VERSION ""

NS_ :

BS_:

BU_: Vector__XXX

BO_ 2432499198 EEC9: 8 Vector__XXX
SG_ EngExhstGasRecirc2ValvePos : 0|16@1+ (0.0025,0) [0|160.6375] "%" Vector__XXX
SG_ EngExhstGasRecirc2Valve2Pos : 16|16@1+ (0.0025,0) [0|160.6375] "%" Vector__XXX
SG_ CommandedEngineFuelRailPressure : 32|16@1+ (0.00390625,0) [0|250.996] "MPa" Vector__XXX
SG_ CmdedEngFuelInjectionCtrlPress : 48|16@1+ (0.00390625,0) [0|250.996] "MPa" Vector__XXX

BO_ 2633826046 EEC10: 8 Vector__XXX
SG_ EngExhstGasRecirc2CoolIntkTemp : 0|16@1+ (0.03125,-273) [-273|1734.96875] "deg C" Vector__XXX
SG_ EngExhstGsRecirc2ClIntkGsAbsPrs : 16|16@1+ (0.5,0) [0|32127.5] "kPa" Vector__XXX
SG_ EngExhstGasRecirculation2CoolEff : 32|8@1+ (0.4,0) [0|100] "%" Vector__XXX
SG_ EngExhstGasRecirc2ClBypssActrPos : 40|8@1+ (0.4,0) [0|100] "%" Vector__XXX
SG_ EngExhstGsRecirc2CoolIntkPress : 48|16@1+ (5,0) [0|321275] "kPa" Vector__XXX

BO_ 2566717438 ET5: 8 Vector__XXX
SG_ EngExhstGasRecirc2Temperature : 0|16@1+ (0.03125,-273) [-273|1734.96875] "deg C" Vector__XXX
SG_ EngExhstGasRecirc2MixerIntkTemp : 16|16@1+ (0.03125,-273) [-273|1734.96875] "deg C" Vector__XXX

BO_ 2499608830 EFL_P10: 8 Vector__XXX
SG_ EngExhstGasRecirc2DiffPress : 0|16@1+ (0.0078125,-250) [-250|251.99] "kPa" Vector__XXX
SG_ EngExhstGasRecirc2IntkPress : 16|8@1+ (2,0) [0|500] "kPa" Vector__XXX
SG_ EngExhstGasRecirc2OtltAbsPress : 24|16@1+ (0.1,0) [0|6425.5] "kPa" Vector__XXX
SG_ EngExhstGasRecirc2IntkAbsPress : 40|16@1+ (0.1,0) [0|6425.5] "kPa" Vector__XXX
SG_ EngineCoolantPressure2 : 56|8@1+ (2,0) [0|500] "kPa" Vector__XXX

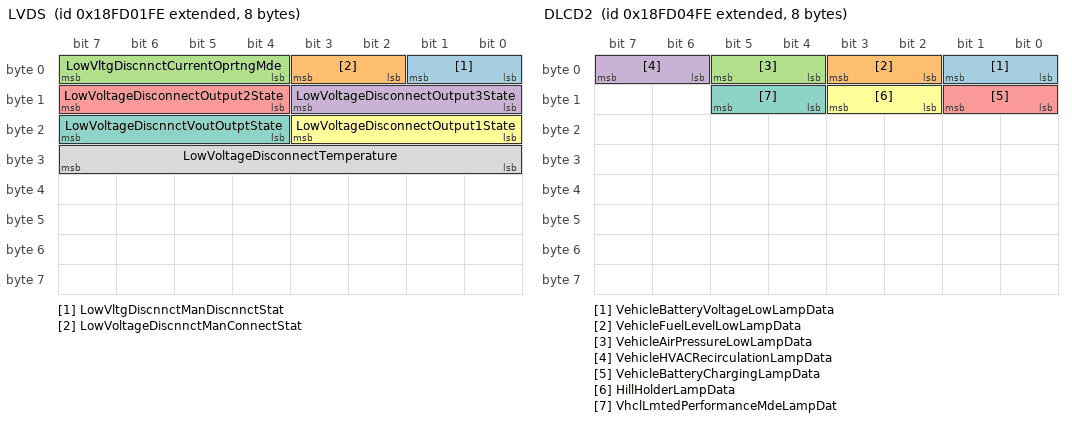
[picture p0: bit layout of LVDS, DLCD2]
BO_ 2566717950 LVDS: 8 Vector__XXX
SG_ LowVltgDiscnnctManDiscnnctStat : 0|2@1+ (1,0) [0|3] "" Vector__XXX
SG_ LowVoltageDiscnnctManConnectStat : 2|2@1+ (1,0) [0|3] "" Vector__XXX
SG_ LowVltgDiscnnctCurrentOprtngMde : 4|4@1+ (1,0) [0|15] "" Vector__XXX
SG_ LowVoltageDisconnectOutput3State : 8|4@1+ (1,0) [0|15] "" Vector__XXX
SG_ LowVoltageDisconnectOutput2State : 12|4@1+ (1,0) [0|15] "" Vector__XXX
SG_ LowVoltageDisconnectOutput1State : 16|4@1+ (1,0) [0|15] "" Vector__XXX
SG_ LowVoltageDiscnnctVoutOutptState : 20|4@1+ (1,0) [0|15] "" Vector__XXX
SG_ LowVoltageDisconnectTemperature : 24|8@1+ (1,-40) [-40|210] "deg C" Vector__XXX

BO_ 2566718206 AISO: 8 Vector__XXX
SG_ AllImplementStopOprtngOpsSwStat : 56|2@1+ (1,0) [0|3] "" Vector__XXX

BO_ 2566718462 IOS: 8 Vector__XXX
SG_ ImplementOperatingStateCommand : 56|2@1+ (1,0) [0|3] "" Vector__XXX

BO_ 2566718718 DLCD2: 8 Vector__XXX
SG_ VehicleBatteryVoltageLowLampData : 0|2@1+ (1,0) [0|3] "" Vector__XXX
SG_ VehicleFuelLevelLowLampData : 2|2@1+ (1,0) [0|3] "" Vector__XXX
SG_ VehicleAirPressureLowLampData : 4|2@1+ (1,0) [0|3] "" Vector__XXX
SG_ VehicleHVACRecirculationLampData : 6|2@1+ (1,0) [0|3] "" Vector__XXX
SG_ VehicleBatteryChargingLampData : 8|2@1+ (1,0) [0|3] "" Vector__XXX
SG_ HillHolderLampData : 10|2@1+ (1,0) [0|3] "" Vector__XXX
SG_ VhclLmtedPerformanceMdeLampDat : 12|2@1+ (1,0) [0|3] "" Vector__XXX

BO_ 2566718974 DLCD1: 8 Vector__XXX
SG_ EngineProtectLampData : 0|2@1+ (1,0) [0|3] "" Vector__XXX
SG_ EngineAmberWarningLampData : 2|2@1+ (1,0) [0|3] "" Vector__XXX
SG_ EngineRedStopLampData : 4|2@1+ (1,0) [0|3] "" Vector__XXX
SG_ OBDMalfunctionIndicatorLampData : 6|2@1+ (1,0) [0|3] "" Vector__XXX
SG_ EngineBrakeActiveLampData : 8|2@1+ (1,0) [0|3] "" Vector__XXX
SG_ ComPrsionBrkEnblSwIndictrLampDat : 10|2@1+ (1,0) [0|3] "" Vector__XXX
SG_ EngineOilPressureLowLampData : 12|2@1+ (1,0) [0|3] "" Vector__XXX
SG_ EngCoolntTemperatureHighLampDat : 14|2@1+ (1,0) [0|3] "" Vector__XXX
SG_ EngineCoolantLevelLowLampData : 16|2@1+ (1,0) [0|3] "" Vector__XXX
SG_ EngineIdleManagementActvLampData : 18|2@1+ (1,0) [0|3] "" Vector__XXX
SG_ EngAirFilterRestrictionLampDat : 20|2@1+ (1,0) [0|3] "" Vector__XXX
SG_ EngFuelFilterRestrictedLampDat : 22|2@1+ (1,0) [0|3] "" Vector__XXX
SG_ EngCtrlModule1ReadyForUseLampDat : 24|2@1+ (1,0) [0|3] "" Vector__XXX
SG_ EngCtrlModule2ReadyForUseLampDat : 26|2@1+ (1,0) [0|3] "" Vector__XXX
SG_ EngCtrlModule3ReadyForUseLampDat : 28|2@1+ (1,0) [0|3] "" Vector__XXX
SG_ EngineSpeedHighLampData : 30|2@1+ (1,0) [0|3] "" Vector__XXX
SG_ EngineSpeedVeryHighLampData : 32|2@1+ (1,0) [0|3] "" Vector__XXX
SG_ VehicleAccltnRateLimitLampData : 34|2@1+ (1,0) [0|3] "" Vector__XXX
SG_ EngStopStartAutoStopActvLampDat : 38|2@1+ (1,0) [0|3] "" Vector__XXX
SG_ EngStopStrtAutoStrtFailedLampDat : 40|2@1+ (1,0) [0|3] "" Vector__XXX
SG_ EngineStopStartEnabledLampData : 42|2@1+ (1,0) [0|3] "" Vector__XXX
SG_ EngineWaitToStartLampData : 62|2@1+ (1,0) [0|3] "" Vector__XXX

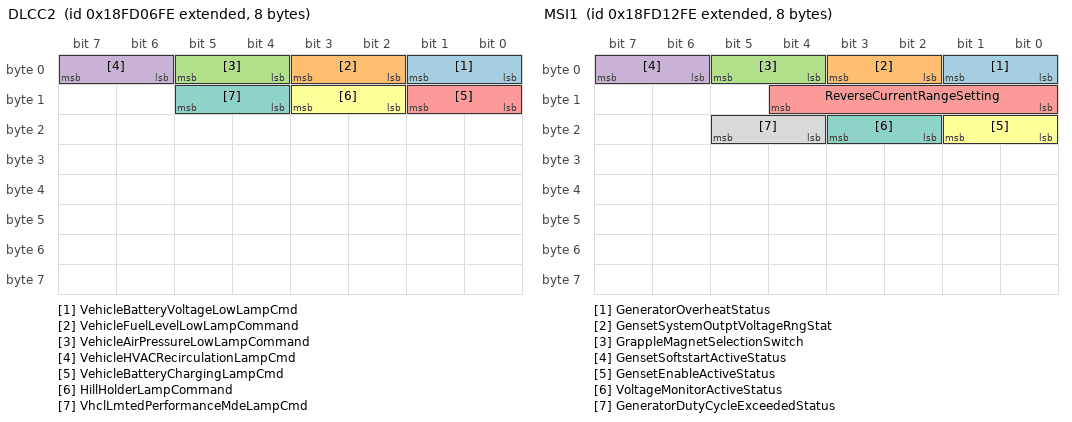
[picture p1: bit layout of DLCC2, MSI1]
BO_ 2566719230 DLCC2: 8 Vector__XXX
SG_ VehicleBatteryVoltageLowLampCmd : 0|2@1+ (1,0) [0|3] "" Vector__XXX
SG_ VehicleFuelLevelLowLampCommand : 2|2@1+ (1,0) [0|3] "" Vector__XXX
SG_ VehicleAirPressureLowLampCommand : 4|2@1+ (1,0) [0|3] "" Vector__XXX
SG_ VehicleHVACRecirculationLampCmd : 6|2@1+ (1,0) [0|3] "" Vector__XXX
SG_ VehicleBatteryChargingLampCmd : 8|2@1+ (1,0) [0|3] "" Vector__XXX
SG_ HillHolderLampCommand : 10|2@1+ (1,0) [0|3] "" Vector__XXX
SG_ VhclLmtedPerformanceMdeLampCmd : 12|2@1+ (1,0) [0|3] "" Vector__XXX

BO_ 2566719486 DLCC1: 8 Vector__XXX
SG_ EngineProtectLampCommand : 0|2@1+ (1,0) [0|3] "" Vector__XXX
SG_ EngineAmberWarningLampCommand : 2|2@1+ (1,0) [0|3] "" Vector__XXX
SG_ EngineRedStopLampCommand : 4|2@1+ (1,0) [0|3] "" Vector__XXX
SG_ OBDMalfunctionIndicatorLampCmd : 6|2@1+ (1,0) [0|3] "" Vector__XXX
SG_ EngineBrakeActiveLampCommand : 8|2@1+ (1,0) [0|3] "" Vector__XXX
SG_ ComPrsionBrkEnblSwIndictrLampCmd : 10|2@1+ (1,0) [0|3] "" Vector__XXX
SG_ EngineOilPressureLowLampCommand : 12|2@1+ (1,0) [0|3] "" Vector__XXX
SG_ EngCoolntTemperatureHighLampCmd : 14|2@1+ (1,0) [0|3] "" Vector__XXX
SG_ EngineCoolantLevelLowLampCommand : 16|2@1+ (1,0) [0|3] "" Vector__XXX
SG_ EngineIdleManagementActvLampCmd : 18|2@1+ (1,0) [0|3] "" Vector__XXX
SG_ EngAirFilterRestrictionLampCmd : 20|2@1+ (1,0) [0|3] "" Vector__XXX
SG_ EngFuelFilterRestrictedLampCmd : 22|2@1+ (1,0) [0|3] "" Vector__XXX
SG_ EngCtrlModule1ReadyForUseLampCmd : 24|2@1+ (1,0) [0|3] "" Vector__XXX
SG_ EngCtrlModule2ReadyForUseLampCmd : 26|2@1+ (1,0) [0|3] "" Vector__XXX
SG_ EngCtrlModule3ReadyForUseLampCmd : 28|2@1+ (1,0) [0|3] "" Vector__XXX
SG_ EngineSpeedHighLampCommand : 30|2@1+ (1,0) [0|3] "" Vector__XXX
SG_ EngineSpeedVeryHighLampCommand : 32|2@1+ (1,0) [0|3] "" Vector__XXX
SG_ VehicleAccltnRateLimitLampCmd : 34|2@1+ (1,0) [0|3] "" Vector__XXX
SG_ EngIdlMangmntPendingEvntLampCmd : 36|2@1+ (1,0) [0|3] "" Vector__XXX
SG_ EngStopStartAutoStopActvLampCmd : 38|2@1+ (1,0) [0|3] "" Vector__XXX
SG_ EngStopStrtAutoStrtFailedLampCmd : 40|2@1+ (1,0) [0|3] "" Vector__XXX
SG_ EngineStopStartEnabledLampCmd : 42|2@1+ (1,0) [0|3] "" Vector__XXX

BO_ 2633828606 EOM: 8 Vector__XXX
SG_ EngineOilViscosity : 0|16@1+ (0.015625,0) [0|1003.984375] "Cp" Vector__XXX
SG_ EngineOilDensity : 16|16@1+ (3.052E-005,0) [0|1.961] "g/cc" Vector__XXX
SG_ EngineOilRelativeDielectricity : 32|16@1+ (0.0001220703125,0) [0|7.844] "" Vector__XXX
SG_ EngineOilTemperature3 : 48|16@1+ (0.03125,-273) [-273|1734.96875] "deg C" Vector__XXX

BO_ 2566719998 HRLFC: 8 Vector__XXX
SG_ EngineTripFuel : 0|32@1+ (0.001,0) [0|4211081.215] "l" Vector__XXX
SG_ EngineTotalFuelUsed : 32|32@1+ (0.001,0) [0|4211081.215] "l" Vector__XXX

BO_ 2365393662 AT2OGC2: 8 Vector__XXX
SG_ Aft2OtltNOxSnsrO2PressCorrctn : 0|8@1+ (0.5,0) [0|125] "%/bar" Vector__XXX
SG_ Aft2OtltNOxSnsrNOxPressCorrctn : 8|8@1+ (0.5,0) [0|125] "%/bar" Vector__XXX
SG_ Aftrtrtmnt2OtltNOxSnsrNO2Corrctn : 16|8@1+ (0.5,0) [0|125] "%" Vector__XXX
SG_ Aftrtrtmnt2OtltNOxSnsrNH3Corrctn : 24|8@1+ (0.5,0) [0|125] "%" Vector__XXX
SG_ Aft2OtltNOxSnsrSelfDiagssFinalRs : 32|8@1+ (1,0) [0|250] "" Vector__XXX
SG_ Aftrtrtmnt2OutletCorrectedNOx : 40|16@1+ (0.05,-200) [-200|3012.75] "ppm" Vector__XXX

BO_ 2365393918 AT2OGC1: 8 Vector__XXX
SG_ Aftrtrtmnt2OtltNOxSensorHtrRatio : 0|16@1+ (0.001,0) [0|64.255] "" Vector__XXX
SG_ Aft2OtltNOxSnsrNwPrtDviatNOxGain : 16|16@1+ (0.1,-100) [-100|6325.5] "%" Vector__XXX
SG_ Aft2OtltNOxSnsrNPDviatNOxOffst : 32|8@1+ (1,-125) [-125|125] "ppm" Vector__XXX
SG_ Aftrtrtmnt2OtltNOxSensorOpHours : 40|16@1+ (1,0) [0|64255] "h" Vector__XXX

BO_ 2365394174 AT2IGC2: 8 Vector__XXX
SG_ EngExhst2IntkNOxSnsrO2PrsCorrctn : 0|8@1+ (0.5,0) [0|125] "%/bar" Vector__XXX
SG_ EngExhst2IntkNOxSnsrNOxPrsCorrcn : 8|8@1+ (0.5,0) [0|125] "%/bar" Vector__XXX
SG_ EngExhst2IntkNOxSensorNO2Corrctn : 16|8@1+ (0.5,0) [0|125] "%" Vector__XXX
SG_ EngExhst2IntkNOxSensorNH3Corrctn : 24|8@1+ (0.5,0) [0|125] "%" Vector__XXX
SG_ EngExhst2IntkNOxSnsrSelfDgFiRes : 32|8@1+ (1,0) [0|250] "" Vector__XXX
SG_ EngineExhaust2CorrectedNox : 40|16@1+ (0.05,-200) [-200|3012.75] "ppm" Vector__XXX

BO_ 2365394430 AT2IGC1: 8 Vector__XXX
SG_ EngExhst2IntakeNOxSensorHtrRatio : 0|16@1+ (0.001,0) [0|64.255] "" Vector__XXX
SG_ EngExhst2IntkNOxSnsrNPDvNOxGain : 16|16@1+ (0.1,-100) [-100|6325.5] "%" Vector__XXX
SG_ EngExhst2IntkNOxSnsrNPDvNOxOffst : 32|8@1+ (1,-125) [-125|125] "ppm" Vector__XXX
SG_ EngExhst2IntkNOxSensorOpHrs : 40|16@1+ (1,0) [0|64255] "h" Vector__XXX

BO_ 2365394686 AT1OGC2: 8 Vector__XXX
SG_ Aft1OtltNOxSnsrO2PressCorrctn : 0|8@1+ (0.5,0) [0|125] "%/bar" Vector__XXX
SG_ Aft1OtltNOxSnsrNOxPressCorrctn : 8|8@1+ (0.5,0) [0|125] "%/bar" Vector__XXX
SG_ Aftrtrtmnt1OtltNOxSnsrNO2Corrctn : 16|8@1+ (0.5,0) [0|125] "%" Vector__XXX
SG_ Aftrtrtmnt1OtltNOxSnsrNH3Corrctn : 24|8@1+ (0.5,0) [0|125] "%" Vector__XXX
SG_ Aft1OtltNOxSnsrSelfDiagssFinalRs : 32|8@1+ (1,0) [0|250] "" Vector__XXX
SG_ Aftrtrtmnt1OutletCorrectedNOx : 40|16@1+ (0.05,-200) [-200|3012.75] "ppm" Vector__XXX

BO_ 2365394942 AT1OGC1: 8 Vector__XXX
SG_ Aftrtrtmnt1OtltNOxSensorHtrRatio : 0|16@1+ (0.001,0) [0|64.255] "" Vector__XXX
SG_ Aft1OtltNOxSnsrNwPrtDviatNOxGain : 16|16@1+ (0.1,-100) [-100|6325.5] "%" Vector__XXX
SG_ Aft1OtltNOxSnsrNPDviatNOxOffst : 32|8@1+ (1,-125) [-125|125] "ppm" Vector__XXX
SG_ Aftrtrtmnt1OtltNOxSensorOpHours : 40|16@1+ (1,0) [0|64255] "h" Vector__XXX

BO_ 2365395198 AT1IGC2: 8 Vector__XXX
SG_ EngExhst1NOxSensorO2PressCorrctn : 0|8@1+ (0.5,0) [0|125] "%/bar" Vector__XXX
SG_ EngExhst1NOxSnsrNOxPressCorrctn : 8|8@1+ (0.5,0) [0|125] "%/bar" Vector__XXX
SG_ EngExhaust1NOxSensorNO2Corrctn : 16|8@1+ (0.5,0) [0|125] "%" Vector__XXX
SG_ EngExhaust1NOxSensorNH3Corrctn : 24|8@1+ (0.5,0) [0|125] "%" Vector__XXX
SG_ EngExhst1NOxSnsrSelfDiagFinlRes : 32|8@1+ (1,0) [0|250] "" Vector__XXX
SG_ EngineExhaust1CorrectedNox : 40|16@1+ (0.05,-200) [-200|3012.75] "ppm" Vector__XXX

BO_ 2365395454 AT1IGC1: 8 Vector__XXX
SG_ EngExhaust1NOxSensorHeaterRatio : 0|16@1+ (0.001,0) [0|64.255] "" Vector__XXX
SG_ EngExhst1NOxSnsrNwPrtDvNOxGain : 16|16@1+ (0.1,-100) [-100|6325.5] "%" Vector__XXX
SG_ EngExhst1NOxSnsrNwPrtDvNOxOffst : 32|8@1+ (1,-125) [-125|125] "ppm" Vector__XXX
SG_ EngExhst1NOxSensorOperationHours : 40|16@1+ (1,0) [0|64255] "h" Vector__XXX

BO_ 2566722302 MSI1: 8 Vector__XXX
SG_ GeneratorOverheatStatus : 0|2@1+ (1,0) [0|3] "" Vector__XXX
SG_ GensetSystemOutptVoltageRngStat : 2|2@1+ (1,0) [0|3] "" Vector__XXX
SG_ GrappleMagnetSelectionSwitch : 4|2@1+ (1,0) [0|3] "" Vector__XXX
SG_ GensetSoftstartActiveStatus : 6|2@1+ (1,0) [0|3] "" Vector__XXX
SG_ ReverseCurrentRangeSetting : 8|5@1+ (1,0) [0|31] "" Vector__XXX
SG_ GensetEnableActiveStatus : 16|2@1+ (1,0) [0|3] "" Vector__XXX
SG_ VoltageMonitorActiveStatus : 18|2@1+ (1,0) [0|3] "" Vector__XXX
SG_ GeneratorDutyCycleExceededStatus : 20|2@1+ (1,0) [0|3] "" Vector__XXX

BO_ 2566722558 MSCI: 8 Vector__XXX
SG_ MagnetBoostTime : 0|8@1+ (0.25,0) [0|62.5] "s" Vector__XXX
SG_ MagnetRatedPower : 8|16@1+ (0.5,0) [0|32127.5] "kW" Vector__XXX

BO_ 2566722814 BCH2: 8 Vector__XXX
SG_ BatteryCharger2State : 0|4@1+ (1,0) [0|15] "" Vector__XXX
SG_ BatteryCharger2PowerLineState : 4|2@1+ (1,0) [0|3] "" Vector__XXX
SG_ BatteryCharger2OutputVoltage : 8|16@1+ (0.05,0) [0|3212.75] "V" Vector__XXX
SG_ BatteryCharger2OutputCurrent : 24|16@1+ (0.05,-1600) [-1600|1612.75] "A" Vector__XXX

BO_ 2566723070 BCH1: 8 Vector__XXX
SG_ BatteryCharger1State : 0|4@1+ (1,0) [0|15] "" Vector__XXX
SG_ BatteryCharger1PowerLineState : 4|2@1+ (1,0) [0|3] "" Vector__XXX
SG_ BatteryCharger1OutputVoltage : 8|16@1+ (0.05,0) [0|3212.75] "V" Vector__XXX
SG_ BatteryCharger1OutputCurrent : 24|16@1+ (0.05,-1600) [-1600|1612.75] "A" Vector__XXX

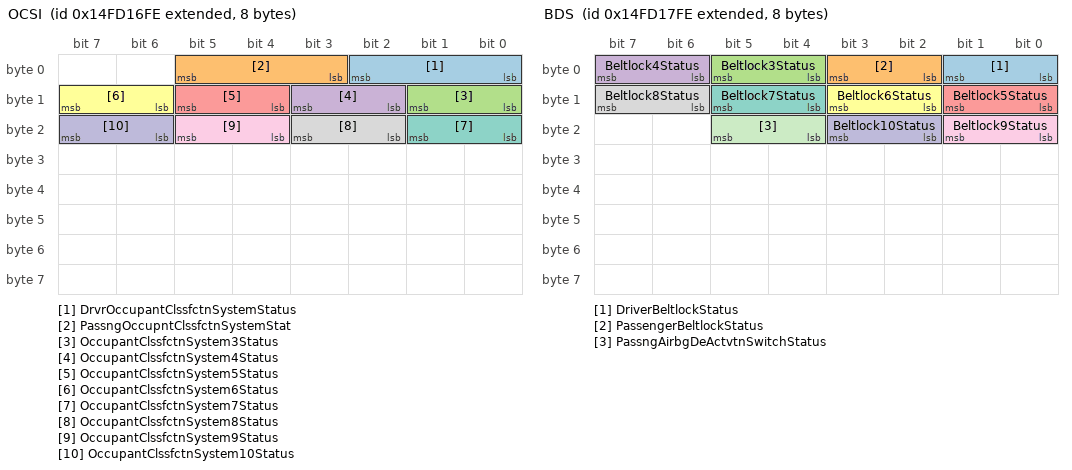
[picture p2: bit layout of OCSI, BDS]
BO_ 2499614462 OCSI: 8 Vector__XXX
SG_ DrvrOccupantClssfctnSystemStatus : 0|3@1+ (1,0) [0|7] "" Vector__XXX
SG_ PassngOccupntClssfctnSystemStat : 3|3@1+ (1,0) [0|7] "" Vector__XXX
SG_ OccupantClssfctnSystem3Status : 8|2@1+ (1,0) [0|3] "" Vector__XXX
SG_ OccupantClssfctnSystem4Status : 10|2@1+ (1,0) [0|3] "" Vector__XXX
SG_ OccupantClssfctnSystem5Status : 12|2@1+ (1,0) [0|3] "" Vector__XXX
SG_ OccupantClssfctnSystem6Status : 14|2@1+ (1,0) [0|3] "" Vector__XXX
SG_ OccupantClssfctnSystem7Status : 16|2@1+ (1,0) [0|3] "" Vector__XXX
SG_ OccupantClssfctnSystem8Status : 18|2@1+ (1,0) [0|3] "" Vector__XXX
SG_ OccupantClssfctnSystem9Status : 20|2@1+ (1,0) [0|3] "" Vector__XXX
SG_ OccupantClssfctnSystem10Status : 22|2@1+ (1,0) [0|3] "" Vector__XXX

BO_ 2499614718 BDS: 8 Vector__XXX
SG_ DriverBeltlockStatus : 0|2@1+ (1,0) [0|3] "" Vector__XXX
SG_ PassengerBeltlockStatus : 2|2@1+ (1,0) [0|3] "" Vector__XXX
SG_ Beltlock3Status : 4|2@1+ (1,0) [0|3] "" Vector__XXX
SG_ Beltlock4Status : 6|2@1+ (1,0) [0|3] "" Vector__XXX
SG_ Beltlock5Status : 8|2@1+ (1,0) [0|3] "" Vector__XXX
SG_ Beltlock6Status : 10|2@1+ (1,0) [0|3] "" Vector__XXX
SG_ Beltlock7Status : 12|2@1+ (1,0) [0|3] "" Vector__XXX
SG_ Beltlock8Status : 14|2@1+ (1,0) [0|3] "" Vector__XXX
SG_ Beltlock9Status : 16|2@1+ (1,0) [0|3] "" Vector__XXX
SG_ Beltlock10Status : 18|2@1+ (1,0) [0|3] "" Vector__XXX
SG_ PassngAirbgDeActvtnSwitchStatus : 20|2@1+ (1,0) [0|3] "" Vector__XXX

BO_ 2633832702 CSI: 9 Vector__XXX
SG_ FrontalCollisionSensor1Type : 0|4@1+ (1,0) [0|15] "" Vector__XXX
SG_ FrontalCollisionSensor2Type : 4|4@1+ (1,0) [0|15] "" Vector__XXX
SG_ FrontalCollisionSensor3Type : 8|4@1+ (1,0) [0|15] "" Vector__XXX
SG_ FrontalCollisionSensor4Type : 12|4@1+ (1,0) [0|15] "" Vector__XXX
SG_ SideCollisionSensorFrontLeftType : 16|4@1+ (1,0) [0|15] "" Vector__XXX
SG_ SideCollsnSensorMidFrontLeftType : 20|4@1+ (1,0) [0|15] "" Vector__XXX
SG_ SideCollsnSensorMidRearLeftType : 24|4@1+ (1,0) [0|15] "" Vector__XXX
SG_ SideCollisionSensorRearLeftType : 28|4@1+ (1,0) [0|15] "" Vector__XXX
SG_ SideCollsnSensorFrontRightType : 32|4@1+ (1,0) [0|15] "" Vector__XXX
SG_ SideCollsnSensorMidFrntRightType : 36|4@1+ (1,0) [0|15] "" Vector__XXX
SG_ SideCollsnSensorMidRearRightType : 40|4@1+ (1,0) [0|15] "" Vector__XXX
SG_ SideCollisionSensorRearRightType : 44|4@1+ (1,0) [0|15] "" Vector__XXX
SG_ RearCollisionSensor1Type : 48|4@1+ (1,0) [0|15] "" Vector__XXX
SG_ RearCollisionSensor2Type : 52|4@1+ (1,0) [0|15] "" Vector__XXX
SG_ RearCollisionSensor3Type : 56|4@1+ (1,0) [0|15] "" Vector__XXX
SG_ RearCollisionSensor4Type : 60|4@1+ (1,0) [0|15] "" Vector__XXX
SG_ RolloverSensorType : 64|4@1+ (1,0) [0|15] "" Vector__XXX

BO_ 2633832958 ILI: 200 Vector__XXX
SG_ DrvrAirbgIgntrLp1stStageResist : 0|16@1+ (0.1,0) [0|6425.5] "ohm" Vector__XXX
SG_ PassngAirbgIgntrLp1stStageResist : 16|16@1+ (0.1,0) [0|6425.5] "ohm" Vector__XXX
SG_ DrvrAirbgIgntrLp2ndStageResist : 32|16@1+ (0.1,0) [0|6425.5] "ohm" Vector__XXX
SG_ PassngAirbgIgntrLp2ndStageResist : 48|16@1+ (0.1,0) [0|6425.5] "ohm" Vector__XXX
SG_ DrvrBeltTensionerIgntrLpResist : 64|16@1+ (0.1,0) [0|6425.5] "ohm" Vector__XXX
SG_ PassngBeltTensionerIgntrLpResist : 80|16@1+ (0.1,0) [0|6425.5] "ohm" Vector__XXX
SG_ SideBagIgntrLoop1LeftResistance : 96|16@1+ (0.1,0) [0|6425.5] "ohm" Vector__XXX
SG_ SideBagIgntrLoop2LeftResistance : 112|16@1+ (0.1,0) [0|6425.5] "ohm" Vector__XXX
SG_ SideBagIgntrLoop1RightResistance : 128|16@1+ (0.1,0) [0|6425.5] "ohm" Vector__XXX
SG_ SideBagIgntrLoop2RightResistance : 144|16@1+ (0.1,0) [0|6425.5] "ohm" Vector__XXX
SG_ SpecialIgnitorLoop1Resistance : 160|16@1+ (0.1,0) [0|6425.5] "ohm" Vector__XXX
SG_ SpecialIgnitorLoop2Resistance : 176|16@1+ (0.1,0) [0|6425.5] "ohm" Vector__XXX
SG_ SpecialIgnitorLoop3Resistance : 192|16@1+ (0.1,0) [0|6425.5] "ohm" Vector__XXX
SG_ SpecialIgnitorLoop4Resistance : 208|16@1+ (0.1,0) [0|6425.5] "ohm" Vector__XXX
SG_ SpecialIgnitorLoop5Resistance : 224|16@1+ (0.1,0) [0|6425.5] "ohm" Vector__XXX
SG_ SpecialIgnitorLoop6Resistance : 240|16@1+ (0.1,0) [0|6425.5] "ohm" Vector__XXX
SG_ SpecialIgnitorLoop7Resistance : 256|16@1+ (0.1,0) [0|6425.5] "ohm" Vector__XXX
SG_ SpecialIgnitorLoop8Resistance : 272|16@1+ (0.1,0) [0|6425.5] "ohm" Vector__XXX
SG_ SpecialIgnitorLoop9Resistance : 288|16@1+ (0.1,0) [0|6425.5] "ohm" Vector__XXX
SG_ SpecialIgnitorLoop10Resistance : 304|16@1+ (0.1,0) [0|6425.5] "ohm" Vector__XXX
SG_ SpecialIgnitorLoop11Resistance : 320|16@1+ (0.1,0) [0|6425.5] "ohm" Vector__XXX
SG_ SpecialIgnitorLoop12Resistance : 336|16@1+ (0.1,0) [0|6425.5] "ohm" Vector__XXX
SG_ SpecialIgnitorLoop13Resistance : 352|16@1+ (0.1,0) [0|6425.5] "ohm" Vector__XXX
SG_ SpecialIgnitorLoop14Resistance : 368|16@1+ (0.1,0) [0|6425.5] "ohm" Vector__XXX
SG_ SpecialIgnitorLoop15Resistance : 384|16@1+ (0.1,0) [0|6425.5] "ohm" Vector__XXX
SG_ SpecialIgnitorLoop16Resistance : 400|16@1+ (0.1,0) [0|6425.5] "ohm" Vector__XXX
SG_ SpecialIgnitorLoop17Resistance : 416|16@1+ (0.1,0) [0|6425.5] "ohm" Vector__XXX
SG_ SpecialIgnitorLoop18Resistance : 432|16@1+ (0.1,0) [0|6425.5] "ohm" Vector__XXX
SG_ SpecialIgnitorLoop19Resistance : 448|16@1+ (0.1,0) [0|6425.5] "ohm" Vector__XXX
SG_ SpecialIgnitorLoop20Resistance : 464|16@1+ (0.1,0) [0|6425.5] "ohm" Vector__XXX
SG_ SpecialIgnitorLoop21Resistance : 480|16@1+ (0.1,0) [0|6425.5] "ohm" Vector__XXX
SG_ SpecialIgnitorLoop22Resistance : 496|16@1+ (0.1,0) [0|6425.5] "ohm" Vector__XXX
SG_ SpecialIgnitorLoop23Resistance : 512|16@1+ (0.1,0) [0|6425.5] "ohm" Vector__XXX
SG_ SpecialIgnitorLoop24Resistance : 528|16@1+ (0.1,0) [0|6425.5] "ohm" Vector__XXX
SG_ SpecialIgnitorLoop25Resistance : 544|16@1+ (0.1,0) [0|6425.5] "ohm" Vector__XXX
SG_ SpecialIgnitorLoop26Resistance : 560|16@1+ (0.1,0) [0|6425.5] "ohm" Vector__XXX
SG_ SpecialIgnitorLoop27Resistance : 576|16@1+ (0.1,0) [0|6425.5] "ohm" Vector__XXX
SG_ SpecialIgnitorLoop28Resistance : 592|16@1+ (0.1,0) [0|6425.5] "ohm" Vector__XXX
SG_ SpecialIgnitorLoop29Resistance : 608|16@1+ (0.1,0) [0|6425.5] "ohm" Vector__XXX
SG_ SpecialIgnitorLoop30Resistance : 624|16@1+ (0.1,0) [0|6425.5] "ohm" Vector__XXX
SG_ SpecialIgnitorLoop31Resistance : 640|16@1+ (0.1,0) [0|6425.5] "ohm" Vector__XXX
SG_ SpecialIgnitorLoop32Resistance : 656|16@1+ (0.1,0) [0|6425.5] "ohm" Vector__XXX
SG_ SpecialIgnitorLoop33Resistance : 672|16@1+ (0.1,0) [0|6425.5] "ohm" Vector__XXX
SG_ SpecialIgnitorLoop34Resistance : 688|16@1+ (0.1,0) [0|6425.5] "ohm" Vector__XXX
SG_ SpecialIgnitorLoop35Resistance : 704|16@1+ (0.1,0) [0|6425.5] "ohm" Vector__XXX
SG_ SpecialIgnitorLoop36Resistance : 720|16@1+ (0.1,0) [0|6425.5] "ohm" Vector__XXX
SG_ SpecialIgnitorLoop37Resistance : 736|16@1+ (0.1,0) [0|6425.5] "ohm" Vector__XXX
SG_ SpecialIgnitorLoop38Resistance : 752|16@1+ (0.1,0) [0|6425.5] "ohm" Vector__XXX
SG_ SpecialIgnitorLoop39Resistance : 768|16@1+ (0.1,0) [0|6425.5] "ohm" Vector__XXX
SG_ SpecialIgnitorLoop40Resistance : 784|16@1+ (0.1,0) [0|6425.5] "ohm" Vector__XXX
SG_ SpecialIgnitorLoop41Resistance : 800|16@1+ (0.1,0) [0|6425.5] "ohm" Vector__XXX
SG_ SpecialIgnitorLoop42Resistance : 816|16@1+ (0.1,0) [0|6425.5] "ohm" Vector__XXX
SG_ SpecialIgnitorLoop43Resistance : 832|16@1+ (0.1,0) [0|6425.5] "ohm" Vector__XXX
SG_ SpecialIgnitorLoop44Resistance : 848|16@1+ (0.1,0) [0|6425.5] "ohm" Vector__XXX
SG_ SpecialIgnitorLoop45Resistance : 864|16@1+ (0.1,0) [0|6425.5] "ohm" Vector__XXX
SG_ SpecialIgnitorLoop46Resistance : 880|16@1+ (0.1,0) [0|6425.5] "ohm" Vector__XXX
SG_ SpecialIgnitorLoop47Resistance : 896|16@1+ (0.1,0) [0|6425.5] "ohm" Vector__XXX
SG_ SpecialIgnitorLoop48Resistance : 912|16@1+ (0.1,0) [0|6425.5] "ohm" Vector__XXX
SG_ SpecialIgnitorLoop49Resistance : 928|16@1+ (0.1,0) [0|6425.5] "ohm" Vector__XXX
SG_ SpecialIgnitorLoop50Resistance : 944|16@1+ (0.1,0) [0|6425.5] "ohm" Vector__XXX
SG_ SpecialIgnitorLoop51Resistance : 960|16@1+ (0.1,0) [0|6425.5] "ohm" Vector__XXX
SG_ SpecialIgnitorLoop52Resistance : 976|16@1+ (0.1,0) [0|6425.5] "ohm" Vector__XXX
SG_ SpecialIgnitorLoop53Resistance : 992|16@1+ (0.1,0) [0|6425.5] "ohm" Vector__XXX
SG_ SpecialIgnitorLoop54Resistance : 1008|16@1+ (0.1,0) [0|6425.5] "ohm" Vector__XXX
SG_ SpecialIgnitorLoop55Resistance : 1024|16@1+ (0.1,0) [0|6425.5] "ohm" Vector__XXX
SG_ SpecialIgnitorLoop56Resistance : 1040|16@1+ (0.1,0) [0|6425.5] "ohm" Vector__XXX
SG_ SpecialIgnitorLoop57Resistance : 1056|16@1+ (0.1,0) [0|6425.5] "ohm" Vector__XXX
SG_ SpecialIgnitorLoop58Resistance : 1072|16@1+ (0.1,0) [0|6425.5] "ohm" Vector__XXX
SG_ SpecialIgnitorLoop59Resistance : 1088|16@1+ (0.1,0) [0|6425.5] "ohm" Vector__XXX
SG_ SpecialIgnitorLoop60Resistance : 1104|16@1+ (0.1,0) [0|6425.5] "ohm" Vector__XXX
SG_ SpecialIgnitorLoop61Resistance : 1120|16@1+ (0.1,0) [0|6425.5] "ohm" Vector__XXX
SG_ SpecialIgnitorLoop62Resistance : 1136|16@1+ (0.1,0) [0|6425.5] "ohm" Vector__XXX
SG_ SpecialIgnitorLoop63Resistance : 1152|16@1+ (0.1,0) [0|6425.5] "ohm" Vector__XXX
SG_ SpecialIgnitorLoop64Resistance : 1168|16@1+ (0.1,0) [0|6425.5] "ohm" Vector__XXX
SG_ SpecialIgnitorLoop65Resistance : 1184|16@1+ (0.1,0) [0|6425.5] "ohm" Vector__XXX
SG_ SpecialIgnitorLoop66Resistance : 1200|16@1+ (0.1,0) [0|6425.5] "ohm" Vector__XXX
SG_ SpecialIgnitorLoop67Resistance : 1216|16@1+ (0.1,0) [0|6425.5] "ohm" Vector__XXX
SG_ SpecialIgnitorLoop68Resistance : 1232|16@1+ (0.1,0) [0|6425.5] "ohm" Vector__XXX
SG_ SpecialIgnitorLoop69Resistance : 1248|16@1+ (0.1,0) [0|6425.5] "ohm" Vector__XXX
SG_ SpecialIgnitorLoop70Resistance : 1264|16@1+ (0.1,0) [0|6425.5] "ohm" Vector__XXX
SG_ SpecialIgnitorLoop71Resistance : 1280|16@1+ (0.1,0) [0|6425.5] "ohm" Vector__XXX
SG_ SpecialIgnitorLoop72Resistance : 1296|16@1+ (0.1,0) [0|6425.5] "ohm" Vector__XXX
SG_ SpecialIgnitorLoop73Resistance : 1312|16@1+ (0.1,0) [0|6425.5] "ohm" Vector__XXX
SG_ SpecialIgnitorLoop74Resistance : 1328|16@1+ (0.1,0) [0|6425.5] "ohm" Vector__XXX
SG_ SpecialIgnitorLoop75Resistance : 1344|16@1+ (0.1,0) [0|6425.5] "ohm" Vector__XXX
SG_ SpecialIgnitorLoop76Resistance : 1360|16@1+ (0.1,0) [0|6425.5] "ohm" Vector__XXX
SG_ SpecialIgnitorLoop77Resistance : 1376|16@1+ (0.1,0) [0|6425.5] "ohm" Vector__XXX
SG_ SpecialIgnitorLoop78Resistance : 1392|16@1+ (0.1,0) [0|6425.5] "ohm" Vector__XXX
SG_ SpecialIgnitorLoop79Resistance : 1408|16@1+ (0.1,0) [0|6425.5] "ohm" Vector__XXX
SG_ SpecialIgnitorLoop80Resistance : 1424|16@1+ (0.1,0) [0|6425.5] "ohm" Vector__XXX
SG_ SpecialIgnitorLoop81Resistance : 1440|16@1+ (0.1,0) [0|6425.5] "ohm" Vector__XXX
SG_ SpecialIgnitorLoop82Resistance : 1456|16@1+ (0.1,0) [0|6425.5] "ohm" Vector__XXX
SG_ SpecialIgnitorLoop83Resistance : 1472|16@1+ (0.1,0) [0|6425.5] "ohm" Vector__XXX
SG_ SpecialIgnitorLoop84Resistance : 1488|16@1+ (0.1,0) [0|6425.5] "ohm" Vector__XXX
SG_ SpecialIgnitorLoop85Resistance : 1504|16@1+ (0.1,0) [0|6425.5] "ohm" Vector__XXX
SG_ SpecialIgnitorLoop86Resistance : 1520|16@1+ (0.1,0) [0|6425.5] "ohm" Vector__XXX
SG_ SpecialIgnitorLoop87Resistance : 1536|16@1+ (0.1,0) [0|6425.5] "ohm" Vector__XXX
SG_ SpecialIgnitorLoop88Resistance : 1552|16@1+ (0.1,0) [0|6425.5] "ohm" Vector__XXX
SG_ SpecialIgnitorLoop89Resistance : 1568|16@1+ (0.1,0) [0|6425.5] "ohm" Vector__XXX
SG_ SpecialIgnitorLoop90Resistance : 1584|16@1+ (0.1,0) [0|6425.5] "ohm" Vector__XXX

BO_ 2566724350 AT1WUDOC: 8 Vector__XXX
SG_ Aft1WarmUpDslOxidtnCtlystIntkTmp : 0|16@1+ (0.03125,-273) [-273|1734.96875] "deg C" Vector__XXX
SG_ Aft1WarmUpDslOxidtnCtlystOtltTmp : 16|16@1+ (0.03125,-273) [-273|1734.96875] "deg C" Vector__XXX

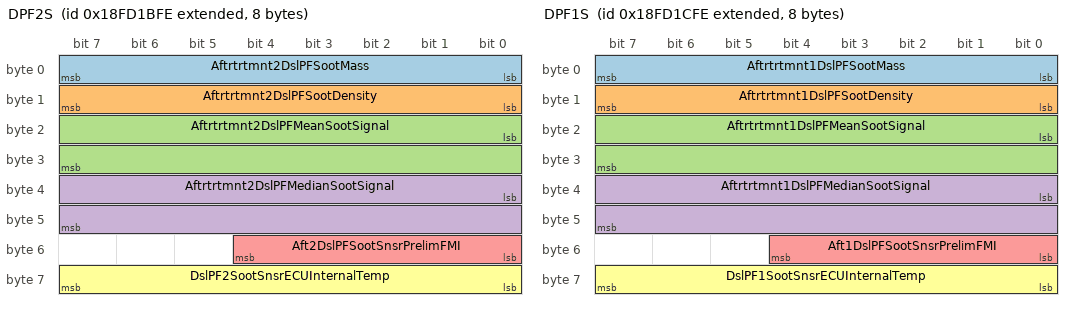
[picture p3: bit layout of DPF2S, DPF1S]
BO_ 2566724606 DPF2S: 8 Vector__XXX
SG_ Aftrtrtmnt2DslPFSootMass : 0|8@1+ (4,0) [0|1000] "g" Vector__XXX
SG_ Aftrtrtmnt2DslPFSootDensity : 8|8@1+ (0.08,0) [0|20] "g/L" Vector__XXX
SG_ Aftrtrtmnt2DslPFMeanSootSignal : 16|16@1+ (0.0025,0) [0|160.6375] "%" Vector__XXX
SG_ Aftrtrtmnt2DslPFMedianSootSignal : 32|16@1+ (0.0025,0) [0|160.6375] "%" Vector__XXX
SG_ Aft2DslPFSootSnsrPrelimFMI : 48|5@1+ (1,0) [0|31] "" Vector__XXX
SG_ DslPF2SootSnsrECUInternalTemp : 56|8@1+ (1,-40) [-40|210] "deg C" Vector__XXX

BO_ 2566724862 DPF1S: 8 Vector__XXX
SG_ Aftrtrtmnt1DslPFSootMass : 0|8@1+ (4,0) [0|1000] "g" Vector__XXX
SG_ Aftrtrtmnt1DslPFSootDensity : 8|8@1+ (0.08,0) [0|20] "g/L" Vector__XXX
SG_ Aftrtrtmnt1DslPFMeanSootSignal : 16|16@1+ (0.0025,0) [0|160.6375] "%" Vector__XXX
SG_ Aftrtrtmnt1DslPFMedianSootSignal : 32|16@1+ (0.0025,0) [0|160.6375] "%" Vector__XXX
SG_ Aft1DslPFSootSnsrPrelimFMI : 48|5@1+ (1,0) [0|31] "" Vector__XXX
SG_ DslPF1SootSnsrECUInternalTemp : 56|8@1+ (1,-40) [-40|210] "deg C" Vector__XXX

BO_ 2566725118 ATDT2: 8 Vector__XXX
SG_ Aftrtrtmnt13WyCtlystDiffTemp : 0|16@1+ (0.03125,-273) [-273|1734.96875] "deg C" Vector__XXX
SG_ Aftrtrtmnt23WyCtlystDiffTemp : 16|16@1+ (0.03125,-273) [-273|1734.96875] "deg C" Vector__XXX

BO_ 2566725374 ATDT1: 8 Vector__XXX
SG_ Aft1GasOxidtnCtlystDiffTemp : 0|16@1+ (0.03125,-273) [-273|1734.96875] "deg C" Vector__XXX
SG_ Aft2GasOxidtnCtlystDiffTemp : 16|16@1+ (0.03125,-273) [-273|1734.96875] "deg C" Vector__XXX

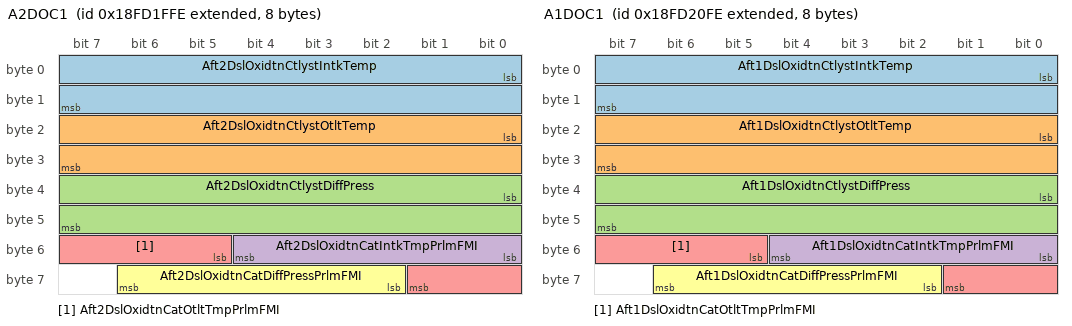
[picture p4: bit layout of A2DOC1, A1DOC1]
BO_ 2566725630 A2DOC1: 8 Vector__XXX
SG_ Aft2DslOxidtnCtlystIntkTemp : 0|16@1+ (0.03125,-273) [-273|1734.96875] "deg C" Vector__XXX
SG_ Aft2DslOxidtnCtlystOtltTemp : 16|16@1+ (0.03125,-273) [-273|1734.96875] "deg C" Vector__XXX
SG_ Aft2DslOxidtnCtlystDiffPress : 32|16@1+ (0.5,0) [0|32127.5] "kPa" Vector__XXX
SG_ Aft2DslOxidtnCatIntkTmpPrlmFMI : 48|5@1+ (1,0) [0|31] "" Vector__XXX
SG_ Aft2DslOxidtnCatOtltTmpPrlmFMI : 53|5@1+ (1,0) [0|31] "" Vector__XXX
SG_ Aft2DslOxidtnCatDiffPressPrlmFMI : 58|5@1+ (1,0) [0|31] "" Vector__XXX

BO_ 2566725886 A1DOC1: 8 Vector__XXX
SG_ Aft1DslOxidtnCtlystIntkTemp : 0|16@1+ (0.03125,-273) [-273|1734.96875] "deg C" Vector__XXX
SG_ Aft1DslOxidtnCtlystOtltTemp : 16|16@1+ (0.03125,-273) [-273|1734.96875] "deg C" Vector__XXX
SG_ Aft1DslOxidtnCtlystDiffPress : 32|16@1+ (0.1,0) [0|6425.5] "kPa" Vector__XXX
SG_ Aft1DslOxidtnCatIntkTmpPrlmFMI : 48|5@1+ (1,0) [0|31] "" Vector__XXX
SG_ Aft1DslOxidtnCatOtltTmpPrlmFMI : 53|5@1+ (1,0) [0|31] "" Vector__XXX
SG_ Aft1DslOxidtnCatDiffPressPrlmFMI : 58|5@1+ (1,0) [0|31] "" Vector__XXX

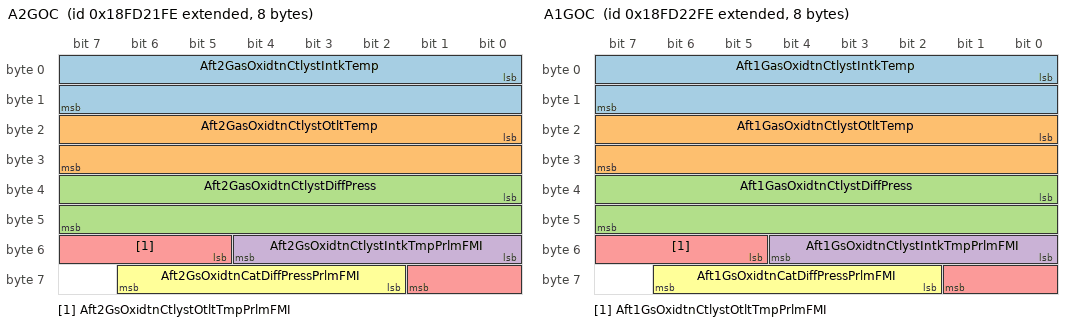
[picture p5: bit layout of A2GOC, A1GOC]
BO_ 2566726142 A2GOC: 8 Vector__XXX
SG_ Aft2GasOxidtnCtlystIntkTemp : 0|16@1+ (0.03125,-273) [-273|1734.96875] "deg C" Vector__XXX
SG_ Aft2GasOxidtnCtlystOtltTemp : 16|16@1+ (0.03125,-273) [-273|1734.96875] "deg C" Vector__XXX
SG_ Aft2GasOxidtnCtlystDiffPress : 32|16@1+ (0.1,0) [0|6425.5] "kPa" Vector__XXX
SG_ Aft2GsOxidtnCtlystIntkTmpPrlmFMI : 48|5@1+ (1,0) [0|31] "" Vector__XXX
SG_ Aft2GsOxidtnCtlystOtltTmpPrlmFMI : 53|5@1+ (1,0) [0|31] "" Vector__XXX
SG_ Aft2GsOxidtnCatDiffPressPrlmFMI : 58|5@1+ (1,0) [0|31] "" Vector__XXX

BO_ 2566726398 A1GOC: 8 Vector__XXX
SG_ Aft1GasOxidtnCtlystIntkTemp : 0|16@1+ (0.03125,-273) [-273|1734.96875] "deg C" Vector__XXX
SG_ Aft1GasOxidtnCtlystOtltTemp : 16|16@1+ (0.03125,-273) [-273|1734.96875] "deg C" Vector__XXX
SG_ Aft1GasOxidtnCtlystDiffPress : 32|16@1+ (0.1,0) [0|6425.5] "kPa" Vector__XXX
SG_ Aft1GsOxidtnCtlystIntkTmpPrlmFMI : 48|5@1+ (1,0) [0|31] "" Vector__XXX
SG_ Aft1GsOxidtnCtlystOtltTmpPrlmFMI : 53|5@1+ (1,0) [0|31] "" Vector__XXX
SG_ Aft1GsOxidtnCatDiffPressPrlmFMI : 58|5@1+ (1,0) [0|31] "" Vector__XXX

BO_ 2365400062 EJM10: 8 Vector__XXX
SG_ Jystck10GrpXAxsNtrlPosStatus : 0|2@1+ (1,0) [0|3] "" Vector__XXX
SG_ Jystck10GrpXAxsLvrLftNegPosStat : 2|2@1+ (1,0) [0|3] "" Vector__XXX
SG_ Jystck10GrpXAxsLvrRghtPstvPsStat : 4|2@1+ (1,0) [0|3] "" Vector__XXX
SG_ Joystick10GripXAxisPosition : 6|10@1+ (0.1,0) [0|102] "%" Vector__XXX
SG_ Jystck10GrpYAxsNtrlPosStatus : 16|2@1+ (1,0) [0|3] "" Vector__XXX
SG_ Jystck10GrpYAxsLvrBackNegPosStat : 18|2@1+ (1,0) [0|3] "" Vector__XXX
SG_ Jystck10GrpYAxsLvrFrwdPstvPsStat : 20|2@1+ (1,0) [0|3] "" Vector__XXX
SG_ Joystick10GripYAxisPosition : 22|10@1+ (0.1,0) [0|102] "%" Vector__XXX
SG_ Jystck10ThetaAxsNtrlPosStatus : 32|2@1+ (1,0) [0|3] "" Vector__XXX
SG_ Jystck10ThtAxsCntrClckwsNgPsStat : 34|2@1+ (1,0) [0|3] "" Vector__XXX
SG_ Jystck10ThtAxsClckwsPstvPosStat : 36|2@1+ (1,0) [0|3] "" Vector__XXX
SG_ Joystick10ThetaAxisPosition : 38|10@1+ (0.1,0) [0|102] "%" Vector__XXX
SG_ Jystck10ThetaAxsDetentPosStatus : 50|2@1+ (1,0) [0|3] "" Vector__XXX
SG_ Jystck10GrpYAxsDetentPosStatus : 52|2@1+ (1,0) [0|3] "" Vector__XXX
SG_ Jystck10GrpXAxsDetentPosStatus : 54|2@1+ (1,0) [0|3] "" Vector__XXX
SG_ Joystick10Button16PressedStatus : 56|2@1+ (1,0) [0|3] "" Vector__XXX
SG_ Joystick10Button15PressedStatus : 58|2@1+ (1,0) [0|3] "" Vector__XXX
SG_ Joystick10Button14PressedStatus : 60|2@1+ (1,0) [0|3] "" Vector__XXX
SG_ Joystick10Button13PressedStatus : 62|2@1+ (1,0) [0|3] "" Vector__XXX

BO_ 2365400318 BJM10: 8 Vector__XXX
SG_ Jystck10XAxsNtrlPositionStatus : 0|2@1+ (1,0) [0|3] "" Vector__XXX
SG_ Jystck10XAxsLvrLftNegPosStatus : 2|2@1+ (1,0) [0|3] "" Vector__XXX
SG_ Jystck10XAxsLvrRghtPstvPosStatus : 4|2@1+ (1,0) [0|3] "" Vector__XXX
SG_ Joystick10XAxisPosition : 6|10@1+ (0.1,0) [0|102] "%" Vector__XXX
SG_ Jystck10YAxsNtrlPositionStatus : 16|2@1+ (1,0) [0|3] "" Vector__XXX
SG_ Jystck10YAxsLvrBackNegPosStatus : 18|2@1+ (1,0) [0|3] "" Vector__XXX
SG_ Jystck10YAxsLvrFrwdPstvPosStatus : 20|2@1+ (1,0) [0|3] "" Vector__XXX
SG_ Joystick10YAxisPosition : 22|10@1+ (0.1,0) [0|102] "%" Vector__XXX
SG_ Jystck10YAxsDetentPositionStatus : 36|2@1+ (1,0) [0|3] "" Vector__XXX
SG_ Jystck10XAxsDetentPositionStatus : 38|2@1+ (1,0) [0|3] "" Vector__XXX
SG_ Joystick10Button4PressedStatus : 40|2@1+ (1,0) [0|3] "" Vector__XXX
SG_ Joystick10Button3PressedStatus : 42|2@1+ (1,0) [0|3] "" Vector__XXX
SG_ Joystick10Button2PressedStatus : 44|2@1+ (1,0) [0|3] "" Vector__XXX
SG_ Joystick10Button1PressedStatus : 46|2@1+ (1,0) [0|3] "" Vector__XXX
SG_ Joystick10Button8PressedStatus : 48|2@1+ (1,0) [0|3] "" Vector__XXX
SG_ Joystick10Button7PressedStatus : 50|2@1+ (1,0) [0|3] "" Vector__XXX
SG_ Joystick10Button6PressedStatus : 52|2@1+ (1,0) [0|3] "" Vector__XXX
SG_ Joystick10Button5PressedStatus : 54|2@1+ (1,0) [0|3] "" Vector__XXX
SG_ Joystick10Button12PressedStatus : 56|2@1+ (1,0) [0|3] "" Vector__XXX
SG_ Joystick10Button11PressedStatus : 58|2@1+ (1,0) [0|3] "" Vector__XXX
SG_ Joystick10Button10PressedStatus : 60|2@1+ (1,0) [0|3] "" Vector__XXX
SG_ Joystick10Button9PressedStatus : 62|2@1+ (1,0) [0|3] "" Vector__XXX

BO_ 2365400574 EJM9: 8 Vector__XXX
SG_ Jystck9GrpXAxsNtrlPositionStatus : 0|2@1+ (1,0) [0|3] "" Vector__XXX
SG_ Jystck9GrpXAxsLvrLftNegPosStatus : 2|2@1+ (1,0) [0|3] "" Vector__XXX
SG_ Jystck9GrpXAxsLvrRghtPstvPosStat : 4|2@1+ (1,0) [0|3] "" Vector__XXX
SG_ Joystick9GripXAxisPosition : 6|10@1+ (0.1,0) [0|102] "%" Vector__XXX
SG_ Jystck9GrpYAxsNtrlPositionStatus : 16|2@1+ (1,0) [0|3] "" Vector__XXX
SG_ Jystck9GrpYAxsLvrBackNegPosStat : 18|2@1+ (1,0) [0|3] "" Vector__XXX
SG_ Jystck9GrpYAxsLvrFrwdPstvPosStat : 20|2@1+ (1,0) [0|3] "" Vector__XXX
SG_ Joystick9GripYAxisPosition : 22|10@1+ (0.1,0) [0|102] "%" Vector__XXX
SG_ Jystck9ThetaAxsNtrlPosStatus : 32|2@1+ (1,0) [0|3] "" Vector__XXX
SG_ Jystck9ThtAxsCntrClckwsNegPsStat : 34|2@1+ (1,0) [0|3] "" Vector__XXX
SG_ Jystck9ThetaAxsClckwsPstvPosStat : 36|2@1+ (1,0) [0|3] "" Vector__XXX
SG_ Joystick9ThetaAxisPosition : 38|10@1+ (0.1,0) [0|102] "%" Vector__XXX
SG_ Jystck9ThetaAxsDetentPosStatus : 50|2@1+ (1,0) [0|3] "" Vector__XXX
SG_ Jystck9GrpYAxsDetentPosStatus : 52|2@1+ (1,0) [0|3] "" Vector__XXX
SG_ Jystck9GrpXAxsDetentPosStatus : 54|2@1+ (1,0) [0|3] "" Vector__XXX
SG_ Joystick9Button16PressedStatus : 56|2@1+ (1,0) [0|3] "" Vector__XXX
SG_ Joystick9Button15PressedStatus : 58|2@1+ (1,0) [0|3] "" Vector__XXX
SG_ Joystick9Button14PressedStatus : 60|2@1+ (1,0) [0|3] "" Vector__XXX
SG_ Joystick9Button13PressedStatus : 62|2@1+ (1,0) [0|3] "" Vector__XXX

BO_ 2365400830 BJM9: 8 Vector__XXX
SG_ Jystck9XAxsNeutralPositionStatus : 0|2@1+ (1,0) [0|3] "" Vector__XXX
SG_ Jystck9XAxsLvrLftNegPosStatus : 2|2@1+ (1,0) [0|3] "" Vector__XXX
SG_ Jystck9XAxsLvrRightPstvPosStatus : 4|2@1+ (1,0) [0|3] "" Vector__XXX
SG_ Joystick9XAxisPosition : 6|10@1+ (0.1,0) [0|102] "%" Vector__XXX
SG_ Jystck9YAxsNeutralPositionStatus : 16|2@1+ (1,0) [0|3] "" Vector__XXX
SG_ Jystck9YAxsLvrBackNegPosStatus : 18|2@1+ (1,0) [0|3] "" Vector__XXX
SG_ Jystck9YAxsLvrFrwdPstvPosStatus : 20|2@1+ (1,0) [0|3] "" Vector__XXX
SG_ Joystick9YAxisPosition : 22|10@1+ (0.1,0) [0|102] "%" Vector__XXX
SG_ Jystck9YAxsDetentPositionStatus : 36|2@1+ (1,0) [0|3] "" Vector__XXX
SG_ Jystck9XAxsDetentPositionStatus : 38|2@1+ (1,0) [0|3] "" Vector__XXX
SG_ Joystick9Button4PressedStatus : 40|2@1+ (1,0) [0|3] "" Vector__XXX
SG_ Joystick9Button3PressedStatus : 42|2@1+ (1,0) [0|3] "" Vector__XXX
SG_ Joystick9Button2PressedStatus : 44|2@1+ (1,0) [0|3] "" Vector__XXX
SG_ Joystick9Button1PressedStatus : 46|2@1+ (1,0) [0|3] "" Vector__XXX
SG_ Joystick9Button8PressedStatus : 48|2@1+ (1,0) [0|3] "" Vector__XXX
SG_ Joystick9Button7PressedStatus : 50|2@1+ (1,0) [0|3] "" Vector__XXX
SG_ Joystick9Button6PressedStatus : 52|2@1+ (1,0) [0|3] "" Vector__XXX
SG_ Joystick9Button5PressedStatus : 54|2@1+ (1,0) [0|3] "" Vector__XXX
SG_ Joystick9Button12PressedStatus : 56|2@1+ (1,0) [0|3] "" Vector__XXX
SG_ Joystick9Button11PressedStatus : 58|2@1+ (1,0) [0|3] "" Vector__XXX
SG_ Joystick9Button10PressedStatus : 60|2@1+ (1,0) [0|3] "" Vector__XXX
SG_ Joystick9Button9PressedStatus : 62|2@1+ (1,0) [0|3] "" Vector__XXX

BO_ 2365401086 EJM8: 8 Vector__XXX
SG_ Jystck8GrpXAxsNtrlPositionStatus : 0|2@1+ (1,0) [0|3] "" Vector__XXX
SG_ Jystck8GrpXAxsLvrLftNegPosStatus : 2|2@1+ (1,0) [0|3] "" Vector__XXX
SG_ Jystck8GrpXAxsLvrRghtPstvPosStat : 4|2@1+ (1,0) [0|3] "" Vector__XXX
SG_ Joystick8GripXAxisPosition : 6|10@1+ (0.1,0) [0|102] "%" Vector__XXX
SG_ Jystck8GrpYAxsNtrlPositionStatus : 16|2@1+ (1,0) [0|3] "" Vector__XXX
SG_ Jystck8GrpYAxsLvrBackNegPosStat : 18|2@1+ (1,0) [0|3] "" Vector__XXX
SG_ Jystck8GrpYAxsLvrFrwdPstvPosStat : 20|2@1+ (1,0) [0|3] "" Vector__XXX
SG_ Joystick8GripYAxisPosition : 22|10@1+ (0.1,0) [0|102] "%" Vector__XXX
SG_ Jystck8ThetaAxsNtrlPosStatus : 32|2@1+ (1,0) [0|3] "" Vector__XXX
SG_ Jystck8ThtAxsCntrClckwsNegPsStat : 34|2@1+ (1,0) [0|3] "" Vector__XXX
SG_ Jystck8ThetaAxsClckwsPstvPosStat : 36|2@1+ (1,0) [0|3] "" Vector__XXX
SG_ Joystick8ThetaAxisPosition : 38|10@1+ (0.1,0) [0|102] "%" Vector__XXX
SG_ Jystck8ThetaAxsDetentPosStatus : 50|2@1+ (1,0) [0|3] "" Vector__XXX
SG_ Jystck8GrpYAxsDetentPosStatus : 52|2@1+ (1,0) [0|3] "" Vector__XXX
SG_ Jystck8GrpXAxsDetentPosStatus : 54|2@1+ (1,0) [0|3] "" Vector__XXX
SG_ Joystick8Button16PressedStatus : 56|2@1+ (1,0) [0|3] "" Vector__XXX
SG_ Joystick8Button15PressedStatus : 58|2@1+ (1,0) [0|3] "" Vector__XXX
SG_ Joystick8Button14PressedStatus : 60|2@1+ (1,0) [0|3] "" Vector__XXX
SG_ Joystick8Button13PressedStatus : 62|2@1+ (1,0) [0|3] "" Vector__XXX

BO_ 2365401342 BJM8: 8 Vector__XXX
SG_ Jystck8XAxsNeutralPositionStatus : 0|2@1+ (1,0) [0|3] "" Vector__XXX
SG_ Jystck8XAxsLvrLftNegPosStatus : 2|2@1+ (1,0) [0|3] "" Vector__XXX
SG_ Jystck8XAxsLvrRightPstvPosStatus : 4|2@1+ (1,0) [0|3] "" Vector__XXX
SG_ Joystick8XAxisPosition : 6|10@1+ (0.1,0) [0|102] "%" Vector__XXX
SG_ Jystck8YAxsNeutralPositionStatus : 16|2@1+ (1,0) [0|3] "" Vector__XXX
SG_ Jystck8YAxsLvrBackNegPosStatus : 18|2@1+ (1,0) [0|3] "" Vector__XXX
SG_ Jystck8YAxsLvrFrwdPstvPosStatus : 20|2@1+ (1,0) [0|3] "" Vector__XXX
SG_ Joystick8YAxisPosition : 22|10@1+ (0.1,0) [0|102] "%" Vector__XXX
SG_ Jystck8YAxsDetentPositionStatus : 36|2@1+ (1,0) [0|3] "" Vector__XXX
SG_ Jystck8XAxsDetentPositionStatus : 38|2@1+ (1,0) [0|3] "" Vector__XXX
SG_ Joystick8Button4PressedStatus : 40|2@1+ (1,0) [0|3] "" Vector__XXX
SG_ Joystick8Button3PressedStatus : 42|2@1+ (1,0) [0|3] "" Vector__XXX
SG_ Joystick8Button2PressedStatus : 44|2@1+ (1,0) [0|3] "" Vector__XXX
SG_ Joystick8Button1PressedStatus : 46|2@1+ (1,0) [0|3] "" Vector__XXX
SG_ Joystick8Button8PressedStatus : 48|2@1+ (1,0) [0|3] "" Vector__XXX
SG_ Joystick8Button7PressedStatus : 50|2@1+ (1,0) [0|3] "" Vector__XXX
SG_ Joystick8Button6PressedStatus : 52|2@1+ (1,0) [0|3] "" Vector__XXX
SG_ Joystick8Button5PressedStatus : 54|2@1+ (1,0) [0|3] "" Vector__XXX
SG_ Joystick8Button12PressedStatus : 56|2@1+ (1,0) [0|3] "" Vector__XXX
SG_ Joystick8Button11PressedStatus : 58|2@1+ (1,0) [0|3] "" Vector__XXX
SG_ Joystick8Button10PressedStatus : 60|2@1+ (1,0) [0|3] "" Vector__XXX
SG_ Joystick8Button9PressedStatus : 62|2@1+ (1,0) [0|3] "" Vector__XXX

BO_ 2365401598 EJM7: 8 Vector__XXX
SG_ Jystck7GrpXAxsNtrlPositionStatus : 0|2@1+ (1,0) [0|3] "" Vector__XXX
SG_ Jystck7GrpXAxsLvrLftNegPosStatus : 2|2@1+ (1,0) [0|3] "" Vector__XXX
SG_ Jystck7GrpXAxsLvrRghtPstvPosStat : 4|2@1+ (1,0) [0|3] "" Vector__XXX
SG_ Joystick7GripXAxisPosition : 6|10@1+ (0.1,0) [0|102] "%" Vector__XXX
SG_ Jystck7GrpYAxsNtrlPositionStatus : 16|2@1+ (1,0) [0|3] "" Vector__XXX
SG_ Jystck7GrpYAxsLvrBackNegPosStat : 18|2@1+ (1,0) [0|3] "" Vector__XXX
SG_ Jystck7GrpYAxsLvrFrwdPstvPosStat : 20|2@1+ (1,0) [0|3] "" Vector__XXX
SG_ Joystick7GripYAxisPosition : 22|10@1+ (0.1,0) [0|102] "%" Vector__XXX
SG_ Jystck7ThetaAxsNtrlPosStatus : 32|2@1+ (1,0) [0|3] "" Vector__XXX
SG_ Jystck7ThtAxsCntrClckwsNegPsStat : 34|2@1+ (1,0) [0|3] "" Vector__XXX
SG_ Jystck7ThetaAxsClckwsPstvPosStat : 36|2@1+ (1,0) [0|3] "" Vector__XXX
SG_ Joystick7ThetaAxisPosition : 38|10@1+ (0.1,0) [0|102] "%" Vector__XXX
SG_ Jystck7ThetaAxsDetentPosStatus : 50|2@1+ (1,0) [0|3] "" Vector__XXX
SG_ Jystck7GrpYAxsDetentPosStatus : 52|2@1+ (1,0) [0|3] "" Vector__XXX
SG_ Jystck7GrpXAxsDetentPosStatus : 54|2@1+ (1,0) [0|3] "" Vector__XXX
SG_ Joystick7Button16PressedStatus : 56|2@1+ (1,0) [0|3] "" Vector__XXX
SG_ Joystick7Button15PressedStatus : 58|2@1+ (1,0) [0|3] "" Vector__XXX
SG_ Joystick7Button14PressedStatus : 60|2@1+ (1,0) [0|3] "" Vector__XXX
SG_ Joystick7Button13PressedStatus : 62|2@1+ (1,0) [0|3] "" Vector__XXX

BO_ 2365401854 BJM7: 8 Vector__XXX
SG_ Jystck7XAxsNeutralPositionStatus : 0|2@1+ (1,0) [0|3] "" Vector__XXX
SG_ Jystck7XAxsLvrLftNegPosStatus : 2|2@1+ (1,0) [0|3] "" Vector__XXX
SG_ Jystck7XAxsLvrRightPstvPosStatus : 4|2@1+ (1,0) [0|3] "" Vector__XXX
SG_ Joystick7XAxisPosition : 6|10@1+ (0.1,0) [0|102] "%" Vector__XXX
SG_ Jystck7YAxsNeutralPositionStatus : 16|2@1+ (1,0) [0|3] "" Vector__XXX
SG_ Jystck7YAxsLvrBackNegPosStatus : 18|2@1+ (1,0) [0|3] "" Vector__XXX
SG_ Jystck7YAxsLvrFrwdPstvPosStatus : 20|2@1+ (1,0) [0|3] "" Vector__XXX
SG_ Joystick7YAxisPosition : 22|10@1+ (0.1,0) [0|102] "%" Vector__XXX
SG_ Jystck7YAxsDetentPositionStatus : 36|2@1+ (1,0) [0|3] "" Vector__XXX
SG_ Jystck7XAxsDetentPositionStatus : 38|2@1+ (1,0) [0|3] "" Vector__XXX
SG_ Joystick7Button4PressedStatus : 40|2@1+ (1,0) [0|3] "" Vector__XXX
SG_ Joystick7Button3PressedStatus : 42|2@1+ (1,0) [0|3] "" Vector__XXX
SG_ Joystick7Button2PressedStatus : 44|2@1+ (1,0) [0|3] "" Vector__XXX
SG_ Joystick7Button1PressedStatus : 46|2@1+ (1,0) [0|3] "" Vector__XXX
SG_ Joystick7Button8PressedStatus : 48|2@1+ (1,0) [0|3] "" Vector__XXX
SG_ Joystick7Button7PressedStatus : 50|2@1+ (1,0) [0|3] "" Vector__XXX
SG_ Joystick7Button6PressedStatus : 52|2@1+ (1,0) [0|3] "" Vector__XXX
SG_ Joystick7Button5PressedStatus : 54|2@1+ (1,0) [0|3] "" Vector__XXX
SG_ Joystick7Button12PressedStatus : 56|2@1+ (1,0) [0|3] "" Vector__XXX
SG_ Joystick7Button11PressedStatus : 58|2@1+ (1,0) [0|3] "" Vector__XXX
SG_ Joystick7Button10PressedStatus : 60|2@1+ (1,0) [0|3] "" Vector__XXX
SG_ Joystick7Button9PressedStatus : 62|2@1+ (1,0) [0|3] "" Vector__XXX

BO_ 2365402110 EJM6: 8 Vector__XXX
SG_ Jystck6GrpXAxsNtrlPositionStatus : 0|2@1+ (1,0) [0|3] "" Vector__XXX
SG_ Jystck6GrpXAxsLvrLftNegPosStatus : 2|2@1+ (1,0) [0|3] "" Vector__XXX
SG_ Jystck6GrpXAxsLvrRghtPstvPosStat : 4|2@1+ (1,0) [0|3] "" Vector__XXX
SG_ Joystick6GripXAxisPosition : 6|10@1+ (0.1,0) [0|102] "%" Vector__XXX
SG_ Jystck6GrpYAxsNtrlPositionStatus : 16|2@1+ (1,0) [0|3] "" Vector__XXX
SG_ Jystck6GrpYAxsLvrBackNegPosStat : 18|2@1+ (1,0) [0|3] "" Vector__XXX
SG_ Jystck6GrpYAxsLvrFrwdPstvPosStat : 20|2@1+ (1,0) [0|3] "" Vector__XXX
SG_ Joystick6GripYAxisPosition : 22|10@1+ (0.1,0) [0|102] "%" Vector__XXX
SG_ Jystck6ThetaAxsNtrlPosStatus : 32|2@1+ (1,0) [0|3] "" Vector__XXX
SG_ Jystck6ThtAxsCntrClckwsNegPsStat : 34|2@1+ (1,0) [0|3] "" Vector__XXX
SG_ Jystck6ThetaAxsClckwsPstvPosStat : 36|2@1+ (1,0) [0|3] "" Vector__XXX
SG_ Joystick6ThetaAxisPosition : 38|10@1+ (0.1,0) [0|102] "%" Vector__XXX
SG_ Jystck6ThetaAxsDetentPosStatus : 50|2@1+ (1,0) [0|3] "" Vector__XXX
SG_ Jystck6GrpYAxsDetentPosStatus : 52|2@1+ (1,0) [0|3] "" Vector__XXX
SG_ Jystck6GrpXAxsDetentPosStatus : 54|2@1+ (1,0) [0|3] "" Vector__XXX
SG_ Joystick6Button16PressedStatus : 56|2@1+ (1,0) [0|3] "" Vector__XXX
SG_ Joystick6Button15PressedStatus : 58|2@1+ (1,0) [0|3] "" Vector__XXX
SG_ Joystick6Button14PressedStatus : 60|2@1+ (1,0) [0|3] "" Vector__XXX
SG_ Joystick6Button13PressedStatus : 62|2@1+ (1,0) [0|3] "" Vector__XXX

BO_ 2365402366 BJM6: 8 Vector__XXX
SG_ Jystck6XAxsNeutralPositionStatus : 0|2@1+ (1,0) [0|3] "" Vector__XXX
SG_ Jystck6XAxsLvrLftNegPosStatus : 2|2@1+ (1,0) [0|3] "" Vector__XXX
SG_ Jystck6XAxsLvrRightPstvPosStatus : 4|2@1+ (1,0) [0|3] "" Vector__XXX
SG_ Joystick6XAxisPosition : 6|10@1+ (0.1,0) [0|102] "%" Vector__XXX
SG_ Jystck6YAxsNeutralPositionStatus : 16|2@1+ (1,0) [0|3] "" Vector__XXX
SG_ Jystck6YAxsLvrBackNegPosStatus : 18|2@1+ (1,0) [0|3] "" Vector__XXX
SG_ Jystck6YAxsLvrFrwdPstvPosStatus : 20|2@1+ (1,0) [0|3] "" Vector__XXX
SG_ Joystick6YAxisPosition : 22|10@1+ (0.1,0) [0|102] "%" Vector__XXX
SG_ Jystck6YAxsDetentPositionStatus : 36|2@1+ (1,0) [0|3] "" Vector__XXX
SG_ Jystck6XAxsDetentPositionStatus : 38|2@1+ (1,0) [0|3] "" Vector__XXX
SG_ Joystick6Button4PressedStatus : 40|2@1+ (1,0) [0|3] "" Vector__XXX
SG_ Joystick6Button3PressedStatus : 42|2@1+ (1,0) [0|3] "" Vector__XXX
SG_ Joystick6Button2PressedStatus : 44|2@1+ (1,0) [0|3] "" Vector__XXX
SG_ Joystick6Button1PressedStatus : 46|2@1+ (1,0) [0|3] "" Vector__XXX
SG_ Joystick6Button8PressedStatus : 48|2@1+ (1,0) [0|3] "" Vector__XXX
SG_ Joystick6Button7PressedStatus : 50|2@1+ (1,0) [0|3] "" Vector__XXX
SG_ Joystick6Button6PressedStatus : 52|2@1+ (1,0) [0|3] "" Vector__XXX
SG_ Joystick6Button5PressedStatus : 54|2@1+ (1,0) [0|3] "" Vector__XXX
SG_ Joystick6Button12PressedStatus : 56|2@1+ (1,0) [0|3] "" Vector__XXX
SG_ Joystick6Button11PressedStatus : 58|2@1+ (1,0) [0|3] "" Vector__XXX
SG_ Joystick6Button10PressedStatus : 60|2@1+ (1,0) [0|3] "" Vector__XXX
SG_ Joystick6Button9PressedStatus : 62|2@1+ (1,0) [0|3] "" Vector__XXX

BO_ 2365402622 EJM5: 8 Vector__XXX
SG_ Jystck5GrpXAxsNtrlPositionStatus : 0|2@1+ (1,0) [0|3] "" Vector__XXX
SG_ Jystck5GrpXAxsLvrLftNegPosStatus : 2|2@1+ (1,0) [0|3] "" Vector__XXX
SG_ Jystck5GrpXAxsLvrRghtPstvPosStat : 4|2@1+ (1,0) [0|3] "" Vector__XXX
SG_ Joystick5GripXAxisPosition : 6|10@1+ (0.1,0) [0|102] "%" Vector__XXX
SG_ Jystck5GrpYAxsNtrlPositionStatus : 16|2@1+ (1,0) [0|3] "" Vector__XXX
SG_ Jystck5GrpYAxsLvrBackNegPosStat : 18|2@1+ (1,0) [0|3] "" Vector__XXX
SG_ Jystck5GrpYAxsLvrFrwdPstvPosStat : 20|2@1+ (1,0) [0|3] "" Vector__XXX
SG_ Joystick5GripYAxisPosition : 22|10@1+ (0.1,0) [0|102] "%" Vector__XXX
SG_ Jystck5ThetaAxsNtrlPosStatus : 32|2@1+ (1,0) [0|3] "" Vector__XXX
SG_ Jystck5ThtAxsCntrClckwsNegPsStat : 34|2@1+ (1,0) [0|3] "" Vector__XXX
SG_ Jystck5ThetaAxsClckwsPstvPosStat : 36|2@1+ (1,0) [0|3] "" Vector__XXX
SG_ Joystick5ThetaAxisPosition : 38|10@1+ (0.1,0) [0|102] "%" Vector__XXX
SG_ Jystck5ThetaAxsDetentPosStatus : 50|2@1+ (1,0) [0|3] "" Vector__XXX
SG_ Jystck5GrpYAxsDetentPosStatus : 52|2@1+ (1,0) [0|3] "" Vector__XXX
SG_ Jystck5GrpXAxsDetentPosStatus : 54|2@1+ (1,0) [0|3] "" Vector__XXX
SG_ Joystick5Button16PressedStatus : 56|2@1+ (1,0) [0|3] "" Vector__XXX
SG_ Joystick5Button15PressedStatus : 58|2@1+ (1,0) [0|3] "" Vector__XXX
SG_ Joystick5Button14PressedStatus : 60|2@1+ (1,0) [0|3] "" Vector__XXX
SG_ Joystick5Button13PressedStatus : 62|2@1+ (1,0) [0|3] "" Vector__XXX

BO_ 2365402878 BJM5: 8 Vector__XXX
SG_ Jystck5XAxsNeutralPositionStatus : 0|2@1+ (1,0) [0|3] "" Vector__XXX
SG_ Jystck5XAxsLvrLftNegPosStatus : 2|2@1+ (1,0) [0|3] "" Vector__XXX
SG_ Jystck5XAxsLvrRightPstvPosStatus : 4|2@1+ (1,0) [0|3] "" Vector__XXX
SG_ Joystick5XAxisPosition : 6|10@1+ (0.1,0) [0|102] "%" Vector__XXX
SG_ Jystck5YAxsNeutralPositionStatus : 16|2@1+ (1,0) [0|3] "" Vector__XXX
SG_ Jystck5YAxsLvrBackNegPosStatus : 18|2@1+ (1,0) [0|3] "" Vector__XXX
SG_ Jystck5YAxsLvrFrwdPstvPosStatus : 20|2@1+ (1,0) [0|3] "" Vector__XXX
SG_ Joystick5YAxisPosition : 22|10@1+ (0.1,0) [0|102] "%" Vector__XXX
SG_ Jystck5YAxsDetentPositionStatus : 36|2@1+ (1,0) [0|3] "" Vector__XXX
SG_ Jystck5XAxsDetentPositionStatus : 38|2@1+ (1,0) [0|3] "" Vector__XXX
SG_ Joystick5Button4PressedStatus : 40|2@1+ (1,0) [0|3] "" Vector__XXX
SG_ Joystick5Button3PressedStatus : 42|2@1+ (1,0) [0|3] "" Vector__XXX
SG_ Joystick5Button2PressedStatus : 44|2@1+ (1,0) [0|3] "" Vector__XXX
SG_ Joystick5Button1PressedStatus : 46|2@1+ (1,0) [0|3] "" Vector__XXX
SG_ Joystick5Button8PressedStatus : 48|2@1+ (1,0) [0|3] "" Vector__XXX
SG_ Joystick5Button7PressedStatus : 50|2@1+ (1,0) [0|3] "" Vector__XXX
SG_ Joystick5Button6PressedStatus : 52|2@1+ (1,0) [0|3] "" Vector__XXX
SG_ Joystick5Button5PressedStatus : 54|2@1+ (1,0) [0|3] "" Vector__XXX
SG_ Joystick5Button12PressedStatus : 56|2@1+ (1,0) [0|3] "" Vector__XXX
SG_ Joystick5Button11PressedStatus : 58|2@1+ (1,0) [0|3] "" Vector__XXX
SG_ Joystick5Button10PressedStatus : 60|2@1+ (1,0) [0|3] "" Vector__XXX
SG_ Joystick5Button9PressedStatus : 62|2@1+ (1,0) [0|3] "" Vector__XXX

BO_ 2365403134 EJM4: 8 Vector__XXX
SG_ Jystck4GrpXAxsNtrlPositionStatus : 0|2@1+ (1,0) [0|3] "" Vector__XXX
SG_ Jystck4GrpXAxsLvrLftNegPosStatus : 2|2@1+ (1,0) [0|3] "" Vector__XXX
SG_ Jystck4GrpXAxsLvrRghtPstvPosStat : 4|2@1+ (1,0) [0|3] "" Vector__XXX
SG_ Joystick4GripXAxisPosition : 6|10@1+ (0.1,0) [0|102] "%" Vector__XXX
SG_ Jystck4GrpYAxsNtrlPositionStatus : 16|2@1+ (1,0) [0|3] "" Vector__XXX
SG_ Jystck4GrpYAxsLvrBackNegPosStat : 18|2@1+ (1,0) [0|3] "" Vector__XXX
SG_ Jystck4GrpYAxsLvrFrwdPstvPosStat : 20|2@1+ (1,0) [0|3] "" Vector__XXX
SG_ Joystick4GripYAxisPosition : 22|10@1+ (0.1,0) [0|102] "%" Vector__XXX
SG_ Jystck4ThetaAxsNtrlPosStatus : 32|2@1+ (1,0) [0|3] "" Vector__XXX
SG_ Jystck4ThtAxsCntrClckwsNegPsStat : 34|2@1+ (1,0) [0|3] "" Vector__XXX
SG_ Jystck4ThetaAxsClckwsPstvPosStat : 36|2@1+ (1,0) [0|3] "" Vector__XXX
SG_ Joystick4ThetaAxisPosition : 38|10@1+ (0.1,0) [0|102] "%" Vector__XXX
SG_ Jystck4ThetaAxsDetentPosStatus : 50|2@1+ (1,0) [0|3] "" Vector__XXX
SG_ Jystck4GrpYAxsDetentPosStatus : 52|2@1+ (1,0) [0|3] "" Vector__XXX
SG_ Jystck4GrpXAxsDetentPosStatus : 54|2@1+ (1,0) [0|3] "" Vector__XXX
SG_ Joystick4Button16PressedStatus : 56|2@1+ (1,0) [0|3] "" Vector__XXX
SG_ Joystick4Button15PressedStatus : 58|2@1+ (1,0) [0|3] "" Vector__XXX
SG_ Joystick4Button14PressedStatus : 60|2@1+ (1,0) [0|3] "" Vector__XXX
SG_ Joystick4Button13PressedStatus : 62|2@1+ (1,0) [0|3] "" Vector__XXX

BO_ 2365403390 BJM4: 8 Vector__XXX
SG_ Jystck4XAxsNeutralPositionStatus : 0|2@1+ (1,0) [0|3] "" Vector__XXX
SG_ Jystck4XAxsLvrLftNegPosStatus : 2|2@1+ (1,0) [0|3] "" Vector__XXX
SG_ Jystck4XAxsLvrRightPstvPosStatus : 4|2@1+ (1,0) [0|3] "" Vector__XXX
SG_ Joystick4XAxisPosition : 6|10@1+ (0.1,0) [0|102] "%" Vector__XXX
SG_ Jystck4YAxsNeutralPositionStatus : 16|2@1+ (1,0) [0|3] "" Vector__XXX
SG_ Jystck4YAxsLvrBackNegPosStatus : 18|2@1+ (1,0) [0|3] "" Vector__XXX
SG_ Jystck4YAxsLvrFrwdPstvPosStatus : 20|2@1+ (1,0) [0|3] "" Vector__XXX
SG_ Joystick4YAxisPosition : 22|10@1+ (0.1,0) [0|102] "%" Vector__XXX
SG_ Jystck4YAxsDetentPositionStatus : 36|2@1+ (1,0) [0|3] "" Vector__XXX
SG_ Jystck4XAxsDetentPositionStatus : 38|2@1+ (1,0) [0|3] "" Vector__XXX
SG_ Joystick4Button4PressedStatus : 40|2@1+ (1,0) [0|3] "" Vector__XXX
SG_ Joystick4Button3PressedStatus : 42|2@1+ (1,0) [0|3] "" Vector__XXX
SG_ Joystick4Button2PressedStatus : 44|2@1+ (1,0) [0|3] "" Vector__XXX
SG_ Joystick4Button1PressedStatus : 46|2@1+ (1,0) [0|3] "" Vector__XXX
SG_ Joystick4Button8PressedStatus : 48|2@1+ (1,0) [0|3] "" Vector__XXX
SG_ Joystick4Button7PressedStatus : 50|2@1+ (1,0) [0|3] "" Vector__XXX
SG_ Joystick4Button6PressedStatus : 52|2@1+ (1,0) [0|3] "" Vector__XXX
SG_ Joystick4Button5PressedStatus : 54|2@1+ (1,0) [0|3] "" Vector__XXX
SG_ Joystick4Button12PressedStatus : 56|2@1+ (1,0) [0|3] "" Vector__XXX
SG_ Joystick4Button11PressedStatus : 58|2@1+ (1,0) [0|3] "" Vector__XXX
SG_ Joystick4Button10PressedStatus : 60|2@1+ (1,0) [0|3] "" Vector__XXX
SG_ Joystick4Button9PressedStatus : 62|2@1+ (1,0) [0|3] "" Vector__XXX

BO_ 2566730238 FD2: 8 Vector__XXX
SG_ EstimatedPercentFan2Speed : 0|8@1+ (0.4,0) [0|100] "%" Vector__XXX
SG_ Fan2DriveState : 8|4@1+ (1,0) [0|15] "" Vector__XXX
SG_ Fan2Speed : 16|16@1+ (0.125,0) [0|8031.875] "rpm" Vector__XXX
SG_ HydraulicFan2MotorPressure : 32|16@1+ (0.5,0) [0|32127.5] "kPa" Vector__XXX
SG_ Fan2DriveBypassCommandStatus : 48|8@1+ (0.4,0) [0|100] "%" Vector__XXX

BO_ 2566730494 ECUDP: 0 Vector__XXX

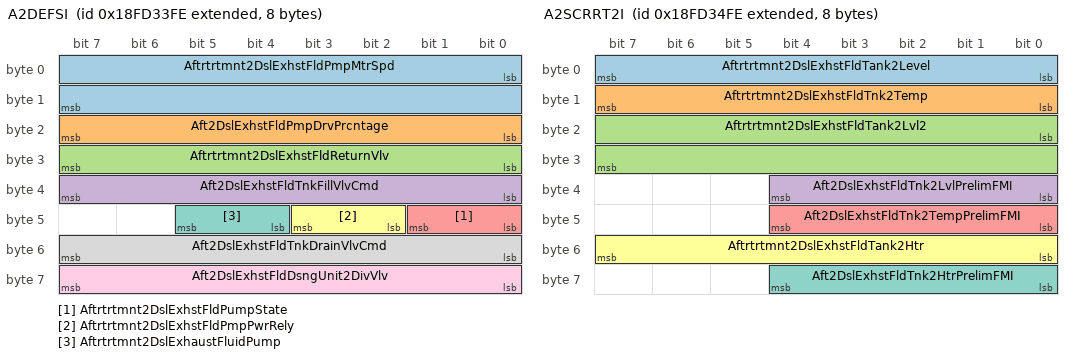
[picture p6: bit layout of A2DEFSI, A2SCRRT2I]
BO_ 2566730750 A2DEFSI: 8 Vector__XXX
SG_ Aftrtrtmnt2DslExhstFldPmpMtrSpd : 0|16@1+ (0.5,0) [0|32127.5] "rpm" Vector__XXX
SG_ Aft2DslExhstFldPmpDrvPrcntage : 16|8@1+ (0.4,0) [0|100] "%" Vector__XXX
SG_ Aftrtrtmnt2DslExhstFldReturnVlv : 24|8@1+ (0.4,0) [0|100] "%" Vector__XXX
SG_ Aft2DslExhstFldTnkFillVlvCmd : 32|8@1+ (0.4,0) [0|100] "%" Vector__XXX
SG_ Aftrtrtmnt2DslExhstFldPumpState : 40|2@1+ (1,0) [0|3] "" Vector__XXX
SG_ Aftrtrtmnt2DslExhstFldPmpPwrRely : 42|2@1+ (1,0) [0|3] "" Vector__XXX
SG_ Aftrtrtmnt2DslExhaustFluidPump : 44|2@1+ (1,0) [0|3] "" Vector__XXX
SG_ Aft2DslExhstFldTnkDrainVlvCmd : 48|8@1+ (0.4,0) [0|100] "%" Vector__XXX
SG_ Aft2DslExhstFldDsngUnit2DivVlv : 56|8@1+ (0.4,0) [0|100] "%" Vector__XXX

BO_ 2566731006 A2SCRRT2I: 8 Vector__XXX
SG_ Aftrtrtmnt2DslExhstFldTank2Level : 0|8@1+ (0.4,0) [0|100] "%" Vector__XXX
SG_ Aftrtrtmnt2DslExhstFldTnk2Temp : 8|8@1+ (1,-40) [-40|210] "deg C" Vector__XXX
SG_ Aftrtrtmnt2DslExhstFldTank2Lvl2 : 16|16@1+ (0.1,0) [0|6425.5] "mm" Vector__XXX
SG_ Aft2DslExhstFldTnk2LvlPrelimFMI : 32|5@1+ (1,0) [0|31] "" Vector__XXX
SG_ Aft2DslExhstFldTnk2TempPrelimFMI : 40|5@1+ (1,0) [0|31] "" Vector__XXX
SG_ Aftrtrtmnt2DslExhstFldTank2Htr : 48|8@1+ (0.4,0) [0|100] "%" Vector__XXX
SG_ Aft2DslExhstFldTnk2HtrPrelimFMI : 56|5@1+ (1,0) [0|31] "" Vector__XXX

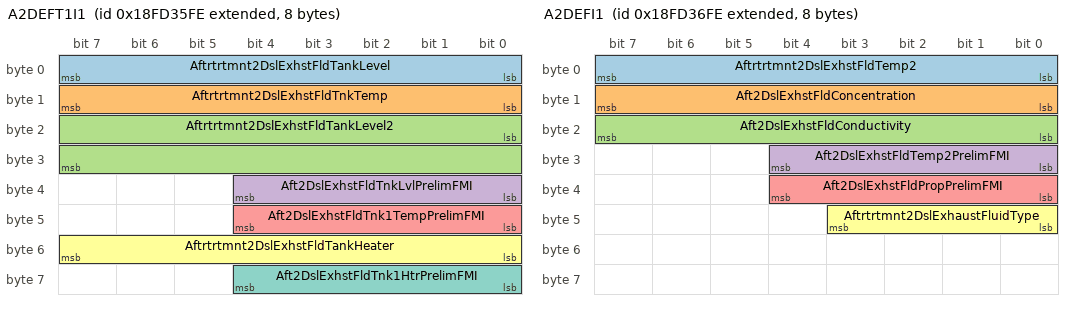
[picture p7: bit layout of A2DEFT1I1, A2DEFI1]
BO_ 2566731262 A2DEFT1I1: 8 Vector__XXX
SG_ Aftrtrtmnt2DslExhstFldTankLevel : 0|8@1+ (0.4,0) [0|100] "%" Vector__XXX
SG_ Aftrtrtmnt2DslExhstFldTnkTemp : 8|8@1+ (1,-40) [-40|210] "deg C" Vector__XXX
SG_ Aftrtrtmnt2DslExhstFldTankLevel2 : 16|16@1+ (0.1,0) [0|6425.5] "mm" Vector__XXX
SG_ Aft2DslExhstFldTnkLvlPrelimFMI : 32|5@1+ (1,0) [0|31] "" Vector__XXX
SG_ Aft2DslExhstFldTnk1TempPrelimFMI : 40|5@1+ (1,0) [0|31] "" Vector__XXX
SG_ Aftrtrtmnt2DslExhstFldTankHeater : 48|8@1+ (0.4,0) [0|100] "%" Vector__XXX
SG_ Aft2DslExhstFldTnk1HtrPrelimFMI : 56|5@1+ (1,0) [0|31] "" Vector__XXX

BO_ 2566731518 A2DEFI1: 8 Vector__XXX
SG_ Aftrtrtmnt2DslExhstFldTemp2 : 0|8@1+ (1,-40) [-40|210] "deg C" Vector__XXX
SG_ Aft2DslExhstFldConcentration : 8|8@1+ (0.25,0) [0|62.5] "%" Vector__XXX
SG_ Aft2DslExhstFldConductivity : 16|8@1+ (5,0) [0|1250] "uSiemens/mm" Vector__XXX
SG_ Aft2DslExhstFldTemp2PrelimFMI : 24|5@1+ (1,0) [0|31] "" Vector__XXX
SG_ Aft2DslExhstFldPropPrelimFMI : 32|5@1+ (1,0) [0|31] "" Vector__XXX
SG_ Aftrtrtmnt2DslExhaustFluidType : 40|4@1+ (1,0) [0|15] "" Vector__XXX

BO_ 2566731774 A2SCRSI1: 8 Vector__XXX
SG_ Aft2DslExhstFldAvrgCnsmptn : 0|16@1+ (0.05,0) [0|3212.75] "l/h" Vector__XXX
SG_ Aft2SCRCmdedDslExhstFldCnsmptn : 16|16@1+ (0.05,0) [0|3212.75] "l/h" Vector__XXX
SG_ Aftrtrtmnt2SCRCnvrsnEfficiency : 32|8@1+ (0.4,0) [0|100] "%" Vector__XXX
SG_ Aftrtrtmnt2SCRSystemSulfationLvl : 40|8@1+ (1,0) [0|250] "%" Vector__XXX

BO_ 2566732030 A2SCREGT1: 8 Vector__XXX
SG_ Aftrtrtmnt2SCRIntakeTemperature : 0|16@1+ (0.03125,-273) [-273|1734.96875] "deg C" Vector__XXX
SG_ Aftrtrtmnt2SCRIntkTempPrelimFMI : 16|5@1+ (1,0) [0|31] "" Vector__XXX
SG_ Aftrtrtmnt2SCROutletTemperature : 24|16@1+ (0.03125,-273) [-273|1734.96875] "deg C" Vector__XXX
SG_ Aftrtrtmnt2SCROtltTempPrelimFMI : 40|5@1+ (1,0) [0|31] "" Vector__XXX

BO_ 2566732286 A2SCREGP: 8 Vector__XXX
SG_ Aftrtrtmnt2SCRDiffPressure : 0|16@1+ (0.1,0) [0|6425.5] "kPa" Vector__XXX
SG_ Aftrtrtmnt2SCRDiffPressPrelimFMI : 16|5@1+ (1,0) [0|31] "" Vector__XXX
SG_ Aftertreatment2SCRIntakePressure : 24|16@1+ (0.1,-3212.7) [-3212.7|3212.8] "kPa" Vector__XXX
SG_ Aftrtrtmnt2SCRIntakeAbsPressure : 40|16@1+ (0.1,0) [0|6425.5] "kPa" Vector__XXX

BO_ 2566732542 A2SCRDSR2: 8 Vector__XXX
SG_ Aft2DslExhstFldDsrFltSupPrsionRq : 2|2@1+ (1,0) [0|3] "" Vector__XXX
SG_ Aft2DslExhstFldDoserHeatingMdeRq : 4|3@1+ (1,0) [0|7] "" Vector__XXX
SG_ Aftrtrtmnt2DslExhstFldLineHtr1 : 8|2@1+ (1,0) [0|3] "" Vector__XXX
SG_ Aftrtrtmnt2DslExhstFldLineHtr2 : 10|2@1+ (1,0) [0|3] "" Vector__XXX
SG_ Aftrtrtmnt2DslExhstFldLineHtr3 : 12|2@1+ (1,0) [0|3] "" Vector__XXX
SG_ Aftrtrtmnt2DslExhstFldLineHtr4 : 14|2@1+ (1,0) [0|3] "" Vector__XXX
SG_ Aftrtrtmnt2DslExhstFldTankHtrCmd : 16|8@1+ (0.4,0) [0|100] "%" Vector__XXX
SG_ Aftrtrtmnt2DslExhstFldTnk2HtrCmd : 24|8@1+ (0.4,0) [0|100] "%" Vector__XXX
SG_ Aft2DslExhstFldLineHtrRely1 : 32|2@1+ (1,0) [0|3] "" Vector__XXX
SG_ Aft2DslExhstFldLineHtrRely2 : 34|2@1+ (1,0) [0|3] "" Vector__XXX
SG_ Aft2DslExhstFldLineHtrRely3 : 36|2@1+ (1,0) [0|3] "" Vector__XXX
SG_ Aftrtrtmnt2DslExhstFldLineHtr5 : 38|2@1+ (1,0) [0|3] "" Vector__XXX
SG_ Aftrtrtmnt2DslExhstFldLineHtr6 : 40|2@1+ (1,0) [0|3] "" Vector__XXX
SG_ Aftrtrtmnt2DslExhstFldLineHtr7 : 42|2@1+ (1,0) [0|3] "" Vector__XXX
SG_ Aftrtrtmnt2DslExhstFldLineHtr8 : 44|2@1+ (1,0) [0|3] "" Vector__XXX
SG_ Aftrtrtmnt2DslExhstFldLineHtr9 : 46|2@1+ (1,0) [0|3] "" Vector__XXX
SG_ Aftrtrtmnt2DslExhstFldLineHtr10 : 48|2@1+ (1,0) [0|3] "" Vector__XXX

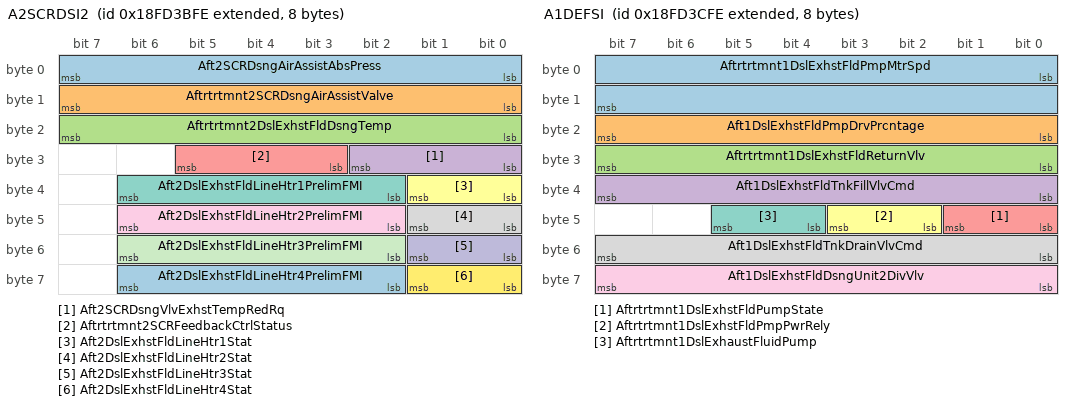
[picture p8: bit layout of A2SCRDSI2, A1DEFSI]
BO_ 2566732798 A2SCRDSI2: 8 Vector__XXX
SG_ Aft2SCRDsngAirAssistAbsPress : 0|8@1+ (8,0) [0|2000] "kPa" Vector__XXX
SG_ Aftrtrtmnt2SCRDsngAirAssistValve : 8|8@1+ (0.4,0) [0|100] "%" Vector__XXX
SG_ Aftrtrtmnt2DslExhstFldDsngTemp : 16|8@1+ (1,-40) [-40|210] "deg C" Vector__XXX
SG_ Aft2SCRDsngVlvExhstTempRedRq : 24|3@1+ (1,0) [0|7] "" Vector__XXX
SG_ Aftrtrtmnt2SCRFeedbackCtrlStatus : 27|3@1+ (1,0) [0|7] "" Vector__XXX
SG_ Aft2DslExhstFldLineHtr1Stat : 32|2@1+ (1,0) [0|3] "" Vector__XXX
SG_ Aft2DslExhstFldLineHtr1PrelimFMI : 34|5@1+ (1,0) [0|31] "" Vector__XXX
SG_ Aft2DslExhstFldLineHtr2Stat : 40|2@1+ (1,0) [0|3] "" Vector__XXX
SG_ Aft2DslExhstFldLineHtr2PrelimFMI : 42|5@1+ (1,0) [0|31] "" Vector__XXX
SG_ Aft2DslExhstFldLineHtr3Stat : 48|2@1+ (1,0) [0|3] "" Vector__XXX
SG_ Aft2DslExhstFldLineHtr3PrelimFMI : 50|5@1+ (1,0) [0|31] "" Vector__XXX
SG_ Aft2DslExhstFldLineHtr4Stat : 56|2@1+ (1,0) [0|3] "" Vector__XXX
SG_ Aft2DslExhstFldLineHtr4PrelimFMI : 58|5@1+ (1,0) [0|31] "" Vector__XXX

BO_ 2566733054 A1DEFSI: 8 Vector__XXX
SG_ Aftrtrtmnt1DslExhstFldPmpMtrSpd : 0|16@1+ (0.5,0) [0|32127.5] "rpm" Vector__XXX
SG_ Aft1DslExhstFldPmpDrvPrcntage : 16|8@1+ (0.4,0) [0|100] "%" Vector__XXX
SG_ Aftrtrtmnt1DslExhstFldReturnVlv : 24|8@1+ (0.4,0) [0|100] "%" Vector__XXX
SG_ Aft1DslExhstFldTnkFillVlvCmd : 32|8@1+ (0.4,0) [0|100] "%" Vector__XXX
SG_ Aftrtrtmnt1DslExhstFldPumpState : 40|2@1+ (1,0) [0|3] "" Vector__XXX
SG_ Aftrtrtmnt1DslExhstFldPmpPwrRely : 42|2@1+ (1,0) [0|3] "" Vector__XXX
SG_ Aftrtrtmnt1DslExhaustFluidPump : 44|2@1+ (1,0) [0|3] "" Vector__XXX
SG_ Aft1DslExhstFldTnkDrainVlvCmd : 48|8@1+ (0.4,0) [0|100] "%" Vector__XXX
SG_ Aft1DslExhstFldDsngUnit2DivVlv : 56|8@1+ (0.4,0) [0|100] "%" Vector__XXX

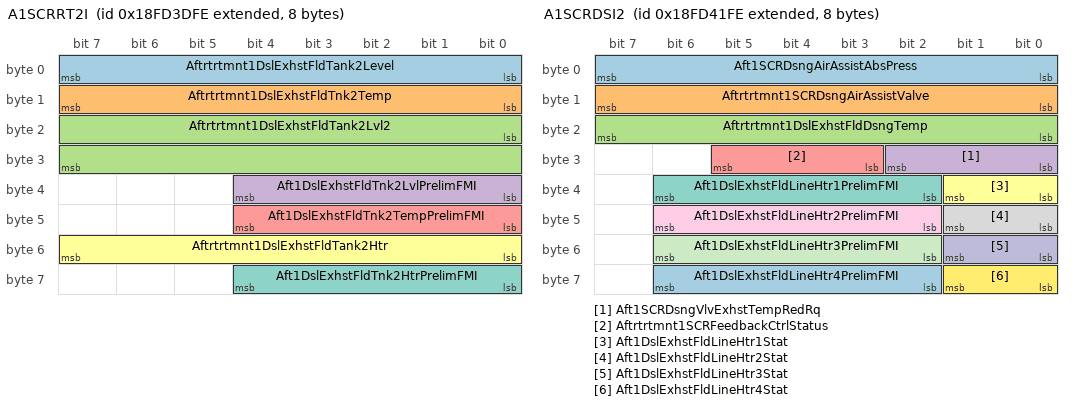
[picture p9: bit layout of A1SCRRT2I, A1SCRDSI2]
BO_ 2566733310 A1SCRRT2I: 8 Vector__XXX
SG_ Aftrtrtmnt1DslExhstFldTank2Level : 0|8@1+ (0.4,0) [0|100] "%" Vector__XXX
SG_ Aftrtrtmnt1DslExhstFldTnk2Temp : 8|8@1+ (1,-40) [-40|210] "deg C" Vector__XXX
SG_ Aftrtrtmnt1DslExhstFldTank2Lvl2 : 16|16@1+ (0.1,0) [0|6425.5] "mm" Vector__XXX
SG_ Aft1DslExhstFldTnk2LvlPrelimFMI : 32|5@1+ (1,0) [0|31] "" Vector__XXX
SG_ Aft1DslExhstFldTnk2TempPrelimFMI : 40|5@1+ (1,0) [0|31] "" Vector__XXX
SG_ Aftrtrtmnt1DslExhstFldTank2Htr : 48|8@1+ (0.4,0) [0|100] "%" Vector__XXX
SG_ Aft1DslExhstFldTnk2HtrPrelimFMI : 56|5@1+ (1,0) [0|31] "" Vector__XXX

BO_ 2499624702 A1SCREGT1: 8 Vector__XXX
SG_ Aftrtrtmnt1SCRIntakeTemperature : 0|16@1+ (0.03125,-273) [-273|1734.96875] "deg C" Vector__XXX
SG_ Aftrtrtmnt1SCRIntkTempPrelimFMI : 16|5@1+ (1,0) [0|31] "" Vector__XXX
SG_ Aftrtrtmnt1SCROutletTemperature : 24|16@1+ (0.03125,-273) [-273|1734.96875] "deg C" Vector__XXX
SG_ Aftrtrtmnt1SCROtltTempPrelimFMI : 40|5@1+ (1,0) [0|31] "" Vector__XXX

BO_ 2566733822 A1SCREGP: 8 Vector__XXX
SG_ Aftrtrtmnt1SCRDiffPressure : 0|16@1+ (0.1,0) [0|6425.5] "kPa" Vector__XXX
SG_ Aftrtrtmnt1SCRDiffPressPrelimFMI : 16|5@1+ (1,0) [0|31] "" Vector__XXX
SG_ Aftertreatment1SCRIntakePressure : 24|16@1+ (0.1,-3212.7) [-3212.7|3212.8] "kPa" Vector__XXX
SG_ Aftrtrtmnt1SCRIntakeAbsPressure : 40|16@1+ (0.1,0) [0|6425.5] "kPa" Vector__XXX

BO_ 2566734078 A1SCRDSR2: 8 Vector__XXX
SG_ Aft1DslExhstFldDsrFltSupPrsionRq : 2|2@1+ (1,0) [0|3] "" Vector__XXX
SG_ Aft1DslExhstFldDoserHeatingMdeRq : 4|3@1+ (1,0) [0|7] "" Vector__XXX
SG_ Aftrtrtmnt1DslExhstFldLineHtr1 : 8|2@1+ (1,0) [0|3] "" Vector__XXX
SG_ Aftrtrtmnt1DslExhstFldLineHtr2 : 10|2@1+ (1,0) [0|3] "" Vector__XXX
SG_ Aftrtrtmnt1DslExhstFldLineHtr3 : 12|2@1+ (1,0) [0|3] "" Vector__XXX
SG_ Aftrtrtmnt1DslExhstFldLineHtr4 : 14|2@1+ (1,0) [0|3] "" Vector__XXX
SG_ Aftrtrtmnt1DslExhstFldTankHtrCmd : 16|8@1+ (0.4,0) [0|100] "%" Vector__XXX
SG_ Aftrtrtmnt1DslExhstFldTnk2HtrCmd : 24|8@1+ (0.4,0) [0|100] "%" Vector__XXX
SG_ Aftrtrtmnt1DslExhstFldPumpHtrCmd : 32|8@1+ (0.4,0) [0|100] "%" Vector__XXX
SG_ Aft1DslExhstFldLineHtrRely1 : 40|2@1+ (1,0) [0|3] "" Vector__XXX
SG_ Aft1DslExhstFldLineHtrRely2 : 42|2@1+ (1,0) [0|3] "" Vector__XXX
SG_ Aft1DslExhstFldLineHtrRely3 : 44|2@1+ (1,0) [0|3] "" Vector__XXX
SG_ Aftrtrtmnt1DslExhstFldLineHtr5 : 46|2@1+ (1,0) [0|3] "" Vector__XXX
SG_ Aftrtrtmnt1DslExhstFldLineHtr6 : 48|2@1+ (1,0) [0|3] "" Vector__XXX
SG_ Aftrtrtmnt1DslExhstFldLineHtr7 : 50|2@1+ (1,0) [0|3] "" Vector__XXX
SG_ Aftrtrtmnt1DslExhstFldLineHtr8 : 52|2@1+ (1,0) [0|3] "" Vector__XXX
SG_ Aftrtrtmnt1DslExhstFldLineHtr9 : 54|2@1+ (1,0) [0|3] "" Vector__XXX
SG_ Aftrtrtmnt1DslExhstFldLineHtr10 : 56|2@1+ (1,0) [0|3] "" Vector__XXX

BO_ 2566734334 A1SCRDSI2: 8 Vector__XXX
SG_ Aft1SCRDsngAirAssistAbsPress : 0|8@1+ (8,0) [0|2000] "kPa" Vector__XXX
SG_ Aftrtrtmnt1SCRDsngAirAssistValve : 8|8@1+ (0.4,0) [0|100] "%" Vector__XXX
SG_ Aftrtrtmnt1DslExhstFldDsngTemp : 16|8@1+ (1,-40) [-40|210] "deg C" Vector__XXX
SG_ Aft1SCRDsngVlvExhstTempRedRq : 24|3@1+ (1,0) [0|7] "" Vector__XXX
SG_ Aftrtrtmnt1SCRFeedbackCtrlStatus : 27|3@1+ (1,0) [0|7] "" Vector__XXX
SG_ Aft1DslExhstFldLineHtr1Stat : 32|2@1+ (1,0) [0|3] "" Vector__XXX
SG_ Aft1DslExhstFldLineHtr1PrelimFMI : 34|5@1+ (1,0) [0|31] "" Vector__XXX
SG_ Aft1DslExhstFldLineHtr2Stat : 40|2@1+ (1,0) [0|3] "" Vector__XXX
SG_ Aft1DslExhstFldLineHtr2PrelimFMI : 42|5@1+ (1,0) [0|31] "" Vector__XXX
SG_ Aft1DslExhstFldLineHtr3Stat : 48|2@1+ (1,0) [0|3] "" Vector__XXX
SG_ Aft1DslExhstFldLineHtr3PrelimFMI : 50|5@1+ (1,0) [0|31] "" Vector__XXX
SG_ Aft1DslExhstFldLineHtr4Stat : 56|2@1+ (1,0) [0|3] "" Vector__XXX
SG_ Aft1DslExhstFldLineHtr4PrelimFMI : 58|5@1+ (1,0) [0|31] "" Vector__XXX

BO_ 2566734590 ICC: 8 Vector__XXX
SG_ ISOBUSComplianceCertYear : 0|6@1+ (1,2000) [2000|2061] "Years" Vector__XXX
SG_ ISOBUSComplianceCertRevision : 6|3@1+ (1,0) [0|7] "" Vector__XXX
SG_ ISOBUSCmplncCertLaboratoryType : 9|3@1+ (1,0) [0|7] "" Vector__XXX
SG_ ISOBUSComplianceCertLaboratoryID : 13|11@1+ (1,0) [0|2047] "" Vector__XXX
SG_ ISOBUSCmplncCertTypeVTWrkSetMmbr : 24|1@1+ (1,0) [0|1] "" Vector__XXX
SG_ ISOBUSCmplncCertTypeVTWrkSetMstr : 25|1@1+ (1,0) [0|1] "" Vector__XXX
SG_ ISOBUSCmplncCertTypeVrtlTerminal : 26|1@1+ (1,0) [0|1] "" Vector__XXX
SG_ ISOBUSCmplncCertTypeClass3ECU : 27|1@1+ (1,0) [0|1] "" Vector__XXX
SG_ ISOBUSCmplncCertTypeTECUClass3 : 28|1@1+ (1,0) [0|1] "" Vector__XXX
SG_ ISOBUSCmplncCertTypeTECUClass2 : 29|1@1+ (1,0) [0|1] "" Vector__XXX
SG_ ISOBUSCmplncCertTypeTECUClass1 : 30|1@1+ (1,0) [0|1] "" Vector__XXX
SG_ ISOBUSCmplncCertTypeMinimumECU : 31|1@1+ (1,0) [0|1] "" Vector__XXX
SG_ ISOBUSCmplncCertTypeGPSReceiver : 35|1@1+ (1,0) [0|1] "" Vector__XXX
SG_ ISOBUSCmplncCertTypeFileServer : 36|1@1+ (1,0) [0|1] "" Vector__XXX
SG_ ISOBUSCmplncCertTypeTCWrkSetMmbr : 37|1@1+ (1,0) [0|1] "" Vector__XXX
SG_ ISOBUSCmplncCertTypeTCWrkSetMstr : 38|1@1+ (1,0) [0|1] "" Vector__XXX
SG_ ISOBUSCmplncCertTypeTaskCtrller : 39|1@1+ (1,0) [0|1] "" Vector__XXX
SG_ ISOBUSCmplncCertReferenceNumber : 48|16@1+ (1,0) [0|65535] "" Vector__XXX

BO_ 2566734846 MSSC: 8 Vector__XXX
SG_ MachineSelectedSpeedSetpointCmd : 0|16@1+ (0.001,0) [0|64.255] "m/s" Vector__XXX
SG_ MachineSelectedSpeedSetpointLmt : 16|16@1+ (0.001,0) [0|64.255] "m/s" Vector__XXX
SG_ MachineSlctedSpeedExitReasonCode : 48|5@1+ (1,0) [0|31] "" Vector__XXX
SG_ MachineSelectedDirectionCommand : 56|2@1+ (1,0) [0|3] "" Vector__XXX

BO_ 2566735102 AT2FC2: 8 Vector__XXX
SG_ Aftertreatment2FuelPressure2 : 0|16@1+ (0.1,0) [0|6425.5] "kPa" Vector__XXX
SG_ Aftrtrtmnt2FuelPumpRelayControl : 16|2@1+ (1,0) [0|3] "" Vector__XXX
SG_ Aft2FuelFlwDiverterVlvCtrl : 18|2@1+ (1,0) [0|3] "" Vector__XXX
SG_ Aftrtrtmnt2FuelPressure2Control : 24|16@1+ (0.0025,0) [0|160.6375] "%" Vector__XXX

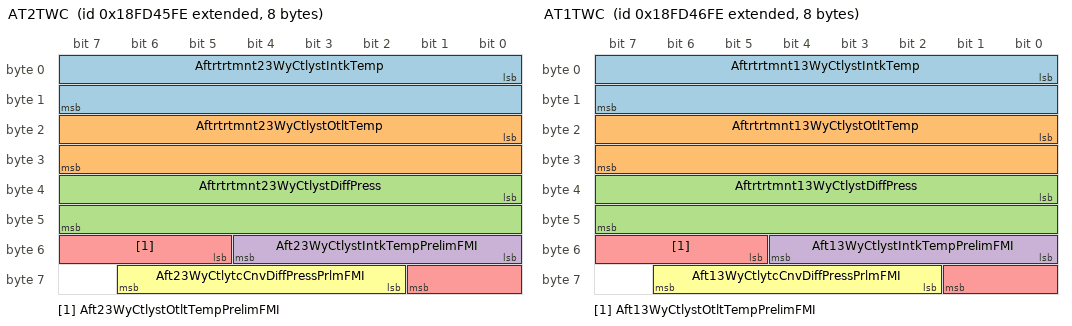
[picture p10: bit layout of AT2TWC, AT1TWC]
BO_ 2566735358 AT2TWC: 8 Vector__XXX
SG_ Aftrtrtmnt23WyCtlystIntkTemp : 0|16@1+ (0.03125,-273) [-273|1734.96875] "deg C" Vector__XXX
SG_ Aftrtrtmnt23WyCtlystOtltTemp : 16|16@1+ (0.03125,-273) [-273|1734.96875] "deg C" Vector__XXX
SG_ Aftrtrtmnt23WyCtlystDiffPress : 32|16@1+ (0.1,0) [0|6425.5] "kPa" Vector__XXX
SG_ Aft23WyCtlystIntkTempPrelimFMI : 48|5@1+ (1,0) [0|31] "" Vector__XXX
SG_ Aft23WyCtlystOtltTempPrelimFMI : 53|5@1+ (1,0) [0|31] "" Vector__XXX
SG_ Aft23WyCtlytcCnvDiffPressPrlmFMI : 58|5@1+ (1,0) [0|31] "" Vector__XXX

BO_ 2566735614 AT1TWC: 8 Vector__XXX
SG_ Aftrtrtmnt13WyCtlystIntkTemp : 0|16@1+ (0.03125,-273) [-273|1734.96875] "deg C" Vector__XXX
SG_ Aftrtrtmnt13WyCtlystOtltTemp : 16|16@1+ (0.03125,-273) [-273|1734.96875] "deg C" Vector__XXX
SG_ Aftrtrtmnt13WyCtlystDiffPress : 32|16@1+ (0.1,0) [0|6425.5] "kPa" Vector__XXX
SG_ Aft13WyCtlystIntkTempPrelimFMI : 48|5@1+ (1,0) [0|31] "" Vector__XXX
SG_ Aft13WyCtlystOtltTempPrelimFMI : 53|5@1+ (1,0) [0|31] "" Vector__XXX
SG_ Aft13WyCtlytcCnvDiffPressPrlmFMI : 58|5@1+ (1,0) [0|31] "" Vector__XXX

BO_ 2633844734 TML: 8 Vector__XXX

BO_ 2566736126 O2FT2: 8 Vector__XXX
SG_ LongTermFuelTrimBank2 : 0|16@1+ (0.1,-3212.75) [-3212.75|3212.75] "%" Vector__XXX
SG_ ShortTermFuelTrimBank2 : 16|16@1+ (0.1,-3212.75) [-3212.75|3212.75] "%" Vector__XXX
SG_ EngExhstBnk2O2SensorClsdLpOp : 32|4@1+ (1,0) [0|15] "" Vector__XXX

BO_ 2566736382 O2FT1: 8 Vector__XXX
SG_ LongTermFuelTrimBank1 : 0|16@1+ (0.1,-3212.75) [-3212.75|3212.75] "%" Vector__XXX
SG_ ShortTermFuelTrimBank1 : 16|16@1+ (0.1,-3212.75) [-3212.75|3212.75] "%" Vector__XXX
SG_ EngExhstBnk1O2SensorClsdLpOp : 32|4@1+ (1,0) [0|15] "" Vector__XXX

BO_ 2432520702 ACCVC: 8 Vector__XXX
SG_ AftercoolerCoolantThermostatMode : 0|2@1+ (1,0) [0|3] "" Vector__XXX
SG_ DsrdAftrclrCoolntIntkTemperature : 8|8@1+ (1,-40) [-40|210] "deg C" Vector__XXX
SG_ DsrdAftrclrCoolntThrmsttOpening : 16|8@1+ (0.4,0) [0|100] "%" Vector__XXX
SG_ EngineChrgAirCoolBypssValve1Cmd : 24|16@1+ (0.0025,0) [0|160.6375] "%" Vector__XXX
SG_ EngineChrgAirCoolBypssValve2Cmd : 40|16@1+ (0.0025,0) [0|160.6375] "%" Vector__XXX

BO_ 2432520958 ECCVC: 8 Vector__XXX
SG_ EngineCoolantThermostatMode : 0|2@1+ (1,0) [0|3] "" Vector__XXX
SG_ DsrdEngCoolntPumpOtltTemperature : 8|8@1+ (1,-40) [-40|210] "deg C" Vector__XXX
SG_ DsrdEngCoolntThermostatOpening : 16|8@1+ (0.4,0) [0|100] "%" Vector__XXX
SG_ EngineAuxCoolSupplyValve1ActrCmd : 24|8@1+ (0.4,0) [0|100] "%" Vector__XXX
SG_ EngineAuxCoolSupplyValve2ActrCmd : 32|8@1+ (0.4,0) [0|100] "%" Vector__XXX

BO_ 2499630078 EAI: 8 Vector__XXX
SG_ EngineExhaustTemperatureAverage : 0|16@1+ (0.03125,-273) [-273|1734.96875] "deg C" Vector__XXX
SG_ EngineExhaustBnk1TemperatureAvrg : 16|16@1+ (0.03125,-273) [-273|1734.96875] "deg C" Vector__XXX
SG_ EngineExhaustBnk2TemperatureAvrg : 32|16@1+ (0.03125,-273) [-273|1734.96875] "deg C" Vector__XXX

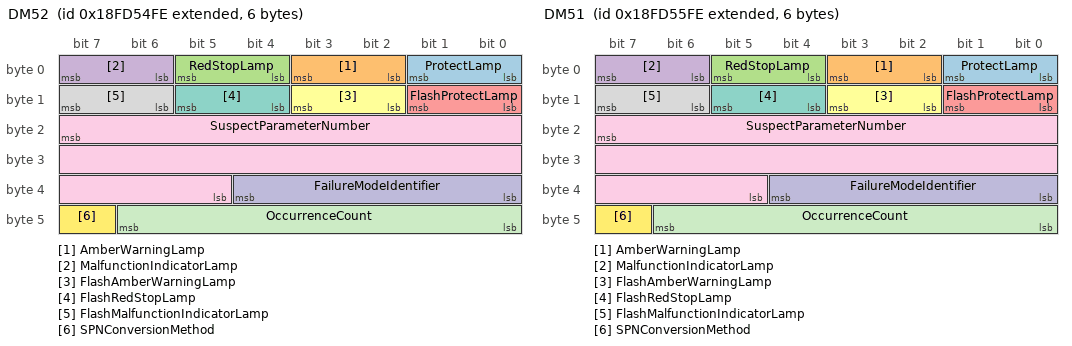
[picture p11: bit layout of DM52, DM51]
BO_ 2566739198 DM52: 6 Vector__XXX
SG_ ProtectLamp : 0|2@1+ (1,0) [0|3] "" Vector__XXX
SG_ AmberWarningLamp : 2|2@1+ (1,0) [0|3] "" Vector__XXX
SG_ RedStopLamp : 4|2@1+ (1,0) [0|3] "" Vector__XXX
SG_ MalfunctionIndicatorLamp : 6|2@1+ (1,0) [0|3] "" Vector__XXX
SG_ FlashProtectLamp : 8|2@1+ (1,0) [0|3] "" Vector__XXX
SG_ FlashAmberWarningLamp : 10|2@1+ (1,0) [0|3] "" Vector__XXX
SG_ FlashRedStopLamp : 12|2@1+ (1,0) [0|3] "" Vector__XXX
SG_ FlashMalfunctionIndicatorLamp : 14|2@1+ (1,0) [0|3] "" Vector__XXX
SG_ SuspectParameterNumber : 23|19@0+ (1,0) [0|524287] "" Vector__XXX
SG_ FailureModeIdentifier : 32|5@1+ (1,0) [0|31] "" Vector__XXX
SG_ OccurrenceCount : 40|7@1+ (1,0) [0|127] "" Vector__XXX
SG_ SPNConversionMethod : 47|1@1+ (1,0) [0|1] "" Vector__XXX

BO_ 2566739454 DM51: 6 Vector__XXX
SG_ ProtectLamp : 0|2@1+ (1,0) [0|3] "" Vector__XXX
SG_ AmberWarningLamp : 2|2@1+ (1,0) [0|3] "" Vector__XXX
SG_ RedStopLamp : 4|2@1+ (1,0) [0|3] "" Vector__XXX
SG_ MalfunctionIndicatorLamp : 6|2@1+ (1,0) [0|3] "" Vector__XXX
SG_ FlashProtectLamp : 8|2@1+ (1,0) [0|3] "" Vector__XXX
SG_ FlashAmberWarningLamp : 10|2@1+ (1,0) [0|3] "" Vector__XXX
SG_ FlashRedStopLamp : 12|2@1+ (1,0) [0|3] "" Vector__XXX
SG_ FlashMalfunctionIndicatorLamp : 14|2@1+ (1,0) [0|3] "" Vector__XXX
SG_ SuspectParameterNumber : 23|19@0+ (1,0) [0|524287] "" Vector__XXX
SG_ FailureModeIdentifier : 32|5@1+ (1,0) [0|31] "" Vector__XXX
SG_ OccurrenceCount : 40|7@1+ (1,0) [0|127] "" Vector__XXX
SG_ SPNConversionMethod : 47|1@1+ (1,0) [0|1] "" Vector__XXX

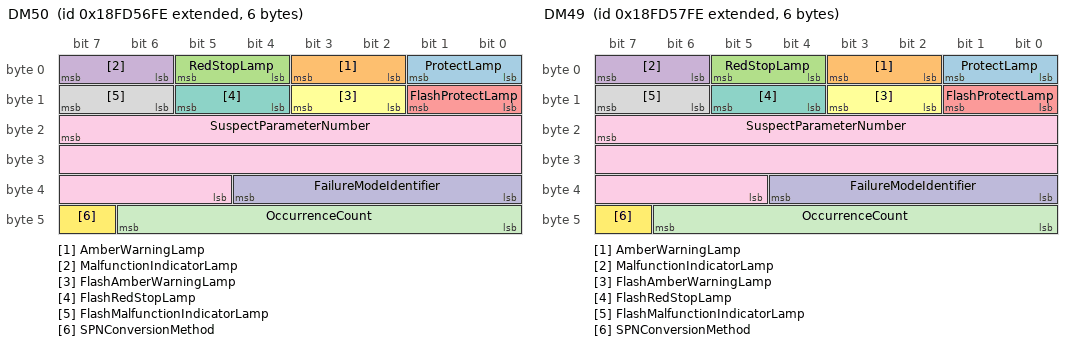
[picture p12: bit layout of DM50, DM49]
BO_ 2566739710 DM50: 6 Vector__XXX
SG_ ProtectLamp : 0|2@1+ (1,0) [0|3] "" Vector__XXX
SG_ AmberWarningLamp : 2|2@1+ (1,0) [0|3] "" Vector__XXX
SG_ RedStopLamp : 4|2@1+ (1,0) [0|3] "" Vector__XXX
SG_ MalfunctionIndicatorLamp : 6|2@1+ (1,0) [0|3] "" Vector__XXX
SG_ FlashProtectLamp : 8|2@1+ (1,0) [0|3] "" Vector__XXX
SG_ FlashAmberWarningLamp : 10|2@1+ (1,0) [0|3] "" Vector__XXX
SG_ FlashRedStopLamp : 12|2@1+ (1,0) [0|3] "" Vector__XXX
SG_ FlashMalfunctionIndicatorLamp : 14|2@1+ (1,0) [0|3] "" Vector__XXX
SG_ SuspectParameterNumber : 23|19@0+ (1,0) [0|524287] "" Vector__XXX
SG_ FailureModeIdentifier : 32|5@1+ (1,0) [0|31] "" Vector__XXX
SG_ OccurrenceCount : 40|7@1+ (1,0) [0|127] "" Vector__XXX
SG_ SPNConversionMethod : 47|1@1+ (1,0) [0|1] "" Vector__XXX

BO_ 2566739966 DM49: 6 Vector__XXX
SG_ ProtectLamp : 0|2@1+ (1,0) [0|3] "" Vector__XXX
SG_ AmberWarningLamp : 2|2@1+ (1,0) [0|3] "" Vector__XXX
SG_ RedStopLamp : 4|2@1+ (1,0) [0|3] "" Vector__XXX
SG_ MalfunctionIndicatorLamp : 6|2@1+ (1,0) [0|3] "" Vector__XXX
SG_ FlashProtectLamp : 8|2@1+ (1,0) [0|3] "" Vector__XXX
SG_ FlashAmberWarningLamp : 10|2@1+ (1,0) [0|3] "" Vector__XXX
SG_ FlashRedStopLamp : 12|2@1+ (1,0) [0|3] "" Vector__XXX
SG_ FlashMalfunctionIndicatorLamp : 14|2@1+ (1,0) [0|3] "" Vector__XXX
SG_ SuspectParameterNumber : 23|19@0+ (1,0) [0|524287] "" Vector__XXX
SG_ FailureModeIdentifier : 32|5@1+ (1,0) [0|31] "" Vector__XXX
SG_ OccurrenceCount : 40|7@1+ (1,0) [0|127] "" Vector__XXX
SG_ SPNConversionMethod : 47|1@1+ (1,0) [0|1] "" Vector__XXX

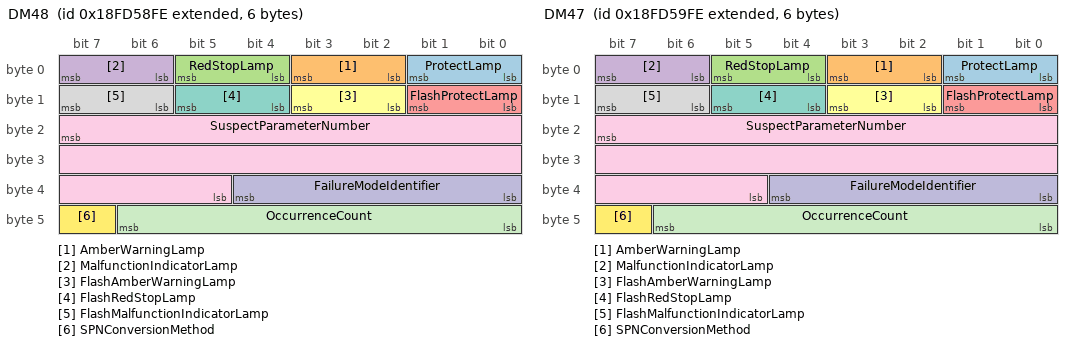
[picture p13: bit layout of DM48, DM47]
BO_ 2566740222 DM48: 6 Vector__XXX
SG_ ProtectLamp : 0|2@1+ (1,0) [0|3] "" Vector__XXX
SG_ AmberWarningLamp : 2|2@1+ (1,0) [0|3] "" Vector__XXX
SG_ RedStopLamp : 4|2@1+ (1,0) [0|3] "" Vector__XXX
SG_ MalfunctionIndicatorLamp : 6|2@1+ (1,0) [0|3] "" Vector__XXX
SG_ FlashProtectLamp : 8|2@1+ (1,0) [0|3] "" Vector__XXX
SG_ FlashAmberWarningLamp : 10|2@1+ (1,0) [0|3] "" Vector__XXX
SG_ FlashRedStopLamp : 12|2@1+ (1,0) [0|3] "" Vector__XXX
SG_ FlashMalfunctionIndicatorLamp : 14|2@1+ (1,0) [0|3] "" Vector__XXX
SG_ SuspectParameterNumber : 23|19@0+ (1,0) [0|524287] "" Vector__XXX
SG_ FailureModeIdentifier : 32|5@1+ (1,0) [0|31] "" Vector__XXX
SG_ OccurrenceCount : 40|7@1+ (1,0) [0|127] "" Vector__XXX
SG_ SPNConversionMethod : 47|1@1+ (1,0) [0|1] "" Vector__XXX

BO_ 2566740478 DM47: 6 Vector__XXX
SG_ ProtectLamp : 0|2@1+ (1,0) [0|3] "" Vector__XXX
SG_ AmberWarningLamp : 2|2@1+ (1,0) [0|3] "" Vector__XXX
SG_ RedStopLamp : 4|2@1+ (1,0) [0|3] "" Vector__XXX
SG_ MalfunctionIndicatorLamp : 6|2@1+ (1,0) [0|3] "" Vector__XXX
SG_ FlashProtectLamp : 8|2@1+ (1,0) [0|3] "" Vector__XXX
SG_ FlashAmberWarningLamp : 10|2@1+ (1,0) [0|3] "" Vector__XXX
SG_ FlashRedStopLamp : 12|2@1+ (1,0) [0|3] "" Vector__XXX
SG_ FlashMalfunctionIndicatorLamp : 14|2@1+ (1,0) [0|3] "" Vector__XXX
SG_ SuspectParameterNumber : 23|19@0+ (1,0) [0|524287] "" Vector__XXX
SG_ FailureModeIdentifier : 32|5@1+ (1,0) [0|31] "" Vector__XXX
SG_ OccurrenceCount : 40|7@1+ (1,0) [0|127] "" Vector__XXX
SG_ SPNConversionMethod : 47|1@1+ (1,0) [0|1] "" Vector__XXX

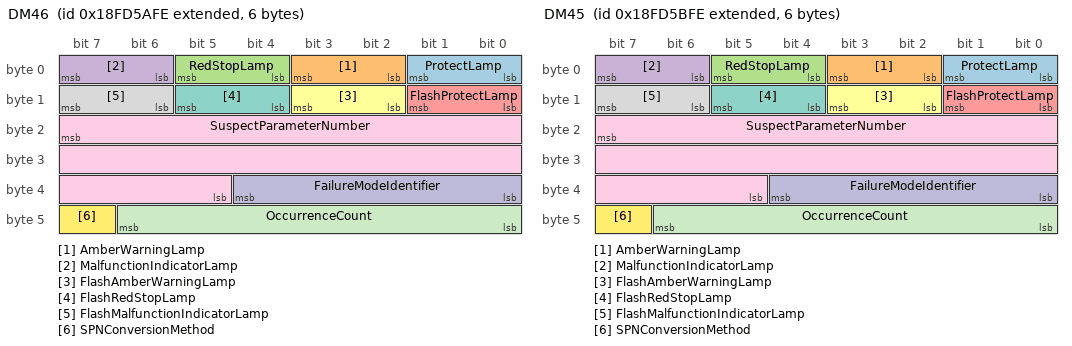
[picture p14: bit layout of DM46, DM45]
BO_ 2566740734 DM46: 6 Vector__XXX
SG_ ProtectLamp : 0|2@1+ (1,0) [0|3] "" Vector__XXX
SG_ AmberWarningLamp : 2|2@1+ (1,0) [0|3] "" Vector__XXX
SG_ RedStopLamp : 4|2@1+ (1,0) [0|3] "" Vector__XXX
SG_ MalfunctionIndicatorLamp : 6|2@1+ (1,0) [0|3] "" Vector__XXX
SG_ FlashProtectLamp : 8|2@1+ (1,0) [0|3] "" Vector__XXX
SG_ FlashAmberWarningLamp : 10|2@1+ (1,0) [0|3] "" Vector__XXX
SG_ FlashRedStopLamp : 12|2@1+ (1,0) [0|3] "" Vector__XXX
SG_ FlashMalfunctionIndicatorLamp : 14|2@1+ (1,0) [0|3] "" Vector__XXX
SG_ SuspectParameterNumber : 23|19@0+ (1,0) [0|524287] "" Vector__XXX
SG_ FailureModeIdentifier : 32|5@1+ (1,0) [0|31] "" Vector__XXX
SG_ OccurrenceCount : 40|7@1+ (1,0) [0|127] "" Vector__XXX
SG_ SPNConversionMethod : 47|1@1+ (1,0) [0|1] "" Vector__XXX

BO_ 2566740990 DM45: 6 Vector__XXX
SG_ ProtectLamp : 0|2@1+ (1,0) [0|3] "" Vector__XXX
SG_ AmberWarningLamp : 2|2@1+ (1,0) [0|3] "" Vector__XXX
SG_ RedStopLamp : 4|2@1+ (1,0) [0|3] "" Vector__XXX
SG_ MalfunctionIndicatorLamp : 6|2@1+ (1,0) [0|3] "" Vector__XXX
SG_ FlashProtectLamp : 8|2@1+ (1,0) [0|3] "" Vector__XXX
SG_ FlashAmberWarningLamp : 10|2@1+ (1,0) [0|3] "" Vector__XXX
SG_ FlashRedStopLamp : 12|2@1+ (1,0) [0|3] "" Vector__XXX
SG_ FlashMalfunctionIndicatorLamp : 14|2@1+ (1,0) [0|3] "" Vector__XXX
SG_ SuspectParameterNumber : 23|19@0+ (1,0) [0|524287] "" Vector__XXX
SG_ FailureModeIdentifier : 32|5@1+ (1,0) [0|31] "" Vector__XXX
SG_ OccurrenceCount : 40|7@1+ (1,0) [0|127] "" Vector__XXX
SG_ SPNConversionMethod : 47|1@1+ (1,0) [0|1] "" Vector__XXX

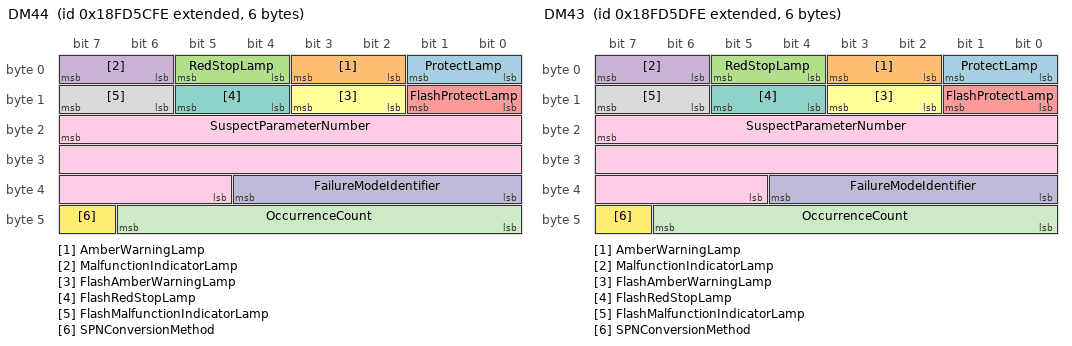
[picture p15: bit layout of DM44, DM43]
BO_ 2566741246 DM44: 6 Vector__XXX
SG_ ProtectLamp : 0|2@1+ (1,0) [0|3] "" Vector__XXX
SG_ AmberWarningLamp : 2|2@1+ (1,0) [0|3] "" Vector__XXX
SG_ RedStopLamp : 4|2@1+ (1,0) [0|3] "" Vector__XXX
SG_ MalfunctionIndicatorLamp : 6|2@1+ (1,0) [0|3] "" Vector__XXX
SG_ FlashProtectLamp : 8|2@1+ (1,0) [0|3] "" Vector__XXX
SG_ FlashAmberWarningLamp : 10|2@1+ (1,0) [0|3] "" Vector__XXX
SG_ FlashRedStopLamp : 12|2@1+ (1,0) [0|3] "" Vector__XXX
SG_ FlashMalfunctionIndicatorLamp : 14|2@1+ (1,0) [0|3] "" Vector__XXX
SG_ SuspectParameterNumber : 23|19@0+ (1,0) [0|524287] "" Vector__XXX
SG_ FailureModeIdentifier : 32|5@1+ (1,0) [0|31] "" Vector__XXX
SG_ OccurrenceCount : 40|7@1+ (1,0) [0|127] "" Vector__XXX
SG_ SPNConversionMethod : 47|1@1+ (1,0) [0|1] "" Vector__XXX

BO_ 2566741502 DM43: 6 Vector__XXX
SG_ ProtectLamp : 0|2@1+ (1,0) [0|3] "" Vector__XXX
SG_ AmberWarningLamp : 2|2@1+ (1,0) [0|3] "" Vector__XXX
SG_ RedStopLamp : 4|2@1+ (1,0) [0|3] "" Vector__XXX
SG_ MalfunctionIndicatorLamp : 6|2@1+ (1,0) [0|3] "" Vector__XXX
SG_ FlashProtectLamp : 8|2@1+ (1,0) [0|3] "" Vector__XXX
SG_ FlashAmberWarningLamp : 10|2@1+ (1,0) [0|3] "" Vector__XXX
SG_ FlashRedStopLamp : 12|2@1+ (1,0) [0|3] "" Vector__XXX
SG_ FlashMalfunctionIndicatorLamp : 14|2@1+ (1,0) [0|3] "" Vector__XXX
SG_ SuspectParameterNumber : 23|19@0+ (1,0) [0|524287] "" Vector__XXX
SG_ FailureModeIdentifier : 32|5@1+ (1,0) [0|31] "" Vector__XXX
SG_ OccurrenceCount : 40|7@1+ (1,0) [0|127] "" Vector__XXX
SG_ SPNConversionMethod : 47|1@1+ (1,0) [0|1] "" Vector__XXX

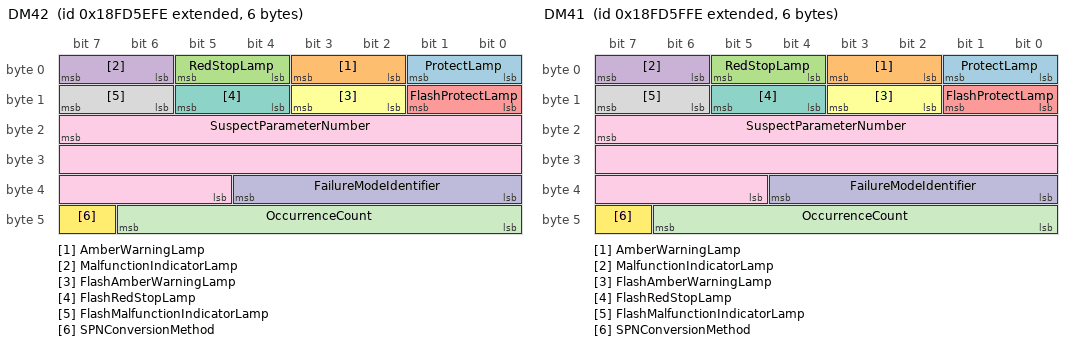
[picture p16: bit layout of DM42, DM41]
BO_ 2566741758 DM42: 6 Vector__XXX
SG_ ProtectLamp : 0|2@1+ (1,0) [0|3] "" Vector__XXX
SG_ AmberWarningLamp : 2|2@1+ (1,0) [0|3] "" Vector__XXX
SG_ RedStopLamp : 4|2@1+ (1,0) [0|3] "" Vector__XXX
SG_ MalfunctionIndicatorLamp : 6|2@1+ (1,0) [0|3] "" Vector__XXX
SG_ FlashProtectLamp : 8|2@1+ (1,0) [0|3] "" Vector__XXX
SG_ FlashAmberWarningLamp : 10|2@1+ (1,0) [0|3] "" Vector__XXX
SG_ FlashRedStopLamp : 12|2@1+ (1,0) [0|3] "" Vector__XXX
SG_ FlashMalfunctionIndicatorLamp : 14|2@1+ (1,0) [0|3] "" Vector__XXX
SG_ SuspectParameterNumber : 23|19@0+ (1,0) [0|524287] "" Vector__XXX
SG_ FailureModeIdentifier : 32|5@1+ (1,0) [0|31] "" Vector__XXX
SG_ OccurrenceCount : 40|7@1+ (1,0) [0|127] "" Vector__XXX
SG_ SPNConversionMethod : 47|1@1+ (1,0) [0|1] "" Vector__XXX

BO_ 2566742014 DM41: 6 Vector__XXX
SG_ ProtectLamp : 0|2@1+ (1,0) [0|3] "" Vector__XXX
SG_ AmberWarningLamp : 2|2@1+ (1,0) [0|3] "" Vector__XXX
SG_ RedStopLamp : 4|2@1+ (1,0) [0|3] "" Vector__XXX
SG_ MalfunctionIndicatorLamp : 6|2@1+ (1,0) [0|3] "" Vector__XXX
SG_ FlashProtectLamp : 8|2@1+ (1,0) [0|3] "" Vector__XXX
SG_ FlashAmberWarningLamp : 10|2@1+ (1,0) [0|3] "" Vector__XXX
SG_ FlashRedStopLamp : 12|2@1+ (1,0) [0|3] "" Vector__XXX
SG_ FlashMalfunctionIndicatorLamp : 14|2@1+ (1,0) [0|3] "" Vector__XXX
SG_ SuspectParameterNumber : 23|19@0+ (1,0) [0|524287] "" Vector__XXX
SG_ FailureModeIdentifier : 32|5@1+ (1,0) [0|31] "" Vector__XXX
SG_ OccurrenceCount : 40|7@1+ (1,0) [0|127] "" Vector__XXX
SG_ SPNConversionMethod : 47|1@1+ (1,0) [0|1] "" Vector__XXX

BO_ 2566742270 DM40: 8 Vector__XXX
SG_ SuspectParameterNumber : 7|19@0+ (1,0) [0|524287] "" Vector__XXX
SG_ FailureModeIdentifier : 16|5@1+ (1,0) [0|31] "" Vector__XXX
SG_ FailureSpecificB1Counter : 24|16@1+ (0.1,0) [0|6425.5] "h" Vector__XXX

BO_ 2566742526 DM39: 8 Vector__XXX
SG_ SystemCumulativeContinuousMITime : 0|32@1+ (0.05,0) [0|210554060.75] "h" Vector__XXX
SG_ SystemGreatestB1Counter : 32|16@1+ (0.1,0) [0|6425.5] "h" Vector__XXX

BO_ 2566742782 DM38: 25 Vector__XXX
SG_ GloblTechnicalRegulationDescript : 7|200@0+ (1,0) [0|0] "" Vector__XXX

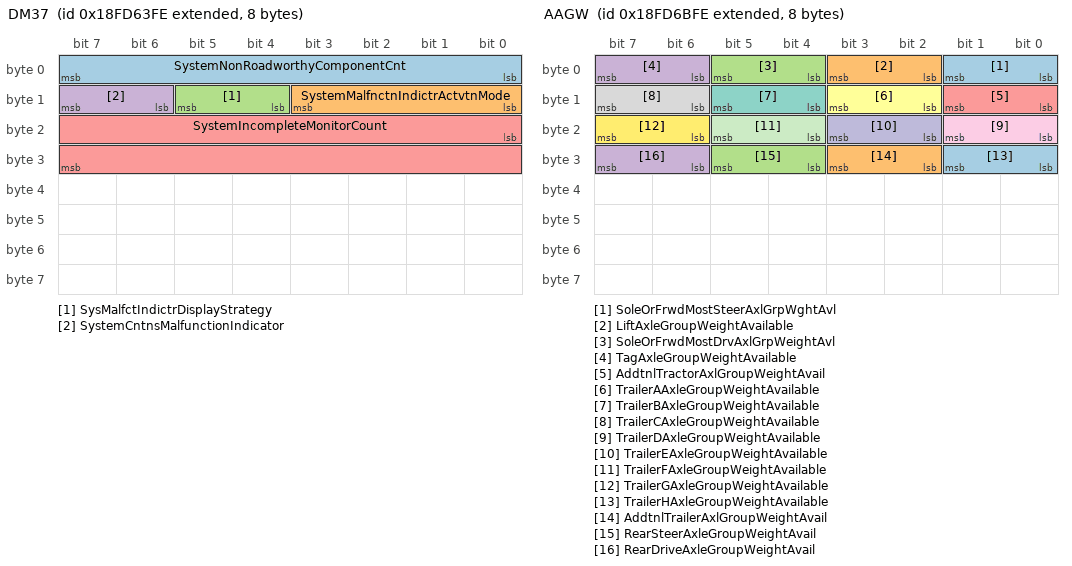
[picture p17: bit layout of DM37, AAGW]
BO_ 2566743038 DM37: 8 Vector__XXX
SG_ SystemNonRoadworthyComponentCnt : 0|8@1+ (1,0) [0|250] "" Vector__XXX
SG_ SystemMalfnctnIndictrActvtnMode : 8|4@1+ (1,0) [0|15] "" Vector__XXX
SG_ SysMalfctIndictrDisplayStrategy : 12|2@1+ (1,0) [0|3] "" Vector__XXX
SG_ SystemCntnsMalfunctionIndicator : 14|2@1+ (1,0) [0|3] "" Vector__XXX
SG_ SystemIncompleteMonitorCount : 16|16@1+ (1,0) [0|64255] "" Vector__XXX

BO_ 2566743294 DM36: 8 Vector__XXX
SG_ VehicleCurrentMIAccumulatedTime : 32|16@1+ (1,0) [0|64255] "min" Vector__XXX

BO_ 2566743550 AT1FC2: 8 Vector__XXX
SG_ Aftertreatment1FuelPressure2 : 0|16@1+ (0.1,0) [0|6425.5] "kPa" Vector__XXX
SG_ Aftrtrtmnt1FuelPumpRelayControl : 16|2@1+ (1,0) [0|3] "" Vector__XXX
SG_ Aft1FuelFlwDiverterVlvCtrl : 18|2@1+ (1,0) [0|3] "" Vector__XXX
SG_ Aftrtrtmnt1FuelPressure2ActrCtrl : 24|16@1+ (0.0025,0) [0|160.6375] "%" Vector__XXX
SG_ Aft1HydrocarbonDoserIntkFuelTemp : 40|8@1+ (1,-40) [-40|210] "deg C" Vector__XXX

BO_ 2566743806 ET4: 8 Vector__XXX
SG_ EngineCoolantTemperature2 : 0|8@1+ (1,-40) [-40|210] "deg C" Vector__XXX
SG_ EngCoolntPumpOutletTemperature : 8|8@1+ (1,-40) [-40|210] "deg C" Vector__XXX
SG_ EngineCoolantThermostatOpening : 16|8@1+ (0.4,0) [0|100] "%" Vector__XXX
SG_ EngExhstValveActSysOilTemp : 24|16@1+ (0.03125,-273) [-273|1734.96875] "deg C" Vector__XXX
SG_ EngExhstGasRecirc1MixerIntkTemp : 40|16@1+ (0.03125,-273) [-273|1734.96875] "deg C" Vector__XXX
SG_ EngineCoolantTemperature3 : 56|8@1+ (1,-40) [-40|210] "deg C" Vector__XXX

BO_ 2566744062 ZNVW: 8 Vector__XXX
SG_ ZeroNetVehicleWeightChange : 0|2@1+ (1,0) [0|3] "" Vector__XXX

BO_ 2499635454 GCVW: 8 Vector__XXX
SG_ GrossCombinationWeight : 0|24@1+ (2,0) [0|32899070] "kg" Vector__XXX
SG_ NetVehicleWeightChange : 24|24@1+ (2,-16449535) [-16449535|16449535] "kg" Vector__XXX

BO_ 2633853438 AGCW: 8 Vector__XXX
SG_ AxleGroupLocation : 0|4@1+ (1,0) [0|15] "" Vector__XXX
SG_ AdditionalAxleGroupLocation : 4|4@1+ (1,0) [0|15] "" Vector__XXX
SG_ AxleGroupEmptyWeightCalibration : 8|16@1+ (2,0) [0|128510] "kg" Vector__XXX
SG_ AxleGroupFullWeightCalibration : 24|16@1+ (2,0) [0|128510] "kg" Vector__XXX

BO_ 2499635966 AGW: 8 Vector__XXX
SG_ AxleGroupLocation : 0|4@1+ (1,0) [0|15] "" Vector__XXX
SG_ AdditionalAxleGroupLocation : 4|4@1+ (1,0) [0|15] "" Vector__XXX
SG_ AxleGroupWeight : 8|16@1+ (2,0) [0|128510] "kg" Vector__XXX

BO_ 2566745086 AAGW: 8 Vector__XXX
SG_ SoleOrFrwdMostSteerAxlGrpWghtAvl : 0|2@1+ (1,0) [0|3] "" Vector__XXX
SG_ LiftAxleGroupWeightAvailable : 2|2@1+ (1,0) [0|3] "" Vector__XXX
SG_ SoleOrFrwdMostDrvAxlGrpWeightAvl : 4|2@1+ (1,0) [0|3] "" Vector__XXX
SG_ TagAxleGroupWeightAvailable : 6|2@1+ (1,0) [0|3] "" Vector__XXX
SG_ AddtnlTractorAxlGroupWeightAvail : 8|2@1+ (1,0) [0|3] "" Vector__XXX
SG_ TrailerAAxleGroupWeightAvailable : 10|2@1+ (1,0) [0|3] "" Vector__XXX
SG_ TrailerBAxleGroupWeightAvailable : 12|2@1+ (1,0) [0|3] "" Vector__XXX
SG_ TrailerCAxleGroupWeightAvailable : 14|2@1+ (1,0) [0|3] "" Vector__XXX
SG_ TrailerDAxleGroupWeightAvailable : 16|2@1+ (1,0) [0|3] "" Vector__XXX
SG_ TrailerEAxleGroupWeightAvailable : 18|2@1+ (1,0) [0|3] "" Vector__XXX
SG_ TrailerFAxleGroupWeightAvailable : 20|2@1+ (1,0) [0|3] "" Vector__XXX
SG_ TrailerGAxleGroupWeightAvailable : 22|2@1+ (1,0) [0|3] "" Vector__XXX
SG_ TrailerHAxleGroupWeightAvailable : 24|2@1+ (1,0) [0|3] "" Vector__XXX
SG_ AddtnlTrailerAxlGroupWeightAvail : 26|2@1+ (1,0) [0|3] "" Vector__XXX
SG_ RearSteerAxleGroupWeightAvail : 28|2@1+ (1,0) [0|3] "" Vector__XXX
SG_ RearDriveAxleGroupWeightAvail : 30|2@1+ (1,0) [0|3] "" Vector__XXX

BO_ 2566745342 AT2AC2: 8 Vector__XXX
SG_ Aftrtrtmnt2SecondaryAirDiffPress : 0|16@1+ (0.0078125,-250) [-250|251.99] "kPa" Vector__XXX
SG_ Aftrtrtmnt2SecAirTemperature : 16|16@1+ (0.03125,-273) [-273|1734.96875] "deg C" Vector__XXX
SG_ Aftrtrtmnt2SecAirMassFlwRate : 32|16@1+ (0.2,0) [0|12851] "kg/h" Vector__XXX
SG_ Aftrtrtmnt2SecondaryAirPressure : 48|16@1+ (0.1,0) [0|6425.5] "kPa" Vector__XXX

BO_ 2566745598 AT1AC2: 8 Vector__XXX
SG_ Aftrtrtmnt1SecondaryAirDiffPress : 0|16@1+ (0.0078125,-250) [-250|251.99] "kPa" Vector__XXX
SG_ Aftrtrtmnt1SecAirTemperature : 16|16@1+ (0.03125,-273) [-273|1734.96875] "deg C" Vector__XXX
SG_ Aftrtrtmnt1SecAirMassFlwRate : 32|16@1+ (0.2,0) [0|12851] "kg/h" Vector__XXX
SG_ Aftrtrtmnt1SecondaryAirPressure : 48|16@1+ (0.1,0) [0|6425.5] "kPa" Vector__XXX

BO_ 2566745854 A1SCRSI1: 8 Vector__XXX
SG_ Aft1DslExhstFldAvrgCnsmptn : 0|16@1+ (0.05,0) [0|3212.75] "l/h" Vector__XXX
SG_ Aft1SCRCmdedDslExhstFldCnsmptn : 16|16@1+ (0.05,0) [0|3212.75] "l/h" Vector__XXX
SG_ Aftrtrtmnt1SCRCnvrsnEfficiency : 32|8@1+ (0.4,0) [0|100] "%" Vector__XXX
SG_ AftSCROprtrIndcmntActvTrvledDist : 40|16@1+ (1,0) [0|64255] "km" Vector__XXX
SG_ Aftrtrtmnt1SCRSystemSulfationLvl : 56|8@1+ (1,0) [0|250] "%" Vector__XXX

BO_ 2566746110 EEC8: 8 Vector__XXX
SG_ EngExhstGasRecirc1Valve2Ctrl : 0|16@1+ (0.0025,0) [0|160.6375] "%" Vector__XXX
SG_ EngExhstGasRecirc1CoolIntkTemp : 16|16@1+ (0.03125,-273) [-273|1734.96875] "deg C" Vector__XXX
SG_ EngExhstGasRecirc1ClIntkAbsPress : 32|16@1+ (0.5,0) [0|32127.5] "kPa" Vector__XXX
SG_ EngExhstGasRecirculation1CoolEff : 48|8@1+ (0.4,0) [0|100] "%" Vector__XXX

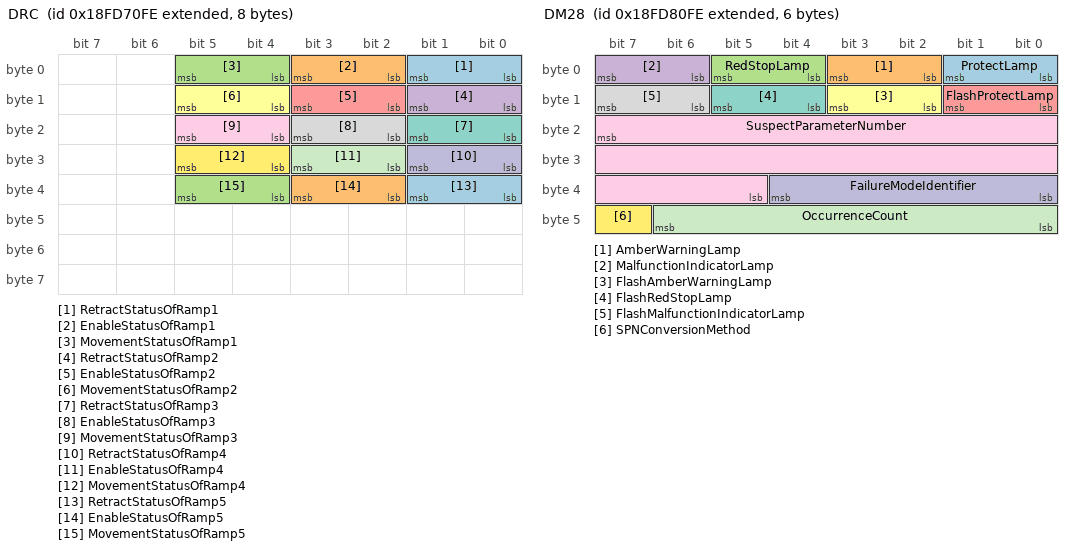
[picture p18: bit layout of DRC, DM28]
BO_ 2566746366 DRC: 8 Vector__XXX
SG_ RetractStatusOfRamp1 : 0|2@1+ (1,0) [0|3] "" Vector__XXX
SG_ EnableStatusOfRamp1 : 2|2@1+ (1,0) [0|3] "" Vector__XXX
SG_ MovementStatusOfRamp1 : 4|2@1+ (1,0) [0|3] "" Vector__XXX
SG_ RetractStatusOfRamp2 : 8|2@1+ (1,0) [0|3] "" Vector__XXX
SG_ EnableStatusOfRamp2 : 10|2@1+ (1,0) [0|3] "" Vector__XXX
SG_ MovementStatusOfRamp2 : 12|2@1+ (1,0) [0|3] "" Vector__XXX
SG_ RetractStatusOfRamp3 : 16|2@1+ (1,0) [0|3] "" Vector__XXX
SG_ EnableStatusOfRamp3 : 18|2@1+ (1,0) [0|3] "" Vector__XXX
SG_ MovementStatusOfRamp3 : 20|2@1+ (1,0) [0|3] "" Vector__XXX
SG_ RetractStatusOfRamp4 : 24|2@1+ (1,0) [0|3] "" Vector__XXX
SG_ EnableStatusOfRamp4 : 26|2@1+ (1,0) [0|3] "" Vector__XXX
SG_ MovementStatusOfRamp4 : 28|2@1+ (1,0) [0|3] "" Vector__XXX
SG_ RetractStatusOfRamp5 : 32|2@1+ (1,0) [0|3] "" Vector__XXX
SG_ EnableStatusOfRamp5 : 34|2@1+ (1,0) [0|3] "" Vector__XXX
SG_ MovementStatusOfRamp5 : 36|2@1+ (1,0) [0|3] "" Vector__XXX

BO_ 2566746622 BSA: 8 Vector__XXX
SG_ TractorBrakeStrokeAxle1Left : 0|3@1+ (1,0) [0|7] "" Vector__XXX
SG_ TractorBrakeStrokeAxle1Right : 3|3@1+ (1,0) [0|7] "" Vector__XXX
SG_ TractorBrakeStrokeAxle2Left : 6|3@1+ (1,0) [0|7] "" Vector__XXX
SG_ TractorBrakeStrokeAxle2Right : 9|3@1+ (1,0) [0|7] "" Vector__XXX
SG_ TractorBrakeStrokeAxle3Left : 12|3@1+ (1,0) [0|7] "" Vector__XXX
SG_ TractorBrakeStrokeAxle3Right : 15|3@1+ (1,0) [0|7] "" Vector__XXX
SG_ TractorBrakeStrokeAxle4Left : 18|3@1+ (1,0) [0|7] "" Vector__XXX
SG_ TractorBrakeStrokeAxle4Right : 21|3@1+ (1,0) [0|7] "" Vector__XXX
SG_ TractorBrakeStrokeAxle5Left : 24|3@1+ (1,0) [0|7] "" Vector__XXX
SG_ TractorBrakeStrokeAxle5Right : 27|3@1+ (1,0) [0|7] "" Vector__XXX
SG_ TrailerBrakeStrokeAxle1Left : 30|3@1+ (1,0) [0|7] "" Vector__XXX
SG_ TrailerBrakeStrokeAxle1Right : 33|3@1+ (1,0) [0|7] "" Vector__XXX
SG_ TrailerBrakeStrokeAxle2Left : 36|3@1+ (1,0) [0|7] "" Vector__XXX
SG_ TrailerBrakeStrokeAxle2Right : 39|3@1+ (1,0) [0|7] "" Vector__XXX
SG_ TrailerBrakeStrokeAxle3Left : 42|3@1+ (1,0) [0|7] "" Vector__XXX
SG_ TrailerBrakeStrokeAxle3Right : 45|3@1+ (1,0) [0|7] "" Vector__XXX
SG_ TrailerBrakeStrokeAxle4Left : 48|3@1+ (1,0) [0|7] "" Vector__XXX
SG_ TrailerBrakeStrokeAxle4Right : 51|3@1+ (1,0) [0|7] "" Vector__XXX
SG_ TrailerBrakeStrokeAxle5Left : 54|3@1+ (1,0) [0|7] "" Vector__XXX
SG_ TrailerBrakeStrokeAxle5Right : 57|3@1+ (1,0) [0|7] "" Vector__XXX

BO_ 2566746878 ESV6: 8 Vector__XXX
SG_ EngineSparkPlug21 : 0|16@1+ (1,0) [0|64255] "V" Vector__XXX
SG_ EngineSparkPlug22 : 16|16@1+ (1,0) [0|64255] "V" Vector__XXX
SG_ EngineSparkPlug23 : 32|16@1+ (1,0) [0|64255] "V" Vector__XXX
SG_ EngineSparkPlug24 : 48|16@1+ (1,0) [0|64255] "V" Vector__XXX

BO_ 2566747134 ESV5: 8 Vector__XXX
SG_ EngineSparkPlug17 : 0|16@1+ (1,0) [0|64255] "V" Vector__XXX
SG_ EngineSparkPlug18 : 16|16@1+ (1,0) [0|64255] "V" Vector__XXX
SG_ EngineSparkPlug19 : 32|16@1+ (1,0) [0|64255] "V" Vector__XXX
SG_ EngineSparkPlug20 : 48|16@1+ (1,0) [0|64255] "V" Vector__XXX

BO_ 2566747390 ESV4: 8 Vector__XXX
SG_ EngineSparkPlug13 : 0|16@1+ (1,0) [0|64255] "V" Vector__XXX
SG_ EngineSparkPlug14 : 16|16@1+ (1,0) [0|64255] "V" Vector__XXX
SG_ EngineSparkPlug15 : 32|16@1+ (1,0) [0|64255] "V" Vector__XXX
SG_ EngineSparkPlug16 : 48|16@1+ (1,0) [0|64255] "V" Vector__XXX

BO_ 2566747646 ESV3: 8 Vector__XXX
SG_ EngineSparkPlug9 : 0|16@1+ (1,0) [0|64255] "V" Vector__XXX
SG_ EngineSparkPlug10 : 16|16@1+ (1,0) [0|64255] "V" Vector__XXX
SG_ EngineSparkPlug11 : 32|16@1+ (1,0) [0|64255] "V" Vector__XXX
SG_ EngineSparkPlug12 : 48|16@1+ (1,0) [0|64255] "V" Vector__XXX

BO_ 2566747902 ESV2: 8 Vector__XXX
SG_ EngineSparkPlug5 : 0|16@1+ (1,0) [0|64255] "V" Vector__XXX
SG_ EngineSparkPlug6 : 16|16@1+ (1,0) [0|64255] "V" Vector__XXX
SG_ EngineSparkPlug7 : 32|16@1+ (1,0) [0|64255] "V" Vector__XXX
SG_ EngineSparkPlug8 : 48|16@1+ (1,0) [0|64255] "V" Vector__XXX

BO_ 2566748158 ESV1: 8 Vector__XXX
SG_ EngineSparkPlug1 : 0|16@1+ (1,0) [0|64255] "V" Vector__XXX
SG_ EngineSparkPlug2 : 16|16@1+ (1,0) [0|64255] "V" Vector__XXX
SG_ EngineSparkPlug3 : 32|16@1+ (1,0) [0|64255] "V" Vector__XXX
SG_ EngineSparkPlug4 : 48|16@1+ (1,0) [0|64255] "V" Vector__XXX

BO_ 2566748414 AT2TI: 32 Vector__XXX
SG_ Aftrtrtmnt2DslPFTripFuelUsed : 0|32@1+ (0.5,0) [0|2105540607.5] "l" Vector__XXX
SG_ Aftrtrtmnt2DslPFTripActvRegenTme : 32|32@1+ (1,0) [0|4211081215] "s" Vector__XXX
SG_ Aftrtrtmnt2DslPFTripDisabledTime : 64|32@1+ (1,0) [0|4211081215] "s" Vector__XXX
SG_ Aft2DslPFTrpNoOfActvRegens : 96|32@1+ (1,0) [0|4211081215] "" Vector__XXX
SG_ Aft2DslPFTrpPassiveRegenTme : 128|32@1+ (1,0) [0|4211081215] "s" Vector__XXX
SG_ Aft2DslPFTrpNoOfPassiveRegens : 160|32@1+ (1,0) [0|4211081215] "" Vector__XXX
SG_ Aft2DslPFTrpNoOfActRegenInhbtRqs : 192|32@1+ (1,0) [0|4211081215] "" Vector__XXX
SG_ Aft2DslPFTrpNoOfActvRegenManRqs : 224|32@1+ (1,0) [0|4211081215] "" Vector__XXX

BO_ 2566748670 AT1TI: 32 Vector__XXX
SG_ Aftrtrtmnt1DslPFTripFuelUsed : 0|32@1+ (0.5,0) [0|2105540607.5] "l" Vector__XXX
SG_ Aftrtrtmnt1DslPFTripActvRegenTme : 32|32@1+ (1,0) [0|4211081215] "s" Vector__XXX
SG_ Aftrtrtmnt1DslPFTripDisabledTime : 64|32@1+ (1,0) [0|4211081215] "s" Vector__XXX
SG_ Aft1DslPFTrpNoOfActvRegens : 96|32@1+ (1,0) [0|4211081215] "" Vector__XXX
SG_ Aft1DslPFTrpPassiveRegenTme : 128|32@1+ (1,0) [0|4211081215] "s" Vector__XXX
SG_ Aft1DslPFTrpNoOfPassiveRegens : 160|32@1+ (1,0) [0|4211081215] "" Vector__XXX
SG_ Aft1DslPFTrpNoOfActRegenInhbtRqs : 192|32@1+ (1,0) [0|4211081215] "" Vector__XXX
SG_ Aft1DslPFTrpNoOfActvRegenManRqs : 224|32@1+ (1,0) [0|4211081215] "" Vector__XXX

BO_ 2566748926 AT2S1: 8 Vector__XXX
SG_ Aftrtrtmnt2DslPFSootLoadPercent : 0|8@1+ (1,0) [0|250] "%" Vector__XXX
SG_ Aftrtrtmnt2DslPFAshLoadPercent : 8|8@1+ (1,0) [0|250] "%" Vector__XXX
SG_ Aft2DslPFTmeSncLastActvRegen : 16|32@1+ (1,0) [0|4211081215] "s" Vector__XXX
SG_ Aft2DslPFSootLoadRegenTrshld : 48|16@1+ (0.0025,0) [0|160.6375] "%" Vector__XXX

BO_ 2566749182 AT1S1: 8 Vector__XXX
SG_ Aftrtrtmnt1DslPFSootLoadPercent : 0|8@1+ (1,0) [0|250] "%" Vector__XXX
SG_ Aftrtrtmnt1DslPFAshLoadPercent : 8|8@1+ (1,0) [0|250] "%" Vector__XXX
SG_ Aft1DslPFTmeSncLastActvRegen : 16|32@1+ (1,0) [0|4211081215] "s" Vector__XXX
SG_ Aft1DslPFSootLoadRegenTrshld : 48|16@1+ (0.0025,0) [0|160.6375] "%" Vector__XXX

BO_ 2566749438 DPFC1: 8 Vector__XXX
SG_ DieselParticulateFilterLampCmd : 0|3@1+ (1,0) [0|7] "" Vector__XXX
SG_ DslPFActvRegenAvailabilityStatus : 3|2@1+ (1,0) [0|3] "" Vector__XXX
SG_ AftrtrtmntDslPFPassiveRegenStat : 8|2@1+ (1,0) [0|3] "" Vector__XXX
SG_ AftrtrtmntDslPFActvRegenStatus : 10|2@1+ (1,0) [0|3] "" Vector__XXX
SG_ AftrtrtmntDslPFStatus : 12|3@1+ (1,0) [0|7] "" Vector__XXX
SG_ DslPFActvRegenInhbtdStatus : 16|2@1+ (1,0) [0|3] "" Vector__XXX
SG_ DslPFActvRegenInhbtdDTInhbtSw : 18|2@1+ (1,0) [0|3] "" Vector__XXX
SG_ DslPFActRegenInhbtdDTCltchDiseng : 20|2@1+ (1,0) [0|3] "" Vector__XXX
SG_ DslPFActRegenInhbtdDTSrvcBrkActv : 22|2@1+ (1,0) [0|3] "" Vector__XXX
SG_ DslPFActvRegenInhbtdDTPTOActv : 24|2@1+ (1,0) [0|3] "" Vector__XXX
SG_ DPFActRegenInhbtdDTAcclPdlOffIdl : 26|2@1+ (1,0) [0|3] "" Vector__XXX
SG_ DslPFActvRegenInhbtdDTOutOfNtrl : 28|2@1+ (1,0) [0|3] "" Vector__XXX
SG_ DPFActRegInhDTVhclSpdAbvAllwdSpd : 30|2@1+ (1,0) [0|3] "" Vector__XXX
SG_ DPFActRegenInhbtdDTPrkBrkNotSet : 32|2@1+ (1,0) [0|3] "" Vector__XXX
SG_ DPFActRegenInhbtdDTLowExhstTemp : 34|2@1+ (1,0) [0|3] "" Vector__XXX
SG_ DslPFActRegenInhbtdDTSysFaultAct : 36|2@1+ (1,0) [0|3] "" Vector__XXX
SG_ DslPFActvRegenInhbtdDTSysTimeout : 38|2@1+ (1,0) [0|3] "" Vector__XXX
SG_ DPFActRegenInhbtdDTTmprySysLckt : 40|2@1+ (1,0) [0|3] "" Vector__XXX
SG_ DPFActRegenInhbtdDTPrmntSysLckt : 42|2@1+ (1,0) [0|3] "" Vector__XXX
SG_ DPFActRegInhbtdDTEngNotWarmedUp : 44|2@1+ (1,0) [0|3] "" Vector__XXX
SG_ DPFActRegInhDTVhclSpdBlwAllwdSpd : 46|2@1+ (1,0) [0|3] "" Vector__XXX
SG_ DslPFAutoActvRegenInitConf : 48|2@1+ (1,0) [0|3] "" Vector__XXX
SG_ ExhstSystemHghTemperatureLampCmd : 50|3@1+ (1,0) [0|7] "" Vector__XXX
SG_ DslPFActvRegenForcedStatus : 53|3@1+ (1,0) [0|7] "" Vector__XXX
SG_ HydrocarbonDoserPurgingEnable : 56|2@1+ (1,0) [0|3] "" Vector__XXX
SG_ DPFActRegenInhbtdDTLowExhstPress : 58|2@1+ (1,0) [0|3] "" Vector__XXX
SG_ Aft1DPFConditionsNotMetForActReg : 60|2@1+ (1,0) [0|3] "" Vector__XXX
SG_ DslPrtcltFlActRegenInhDTThresher : 62|2@1+ (1,0) [0|3] "" Vector__XXX

BO_ 2566749694 FMS1: 0 Vector__XXX

BO_ 2566749950 AFSS: 8 Vector__XXX
SG_ LeftHeadlampDynamicBendingLight : 0|3@1+ (1,0) [0|7] "" Vector__XXX
SG_ RightHeadlampDynamicBendingLight : 3|3@1+ (1,0) [0|7] "" Vector__XXX
SG_ LeftHeadlampLightDistribution : 8|4@1+ (1,0) [0|15] "" Vector__XXX
SG_ RightHeadlampLightDistribution : 12|4@1+ (1,0) [0|15] "" Vector__XXX

BO_ 2566750206 EC2: 8 Vector__XXX
SG_ MaxCrankAttmptsPerStartAttmpt : 0|8@1+ (1,0) [0|250] "" Vector__XXX
SG_ NoOfCombustionCyclesForAveraging : 8|8@1+ (1,0) [0|250] "" Vector__XXX
SG_ EngineConfIdentification : 16|16@1+ (1,0) [0|64255] "" Vector__XXX
SG_ TrnsmIdlGvrnrFuelngInhbtSupp : 32|2@1+ (1,0) [0|3] "" Vector__XXX

BO_ 2566750462 DM28: 6 Vector__XXX
SG_ ProtectLamp : 0|2@1+ (1,0) [0|3] "" Vector__XXX
SG_ AmberWarningLamp : 2|2@1+ (1,0) [0|3] "" Vector__XXX
SG_ RedStopLamp : 4|2@1+ (1,0) [0|3] "" Vector__XXX
SG_ MalfunctionIndicatorLamp : 6|2@1+ (1,0) [0|3] "" Vector__XXX
SG_ FlashProtectLamp : 8|2@1+ (1,0) [0|3] "" Vector__XXX
SG_ FlashAmberWarningLamp : 10|2@1+ (1,0) [0|3] "" Vector__XXX
SG_ FlashRedStopLamp : 12|2@1+ (1,0) [0|3] "" Vector__XXX
SG_ FlashMalfunctionIndicatorLamp : 14|2@1+ (1,0) [0|3] "" Vector__XXX
SG_ SuspectParameterNumber : 23|19@0+ (1,0) [0|524287] "" Vector__XXX
SG_ FailureModeIdentifier : 32|5@1+ (1,0) [0|31] "" Vector__XXX
SG_ OccurrenceCount : 40|7@1+ (1,0) [0|127] "" Vector__XXX
SG_ SPNConversionMethod : 47|1@1+ (1,0) [0|1] "" Vector__XXX

BO_ 2499641854 EGRBV: 8 Vector__XXX
SG_ EGR1CoolerBypassActuatorPostion : 0|8@1+ (0.4,0) [0|100] "%" Vector__XXX

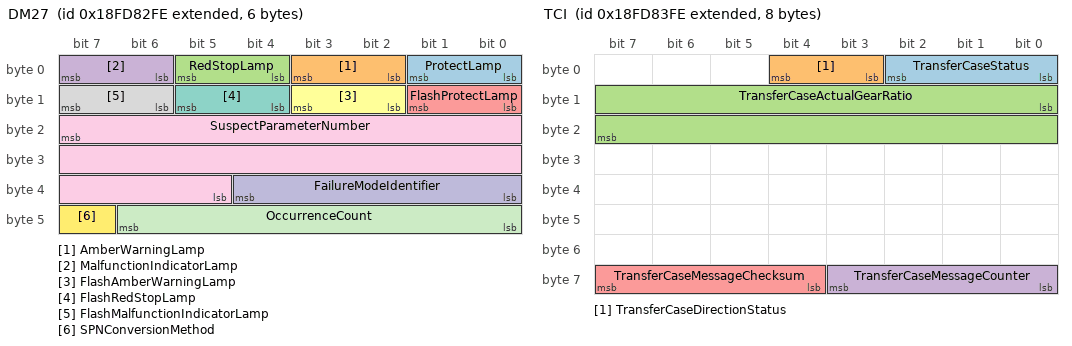
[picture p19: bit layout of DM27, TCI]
BO_ 2566750974 DM27: 6 Vector__XXX
SG_ ProtectLamp : 0|2@1+ (1,0) [0|3] "" Vector__XXX
SG_ AmberWarningLamp : 2|2@1+ (1,0) [0|3] "" Vector__XXX
SG_ RedStopLamp : 4|2@1+ (1,0) [0|3] "" Vector__XXX
SG_ MalfunctionIndicatorLamp : 6|2@1+ (1,0) [0|3] "" Vector__XXX
SG_ FlashProtectLamp : 8|2@1+ (1,0) [0|3] "" Vector__XXX
SG_ FlashAmberWarningLamp : 10|2@1+ (1,0) [0|3] "" Vector__XXX
SG_ FlashRedStopLamp : 12|2@1+ (1,0) [0|3] "" Vector__XXX
SG_ FlashMalfunctionIndicatorLamp : 14|2@1+ (1,0) [0|3] "" Vector__XXX
SG_ SuspectParameterNumber : 23|19@0+ (1,0) [0|524287] "" Vector__XXX
SG_ FailureModeIdentifier : 32|5@1+ (1,0) [0|31] "" Vector__XXX
SG_ OccurrenceCount : 40|7@1+ (1,0) [0|127] "" Vector__XXX
SG_ SPNConversionMethod : 47|1@1+ (1,0) [0|1] "" Vector__XXX

BO_ 2566751230 TCI: 8 Vector__XXX
SG_ TransferCaseStatus : 0|3@1+ (1,0) [0|7] "" Vector__XXX
SG_ TransferCaseDirectionStatus : 3|2@1+ (1,0) [0|3] "" Vector__XXX
SG_ TransferCaseActualGearRatio : 8|16@1+ (0.01,0) [0|642.55] "" Vector__XXX
SG_ TransferCaseMessageCounter : 56|4@1+ (1,0) [0|15] "" Vector__XXX
SG_ TransferCaseMessageChecksum : 60|4@1+ (1,0) [0|15] "" Vector__XXX

BO_ 2566751486 EFL_P9: 8 Vector__XXX
SG_ EngIntkValveActOilPressForCyl17 : 0|16@1+ (0.1,0) [0|6425.5] "kPa" Vector__XXX
SG_ EngIntkValveActOilPressForCyl18 : 16|16@1+ (0.1,0) [0|6425.5] "kPa" Vector__XXX
SG_ EngIntkValveActOilPressForCyl19 : 32|16@1+ (0.1,0) [0|6425.5] "kPa" Vector__XXX
SG_ EngIntkValveActOilPressForCyl20 : 48|16@1+ (0.1,0) [0|6425.5] "kPa" Vector__XXX

CM_ BO_ 2432499198 "Electronic Engine Controller 9";
CM_ BO_ 2633826046 "Electronic Engine Controller 10";
CM_ BO_ 2566717438 "Engine Temperature 5";
CM_ BO_ 2499608830 "Engine Fluid Level/Pressure 10";
CM_ BO_ 2566717950 "Low Voltage Disconnect  Status";
CM_ BO_ 2566718206 "ISO 11783-7: All Implements Stop Operations Switch State";
CM_ BO_ 2566718462 "ISO 11783-7: Implement Operating State Command";
CM_ BO_ 2566718718 "Direct Lamp Control Data 2";
CM_ BO_ 2566718974 "Direct Lamp Control Data 1";
CM_ BO_ 2566719230 "Direct Lamp Control Command 2";
CM_ BO_ 2566719486 "Direct Lamp Control Command 1";
CM_ BO_ 2633828606 "Engine oil message";
CM_ BO_ 2566719998 "High Resolution Fuel Consumption (Liquid)";
CM_ BO_ 2365393662 "Aftertreatment 2 Outlet Gas NOx Sensor correction data 2";
CM_ BO_ 2365393918 "Aftertreatment 2 Outlet Gas NOx Sensor correction data 1";
CM_ BO_ 2365394174 "Aftertreatment 2 Intake Gas NOx Sensor correction data 2";
CM_ BO_ 2365394430 "Aftertreatment 2 Intake Gas NOx Sensor correction data 1";
CM_ BO_ 2365394686 "Aftertreatment 1 Outlet Gas NOx Sensor correction data 2";
CM_ BO_ 2365394942 "Aftertreatment 1 Outlet Gas NOx Sensor correction data 1";
CM_ BO_ 2365395198 "Aftertreatment 1 Intake Gas NOx Sensor correction data 2";
CM_ BO_ 2365395454 "Aftertreatment 1 Intake Gas NOx Sensor Correction Data 1";
CM_ BO_ 2566722302 "Magnet Status Information 1";
CM_ BO_ 2566722558 "Magnet System Configuration Information";
CM_ BO_ 2566722814 "Battery Charger 2";
CM_ BO_ 2566723070 "Battery Charger 1";
CM_ BO_ 2499614462 "Occupant Classification System Information";
CM_ BO_ 2499614718 "Beltlock and Airbag Deactivation Switch Information";
CM_ BO_ 2633832702 "Collision Sensor Information";
CM_ BO_ 2633832958 "Ignitor Loop Information";
CM_ BO_ 2566724350 "Aftertreatment 1 Warm Up Diesel Oxidation Catalyst Information";
CM_ BO_ 2566724606 "Diesel Particulate Filter 2 Soot";
CM_ BO_ 2566724862 "Diesel Particulate Filter 1 Soot";
CM_ BO_ 2566725118 "Aftertreatment Differential Temperature 2";
CM_ BO_ 2566725374 "Aftertreatment Differential Temperature 1";
CM_ BO_ 2566725630 "Aftertreatment 2 Diesel Oxidation Catalyst 1";
CM_ BO_ 2566725886 "Aftertreatment 1 Diesel Oxidation Catalyst 1";
CM_ BO_ 2566726142 "Aftertreatment 2 Gas Oxidation Catalyst";
CM_ BO_ 2566726398 "Aftertreatment 1 Gas Oxidation Catalyst";
CM_ BO_ 2365400062 "Extended Joystick Message 10";
CM_ BO_ 2365400318 "Basic Joystick Message 10";
CM_ BO_ 2365400574 "Extended Joystick Message 9";
CM_ BO_ 2365400830 "Basic Joystick Message 9";
CM_ BO_ 2365401086 "Extended Joystick Message 8";
CM_ BO_ 2365401342 "Basic Joystick Message 8";
CM_ BO_ 2365401598 "Extended Joystick Message 7";
CM_ BO_ 2365401854 "Basic Joystick Message 7";
CM_ BO_ 2365402110 "Extended Joystick Message 6";
CM_ BO_ 2365402366 "Basic Joystick Message 6";
CM_ BO_ 2365402622 "Extended Joystick Message 5";
CM_ BO_ 2365402878 "Basic Joystick Message 5";
CM_ BO_ 2365403134 "Extended Joystick Message 4";
CM_ BO_ 2365403390 "Basic Joystick Message 4";
CM_ BO_ 2566730238 "Fan Drive #2";
CM_ BO_ 2566730494 "ISO 11783-12: ECU diagnostic protocol";
CM_ BO_ 2566730750 "Aftertreatment 2 Diesel Exhaust Fluid Supply Information";
CM_ BO_ 2566731006 "Aftertreatment 2 SCR Reagant Tank 2 Information";
CM_ BO_ 2566731262 "Aftertreatment 2 Diesel Exhaust Fluid Tank 1 Information 1";
CM_ BO_ 2566731518 "Aftertreatment 2 Diesel Exhaust Fluid Information 1";
CM_ BO_ 2566731774 "Aftertreatment 2 SCR Service Information 1";
CM_ BO_ 2566732030 "Aftertreatment 2 SCR Exhaust Gas Temperature 1";
CM_ BO_ 2566732286 "Aftertreatment 2 SCR Exhaust Gas Pressures";
CM_ BO_ 2566732542 "Aftertreatment 2 SCR Dosing System Requests 2";
CM_ BO_ 2566732798 "Aftertreatment 2 SCR Dosing System Information 2";
CM_ BO_ 2566733054 "Aftertreatment 1 Diesel Exhaust Fluid Supply Information";
CM_ BO_ 2566733310 "Aftertreatment 1 SCR Reagant Tank 2 Information";
CM_ BO_ 2499624702 "Aftertreatment 1 SCR Exhaust Gas Temperature 1";
CM_ BO_ 2566733822 "Aftertreatment 1 SCR Exhaust Gas Pressures";
CM_ BO_ 2566734078 "Aftertreatment 1 SCR Dosing System Requests 2";
CM_ BO_ 2566734334 "Aftertreatment 1 SCR Dosing System Information 2";
CM_ BO_ 2566734590 "ISO 11783-7: ISOBUS compliance certification";
CM_ BO_ 2566734846 "ISO 11783-7: Machine Selected Speed Command";
CM_ BO_ 2566735102 "Aftertreatment 2 Fuel Control 2";
CM_ BO_ 2566735358 "Aftertreatment 2 Three Way Catalyst";
CM_ BO_ 2566735614 "Aftertreatment 1 Three Way Catalyst";
CM_ BO_ 2633844734 "Transmission Mode Labels";
CM_ BO_ 2566736126 "Engine Exhaust Bank 2 O2 Fuel Trim";
CM_ BO_ 2566736382 "Engine Exhaust Bank 1 O2 Fuel Trim";
CM_ BO_ 2432520702 "Aftercooler Coolant Control Valve Command";
CM_ BO_ 2432520958 "Engine Coolant Control Valve Command";
CM_ BO_ 2499630078 "Engine Average Information";
CM_ BO_ 2566739198 "DTCs - C, Previously Active";
CM_ BO_ 2566739454 "DTCs - C, Confirmed and Active";
CM_ BO_ 2566739710 "DTCs - C, Pending";
CM_ BO_ 2566739966 "DTCs - B2, Previously Active";
CM_ BO_ 2566740222 "DTCs - B2, Confirmed and Active";
CM_ BO_ 2566740478 "DTCs - B2, Pending";
CM_ BO_ 2566740734 "DTCs - B1, Previously Active";
CM_ BO_ 2566740990 "DTCs - B1, Confirmed and Active";
CM_ BO_ 2566741246 "DTCs - B1, Pending";
CM_ BO_ 2566741502 "DTCs - A, Previously Active";
CM_ BO_ 2566741758 "DTCs - A, Confirmed and Active";
CM_ BO_ 2566742014 "DTCs - A, Pending";
CM_ BO_ 2566742270 "Harmonized B1 Failure Counts";
CM_ BO_ 2566742526 "Harmonized Cumulative Continuous Malfunction Indicator – System";
CM_ BO_ 2566742782 "Harmonized Global Regulation Description";
CM_ BO_ 2566743038 "Harmonized Roadworthiness – System";
CM_ BO_ 2566743294 "Harmonized Roadworthiness - Vehicle";
CM_ BO_ 2566743550 "Aftertreatment 1 Fuel Control 2";
CM_ BO_ 2566743806 "Engine Temperature 4";
CM_ BO_ 2566744062 "Zero Net Vehicle Weight Change";
CM_ BO_ 2499635454 "Gross Combination Vehicle Weight";
CM_ BO_ 2633853438 "Axle Group Calibration Weights";
CM_ BO_ 2499635966 "Axle Group Weight";
CM_ BO_ 2566745086 "Available Axle Group Weights";
CM_ BO_ 2566745342 "Aftertreatment 2 Air Control 2";
CM_ BO_ 2566745598 "Aftertreatment 1 Air Control 2";
CM_ BO_ 2566745854 "Aftertreatment 1 SCR Service Information 1";
CM_ BO_ 2566746110 "Electronic Engine Controller 8";
CM_ BO_ 2566746366 "Door ramp control";
CM_ BO_ 2566746622 "Brake actuator stroke status";
CM_ BO_ 2566746878 "Engine Spark Voltage 6";
CM_ BO_ 2566747134 "Engine Spark Voltage 5";
CM_ BO_ 2566747390 "Engine Spark Voltage 4";
CM_ BO_ 2566747646 "Engine Spark Voltage 3";
CM_ BO_ 2566747902 "Engine Spark Voltage 2";
CM_ BO_ 2566748158 "Engine Spark Voltage 1";
CM_ BO_ 2566748414 "Aftertreatment 2 Trip Information";
CM_ BO_ 2566748670 "Aftertreatment 1 Trip Information";
CM_ BO_ 2566748926 "Aftertreatment 2 Service 1";
CM_ BO_ 2566749182 "Aftertreatment 1 Service 1";
CM_ BO_ 2566749438 "Diesel Particulate Filter Control 1";
CM_ BO_ 2566749694 "Reserved for FMS Telltale status";
CM_ BO_ 2566749950 "Adaptive Front-Lighting System Status";
CM_ BO_ 2566750206 "Engine Configuration 2";
CM_ BO_ 2566750462 "Emission-Related Permanent Diagnostic Trouble Codes";
CM_ BO_ 2499641854 "EGR Cooler Bypass";
CM_ BO_ 2566750974 "All Pending DTCs";
CM_ BO_ 2566751230 "Transfer Case Information";
CM_ BO_ 2566751486 "Engine Fluid Level/Pressure 9";
BA_DEF_ BO_  "GenMsgCycleTime" INT 0 65535;
BA_DEF_ SG_  "SigType" ENUM "Default","Range","RangeSigned","ASCII","Discrete","Control","ReferencePGN","DTC","StringDelimiter","StringLength","StringLengthControl","MessageCounter","MessageChecksum";
BA_DEF_DEF_  "GenMsgCycleTime" 0;
BA_DEF_DEF_  "SigType" "Default";
BA_ "GenMsgCycleTime" BO_ 2432499198 100;
BA_ "GenMsgCycleTime" BO_ 2566717438 1000;
BA_ "GenMsgCycleTime" BO_ 2499608830 500;
BA_ "GenMsgCycleTime" BO_ 2566717950 500;
BA_ "GenMsgCycleTime" BO_ 2566718718 1000;
BA_ "GenMsgCycleTime" BO_ 2566718974 1000;
BA_ "GenMsgCycleTime" BO_ 2566719230 1000;
BA_ "GenMsgCycleTime" BO_ 2566719486 1000;
BA_ "GenMsgCycleTime" BO_ 2633828606 30000;
BA_ "GenMsgCycleTime" BO_ 2566719998 1000;
BA_ "GenMsgCycleTime" BO_ 2365393918 1000;
BA_ "GenMsgCycleTime" BO_ 2365394430 1000;
BA_ "GenMsgCycleTime" BO_ 2365394942 1000;
BA_ "GenMsgCycleTime" BO_ 2365395454 1000;
BA_ "GenMsgCycleTime" BO_ 2566722302 500;
BA_ "GenMsgCycleTime" BO_ 2566722814 1000;
BA_ "GenMsgCycleTime" BO_ 2566723070 1000;
BA_ "GenMsgCycleTime" BO_ 2499614462 5000;
BA_ "GenMsgCycleTime" BO_ 2499614718 250;
BA_ "GenMsgCycleTime" BO_ 2566724350 500;
BA_ "GenMsgCycleTime" BO_ 2566724606 1000;
BA_ "GenMsgCycleTime" BO_ 2566724862 1000;
BA_ "GenMsgCycleTime" BO_ 2566725630 500;
BA_ "GenMsgCycleTime" BO_ 2566725886 500;
BA_ "GenMsgCycleTime" BO_ 2566726142 500;
BA_ "GenMsgCycleTime" BO_ 2566726398 500;
BA_ "GenMsgCycleTime" BO_ 2365400062 100;
BA_ "GenMsgCycleTime" BO_ 2365400318 100;
BA_ "GenMsgCycleTime" BO_ 2365400574 100;
BA_ "GenMsgCycleTime" BO_ 2365400830 100;
BA_ "GenMsgCycleTime" BO_ 2365401086 100;
BA_ "GenMsgCycleTime" BO_ 2365401342 100;
BA_ "GenMsgCycleTime" BO_ 2365401598 100;
BA_ "GenMsgCycleTime" BO_ 2365401854 100;
BA_ "GenMsgCycleTime" BO_ 2365402110 100;
BA_ "GenMsgCycleTime" BO_ 2365402366 100;
BA_ "GenMsgCycleTime" BO_ 2365402622 100;
BA_ "GenMsgCycleTime" BO_ 2365402878 100;
BA_ "GenMsgCycleTime" BO_ 2365403134 100;
BA_ "GenMsgCycleTime" BO_ 2365403390 100;
BA_ "GenMsgCycleTime" BO_ 2566730238 1000;
BA_ "GenMsgCycleTime" BO_ 2566730750 1000;
BA_ "GenMsgCycleTime" BO_ 2566731006 1000;
BA_ "GenMsgCycleTime" BO_ 2566731262 1000;
BA_ "GenMsgCycleTime" BO_ 2566731518 1000;
BA_ "GenMsgCycleTime" BO_ 2566732030 500;
BA_ "GenMsgCycleTime" BO_ 2566732286 500;
BA_ "GenMsgCycleTime" BO_ 2566732542 500;
BA_ "GenMsgCycleTime" BO_ 2566732798 500;
BA_ "GenMsgCycleTime" BO_ 2566733054 1000;
BA_ "GenMsgCycleTime" BO_ 2566733310 1000;
BA_ "GenMsgCycleTime" BO_ 2499624702 500;
BA_ "GenMsgCycleTime" BO_ 2566733822 500;
BA_ "GenMsgCycleTime" BO_ 2566734078 500;
BA_ "GenMsgCycleTime" BO_ 2566734334 500;
BA_ "GenMsgCycleTime" BO_ 2566735102 500;
BA_ "GenMsgCycleTime" BO_ 2566735358 500;
BA_ "GenMsgCycleTime" BO_ 2566735614 500;
BA_ "GenMsgCycleTime" BO_ 2432520702 1000;
BA_ "GenMsgCycleTime" BO_ 2432520958 1000;
BA_ "GenMsgCycleTime" BO_ 2499630078 500;
BA_ "GenMsgCycleTime" BO_ 2566743038 10000;
BA_ "GenMsgCycleTime" BO_ 2566743550 500;
BA_ "GenMsgCycleTime" BO_ 2566743806 1000;
BA_ "GenMsgCycleTime" BO_ 2499635454 10000;
BA_ "GenMsgCycleTime" BO_ 2499635966 20;
BA_ "GenMsgCycleTime" BO_ 2566745342 500;
BA_ "GenMsgCycleTime" BO_ 2566745598 500;
BA_ "GenMsgCycleTime" BO_ 2566746366 1000;
BA_ "GenMsgCycleTime" BO_ 2566746622 1000;
BA_ "GenMsgCycleTime" BO_ 2566749438 1000;
BA_ "GenMsgCycleTime" BO_ 2499641854 500;
BA_ "GenMsgCycleTime" BO_ 2566751230 1000;
BA_ "GenMsgCycleTime" BO_ 2566751486 500;
BA_ "SigType" SG_ 2566742782 GloblTechnicalRegulationDescript 3;
VAL_ 2566717950 LowVltgDiscnnctManDiscnnctStat 0 "Input off" 1 "Input on" 2 "Error" 3 "Not installed" ;
VAL_ 2566717950 LowVoltageDiscnnctManConnectStat 0 "Input off" 1 "Input on" 2 "Error" 3 "Not installed" ;
VAL_ 2566717950 LowVltgDiscnnctCurrentOprtngMde 0 "Automatic" 1 "Reserved" 4 "Manual Disconnect via J1939 request" 5 "Manual Connect via J1939 request" 6 "Reserved" 8 "Manual Disconnect via hardwired input" 9 "Manual Connect via hardwired input" 10 "Reserved" 15 "Not available" ;
VAL_ 2566717950 LowVoltageDisconnectOutput3State 0 "Output off or disconnected" 1 "Output on or connected" 2 "Disconnect alarm expired, output off or disconnected" 3 "Disconnect pending, alarm active" 4 "Connect pending, alarm active" 5 "Reserved" 14 "Output fault" 15 "Not available or not installed" ;
VAL_ 2566717950 LowVoltageDisconnectOutput2State 0 "Output off or disconnected" 1 "Output on or connected" 2 "Disconnect alarm expired, output off or disconnected" 3 "Disconnect pending, alarm active" 4 "Connect pending, alarm active" 5 "Reserved" 14 "Output fault" 15 "Not available or not installed" ;
VAL_ 2566717950 LowVoltageDisconnectOutput1State 0 "Output off or disconnected" 1 "Output on or connected" 2 "Disconnect alarm expired, output off or disconnected" 3 "Disconnect pending, alarm active" 4 "Connect pending, alarm active" 5 "Reserved" 14 "Output fault" 15 "Not available or not installed" ;
VAL_ 2566717950 LowVoltageDiscnnctVoutOutptState 0 "Output off or disconnected" 1 "Output on or connected" 2 "Disconnect alarm expired, output off or disconnected" 3 "Disconnect pending, alarm active" 4 "Connect pending, alarm active" 5 "Reserved" 14 "Output fault" 15 "Not available or not installed" ;
VAL_ 2566718206 AllImplementStopOprtngOpsSwStat 0 "All implements stop operations switch OFF" 1 "All implements stop operations switch ON" 2 "Error indication" 3 "Not available" ;
VAL_ 2566718462 ImplementOperatingStateCommand 0 "Set implement to field working state" 1 "Set implement to transport state" 2 "Set implement to park state" 3 "Take no action" ;
VAL_ 2566718718 VehicleBatteryVoltageLowLampData 0 "Lamp deactivated (Off)" 1 "Lamp activated (On)" 2 "Error" 3 "Not available" ;
VAL_ 2566718718 VehicleFuelLevelLowLampData 0 "Lamp deactivated (Off)" 1 "Lamp activated (On)" 2 "Error" 3 "Not available" ;
VAL_ 2566718718 VehicleAirPressureLowLampData 0 "Lamp deactivated (Off)" 1 "Lamp activated (On)" 2 "Error" 3 "Not available" ;
VAL_ 2566718718 VehicleHVACRecirculationLampData 0 "Lamp deactivated (Off)" 1 "Lamp activated (On)" 2 "Error" 3 "Not available" ;
VAL_ 2566718718 VehicleBatteryChargingLampData 0 "Lamp deactivated (Off)" 1 "Lamp activated (On)" 2 "Error" 3 "Not available" ;
VAL_ 2566718718 HillHolderLampData 0 "Lamp deactivated (Off)" 1 "Lamp activated (On)" 2 "Error" 3 "Not available" ;
VAL_ 2566718718 VhclLmtedPerformanceMdeLampDat 0 "Lamp deactivated (Off)" 1 "Lamp activated (On)" 2 "Error" 3 "Not available" ;
VAL_ 2566718974 EngineProtectLampData 0 "Lamp deactivated (Off)" 1 "Lamp activated (On)" 2 "Error" 3 "Not available" ;
VAL_ 2566718974 EngineAmberWarningLampData 0 "Lamp deactivated (Off)" 1 "Lamp activated (On)" 2 "Error" 3 "Not available" ;
VAL_ 2566718974 EngineRedStopLampData 0 "Lamp deactivated (Off)" 1 "Lamp activated (On)" 2 "Error" 3 "Not available" ;
VAL_ 2566718974 OBDMalfunctionIndicatorLampData 0 "Lamp deactivated (Off)" 1 "Lamp activated (On)" 2 "Error" 3 "Not available" ;
VAL_ 2566718974 EngineBrakeActiveLampData 0 "Lamp deactivated (Off)" 1 "Lamp activated (On)" 2 "Error" 3 "Not available" ;
VAL_ 2566718974 ComPrsionBrkEnblSwIndictrLampDat 0 "Lamp deactivated (Off)" 1 "Lamp activated (On)" 2 "Error" 3 "Not available" ;
VAL_ 2566718974 EngineOilPressureLowLampData 0 "Lamp deactivated (Off)" 1 "Lamp activated (On)" 2 "Error" 3 "Not available" ;
VAL_ 2566718974 EngCoolntTemperatureHighLampDat 0 "Lamp deactivated (Off)" 1 "Lamp activated (On)" 2 "Error" 3 "Not available" ;
VAL_ 2566718974 EngineCoolantLevelLowLampData 0 "Lamp deactivated (Off)" 1 "Lamp activated (On)" 2 "Error" 3 "Not available" ;
VAL_ 2566718974 EngineIdleManagementActvLampData 0 "Lamp deactivated (Off)" 1 "Lamp activated (On)" 2 "Error" 3 "Not available" ;
VAL_ 2566718974 EngAirFilterRestrictionLampDat 0 "Lamp deactivated (Off)" 1 "Lamp activated (On)" 2 "Error" 3 "Not available" ;
VAL_ 2566718974 EngFuelFilterRestrictedLampDat 0 "Lamp deactivated (Off)" 1 "Lamp activated (On)" 2 "Error" 3 "Not available" ;
VAL_ 2566718974 EngCtrlModule1ReadyForUseLampDat 0 "Lamp deactivated (Off)" 1 "Lamp activated (On)" 2 "Error" 3 "Not available" ;
VAL_ 2566718974 EngCtrlModule2ReadyForUseLampDat 0 "Lamp deactivated (Off)" 1 "Lamp activated (On)" 2 "Error" 3 "Not available" ;
VAL_ 2566718974 EngCtrlModule3ReadyForUseLampDat 0 "Lamp deactivated (Off)" 1 "Lamp activated (On)" 2 "Error" 3 "Not available" ;
VAL_ 2566718974 EngineSpeedHighLampData 0 "Lamp deactivated (Off)" 1 "Lamp activated (On)" 2 "Error" 3 "Not available" ;
VAL_ 2566718974 EngineSpeedVeryHighLampData 0 "Lamp deactivated (Off)" 1 "Lamp activated (On)" 2 "Error" 3 "Not available" ;
VAL_ 2566718974 VehicleAccltnRateLimitLampData 0 "Lamp deactivated (Off)" 1 "Lamp activated (On)" 2 "Error" 3 "Not available" ;
VAL_ 2566718974 EngStopStartAutoStopActvLampDat 0 "Lamp deactivated (Off)" 1 "Lamp activated (On)" 2 "Error" 3 "Not available" ;
VAL_ 2566718974 EngStopStrtAutoStrtFailedLampDat 0 "Lamp deactivated (Off)" 1 "Lamp activated (On)" 2 "Error" 3 "Not available" ;
VAL_ 2566718974 EngineStopStartEnabledLampData 0 "Lamp deactivated (Off)" 1 "Lamp activated (On)" 2 "Error" 3 "Not available" ;
VAL_ 2566718974 EngineWaitToStartLampData 0 "Lamp deactived (Off)" 1 "Lamp actived (On)" 2 "Error" 3 "Not available" ;
VAL_ 2566719230 VehicleBatteryVoltageLowLampCmd 0 "Lamp Off" 1 "Lamp On" 2 "Reserved" 3 "Not available" ;
VAL_ 2566719230 VehicleFuelLevelLowLampCommand 0 "Lamp Off" 1 "Lamp On" 2 "Reserved" 3 "Not available" ;
VAL_ 2566719230 VehicleAirPressureLowLampCommand 0 "Lamp Off" 1 "Lamp On" 2 "Reserved" 3 "Not available" ;
VAL_ 2566719230 VehicleHVACRecirculationLampCmd 0 "Lamp Off" 1 "Lamp On" 2 "Reserved" 3 "Not available" ;
VAL_ 2566719230 VehicleBatteryChargingLampCmd 0 "Lamp Off" 1 "Lamp On" 2 "Reserved" 3 "Not available" ;
VAL_ 2566719230 HillHolderLampCommand 0 "Lamp Off" 1 "Lamp On" 2 "Lamp Flash (1 Hz)" 3 "Not available" ;
VAL_ 2566719230 VhclLmtedPerformanceMdeLampCmd 0 "Lamp Off" 1 "Lamp On" 2 "Reserved" 3 "Not available" ;
VAL_ 2566719486 EngineProtectLampCommand 0 "Lamp Off" 1 "Lamp On" 2 "Reserved" 3 "Not available" ;
VAL_ 2566719486 EngineAmberWarningLampCommand 0 "Lamp Off" 1 "Lamp On" 2 "Reserved" 3 "Not available" ;
VAL_ 2566719486 EngineRedStopLampCommand 0 "Lamp Off" 1 "Lamp On" 2 "Reserved" 3 "Not available" ;
VAL_ 2566719486 OBDMalfunctionIndicatorLampCmd 0 "Lamp Off" 1 "Lamp On" 2 "Reserved" 3 "Not available" ;
VAL_ 2566719486 EngineBrakeActiveLampCommand 0 "Lamp Off" 1 "Lamp On" 2 "Reserved" 3 "Not available" ;
VAL_ 2566719486 ComPrsionBrkEnblSwIndictrLampCmd 0 "Lamp Off" 1 "Lamp On" 2 "Reserved" 3 "Not available" ;
VAL_ 2566719486 EngineOilPressureLowLampCommand 0 "Lamp Off" 1 "Lamp On" 2 "Reserved" 3 "Not available" ;
VAL_ 2566719486 EngCoolntTemperatureHighLampCmd 0 "Lamp Off" 1 "Lamp On" 2 "Reserved" 3 "Not available" ;
VAL_ 2566719486 EngineCoolantLevelLowLampCommand 0 "Lamp Off" 1 "Lamp On" 2 "Reserved" 3 "Not available" ;
VAL_ 2566719486 EngineIdleManagementActvLampCmd 0 "Lamp Off" 1 "Lamp On" 2 "Reserved" 3 "Not available" ;
VAL_ 2566719486 EngAirFilterRestrictionLampCmd 0 "Lamp Off" 1 "Lamp On" 2 "Reserved" 3 "Not available" ;
VAL_ 2566719486 EngFuelFilterRestrictedLampCmd 0 "Lamp Off" 1 "Lamp On" 2 "Reserved" 3 "Not available" ;
VAL_ 2566719486 EngCtrlModule1ReadyForUseLampCmd 0 "Lamp Off" 1 "Lamp On" 2 "Reserved" 3 "Not available" ;
VAL_ 2566719486 EngCtrlModule2ReadyForUseLampCmd 0 "Lamp Off" 1 "Lamp On" 2 "Reserved" 3 "Not available" ;
VAL_ 2566719486 EngCtrlModule3ReadyForUseLampCmd 0 "Lamp Off" 1 "Lamp On" 2 "Reserved" 3 "Not available" ;
VAL_ 2566719486 EngineSpeedHighLampCommand 0 "Lamp Off" 1 "Lamp On" 2 "Reserved" 3 "Not available" ;
VAL_ 2566719486 EngineSpeedVeryHighLampCommand 0 "Lamp Off" 1 "Lamp On" 2 "Reserved" 3 "Not available" ;
VAL_ 2566719486 VehicleAccltnRateLimitLampCmd 0 "Lamp Off" 1 "Lamp On" 2 "Reserved" 3 "Not available" ;
VAL_ 2566719486 EngIdlMangmntPendingEvntLampCmd 0 "Lamp Off" 1 "Lamp On" 2 "Reserved" 3 "Not available" ;
VAL_ 2566719486 EngStopStartAutoStopActvLampCmd 0 "Lamp Off" 1 "Lamp On" 2 "Reserved" 3 "Not available" ;
VAL_ 2566719486 EngStopStrtAutoStrtFailedLampCmd 0 "Lamp Off" 1 "Lamp On" 2 "Reserved" 3 "Not available" ;
VAL_ 2566719486 EngineStopStartEnabledLampCmd 0 "Lamp Off" 1 "Lamp On" 2 "Reserved" 3 "Not available" ;
VAL_ 2566722302 GeneratorOverheatStatus 0 "Not Overheat" 1 "Overheat" 2 "Error" 3 "Not Available" ;
VAL_ 2566722302 GensetSystemOutptVoltageRngStat 0 "Out of Range" 1 "In Range" 2 "Error" 3 "Not Available" ;
VAL_ 2566722302 GrappleMagnetSelectionSwitch 0 "Grapple Selected" 1 "Magnet Selected" 2 "Error" 3 "Not Available" ;
VAL_ 2566722302 GensetSoftstartActiveStatus 0 "Off" 1 "On" 2 "Error" 3 "Not available" ;
VAL_ 2566722302 ReverseCurrentRangeSetting 0 "1" 1 "2" 2 "3" 3 "4" 4 "5" 5 "6" 6 "7" 7 "8" 8 "9" 9 "10" 10 "11" 11 "12" 12 "13" 13 "14" 14 "15" 15 "16" 16 "Not used" 30 "Error" 31 "Not Available" ;
VAL_ 2566722302 GensetEnableActiveStatus 0 "Not Enabled" 1 "Enabled" 2 "Error" 3 "Not Avaialble" ;
VAL_ 2566722302 VoltageMonitorActiveStatus 0 "Monitor is Off" 1 "Monitor is On" 2 "Error" 3 "Not Available" ;
VAL_ 2566722302 GeneratorDutyCycleExceededStatus 0 "Duty Cycle Not Exceed" 1 "Duty Cycle Exceed" 2 "Error" 3 "Not Avaiable" ;
VAL_ 2566722814 BatteryCharger2State 0 "Idling" 1 "Charging the battery." 2 "Stand-by or maintaining the battery charge." 3 "Reserved" 13 "Battery failure" 14 "Charger failure" 15 "Not available." ;
VAL_ 2566722814 BatteryCharger2PowerLineState 0 "Disconnected" 1 "Connected" 2 "Error" 3 "Not available" ;
VAL_ 2566723070 BatteryCharger1State 0 "Idling" 1 "Charging the battery." 2 "Stand-by or maintaining the battery charge." 3 "Reserved" 13 "Battery failure" 14 "Charger failure" 15 "Not available." ;
VAL_ 2566723070 BatteryCharger1PowerLineState 0 "Disconnected" 1 "Connected" 2 "Error" 3 "Not available" ;
VAL_ 2499614462 DrvrOccupantClssfctnSystemStatus 0 "empty" 1 "child" 2 "small adult" 3 "adult" 4 "large adult" 5 "reserved" 6 "Error" 7 "not available" ;
VAL_ 2499614462 PassngOccupntClssfctnSystemStat 0 "empty" 1 "child" 2 "small adult" 3 "adult" 4 "large adult" 5 "Error" 6 "reserved" 7 "not available" ;
VAL_ 2499614462 OccupantClssfctnSystem3Status 0 "empty" 1 "occupied" 2 "Error" 3 "not available" ;
VAL_ 2499614462 OccupantClssfctnSystem4Status 0 "empty" 1 "occupied" 2 "Error" 3 "not available" ;
VAL_ 2499614462 OccupantClssfctnSystem5Status 0 "empty" 1 "occupied" 2 "Error" 3 "not available" ;
VAL_ 2499614462 OccupantClssfctnSystem6Status 0 "empty" 1 "occupied" 2 "Error" 3 "not available" ;
VAL_ 2499614462 OccupantClssfctnSystem7Status 0 "empty" 1 "occupied" 2 "Error" 3 "not available" ;
VAL_ 2499614462 OccupantClssfctnSystem8Status 0 "empty" 1 "occupied" 2 "Error" 3 "not available" ;
VAL_ 2499614462 OccupantClssfctnSystem9Status 0 "empty" 1 "occupied" 2 "Error" 3 "not available" ;
VAL_ 2499614462 OccupantClssfctnSystem10Status 0 "empty" 1 "occupied" 2 "Error" 3 "not available" ;
VAL_ 2499614718 DriverBeltlockStatus 0 "Unlocked" 1 "Locked" 2 "Error" 3 "Not available" ;
VAL_ 2499614718 PassengerBeltlockStatus 0 "Unlocked" 1 "Locked" 2 "Error" 3 "Not available" ;
VAL_ 2499614718 Beltlock3Status 0 "Unlocked" 1 "Locked" 2 "Error" 3 "Not available" ;
VAL_ 2499614718 Beltlock4Status 0 "Unlocked" 1 "Locked" 2 "Error" 3 "Not available" ;
VAL_ 2499614718 Beltlock5Status 0 "Unlocked" 1 "Locked" 2 "Error" 3 "Not available" ;
VAL_ 2499614718 Beltlock6Status 0 "Unlocked" 1 "Locked" 2 "Error" 3 "Not available" ;
VAL_ 2499614718 Beltlock7Status 0 "Unlocked" 1 "Locked" 2 "Error" 3 "Not available" ;
VAL_ 2499614718 Beltlock8Status 0 "Unlocked" 1 "Locked" 2 "Error" 3 "Not available" ;
VAL_ 2499614718 Beltlock9Status 0 "Unlocked" 1 "Locked" 2 "Error" 3 "Not available" ;
VAL_ 2499614718 Beltlock10Status 0 "Unlocked" 1 "Locked" 2 "Error" 3 "Not available" ;
VAL_ 2499614718 PassngAirbgDeActvtnSwitchStatus 0 "passenger airbag activated" 1 "passenger airbag deactivated" 2 "Error" 3 "not available" ;
VAL_ 2633832702 FrontalCollisionSensor1Type 0 "acceleration sensor" 1 "pressure sensor" 2 "rollrate sensor" 3 "sonic sensor" 4 "fiber-optic sensor" 5 "radar sensor" 6 "lidar sensor" 7 "optical sensor" 8 "Reserved" 14 "Error" 15 "not available" ;
VAL_ 2633832702 FrontalCollisionSensor2Type 0 "acceleration sensor" 1 "pressure sensor" 2 "rollrate sensor" 3 "sonic sensor" 4 "fiber-optic sensor" 5 "radar sensor" 6 "lidar sensor" 7 "optical sensor" 8 "Reserved" 14 "Error" 15 "not available" ;
VAL_ 2633832702 FrontalCollisionSensor3Type 0 "acceleration sensor" 1 "pressure sensor" 2 "rollrate sensor" 3 "sonic sensor" 4 "fiber-optic sensor" 5 "radar sensor" 6 "lidar sensor" 7 "optical sensor" 8 "Reserved" 14 "Error" 15 "not available" ;
VAL_ 2633832702 FrontalCollisionSensor4Type 0 "acceleration sensor" 1 "pressure sensor" 2 "rollrate sensor" 3 "sonic sensor" 4 "fiber-optic sensor" 5 "radar sensor" 6 "lidar sensor" 7 "optical sensor" 8 "Reserved" 14 "Error" 15 "not available" ;
VAL_ 2633832702 SideCollisionSensorFrontLeftType 0 "acceleration sensor" 1 "pressure sensor" 2 "rollrate sensor" 3 "sonic sensor" 4 "fiber-optic sensor" 5 "radar sensor" 6 "lidar sensor" 7 "optical sensor" 8 "Reserved" 14 "Error" 15 "not available" ;
VAL_ 2633832702 SideCollsnSensorMidFrontLeftType 0 "acceleration sensor" 1 "pressure sensor" 2 "rollrate sensor" 3 "sonic sensor" 4 "fiber-optic sensor" 5 "radar sensor" 6 "lidar sensor" 7 "optical sensor" 8 "Reserved" 14 "Error" 15 "not available" ;
VAL_ 2633832702 SideCollsnSensorMidRearLeftType 0 "acceleration sensor" 1 "pressure sensor" 2 "rollrate sensor" 3 "sonic sensor" 4 "fiber-optic sensor" 5 "radar sensor" 6 "lidar sensor" 7 "optical sensor" 8 "Reserved" 14 "Error" 15 "not available" ;
VAL_ 2633832702 SideCollisionSensorRearLeftType 0 "acceleration sensor" 1 "pressure sensor" 2 "rollrate sensor" 3 "sonic sensor" 4 "fiber-optic sensor" 5 "radar sensor" 6 "lidar sensor" 7 "optical sensor" 8 "Reserved" 14 "Error" 15 "not available" ;
VAL_ 2633832702 SideCollsnSensorFrontRightType 0 "acceleration sensor" 1 "pressure sensor" 2 "rollrate sensor" 3 "sonic sensor" 4 "fiber-optic sensor" 5 "radar sensor" 6 "lidar sensor" 7 "optical sensor" 8 "Reserved" 14 "Error" 15 "not available" ;
VAL_ 2633832702 SideCollsnSensorMidFrntRightType 0 "acceleration sensor" 1 "pressure sensor" 2 "rollrate sensor" 3 "sonic sensor" 4 "fiber-optic sensor" 5 "radar sensor" 6 "lidar sensor" 7 "optical sensor" 8 "Reserved" 14 "Error" 15 "not available" ;
VAL_ 2633832702 SideCollsnSensorMidRearRightType 0 "acceleration sensor" 1 "pressure sensor" 2 "rollrate sensor" 3 "sonic sensor" 4 "fiber-optic sensor" 5 "radar sensor" 6 "lidar sensor" 7 "optical sensor" 8 "Reserved" 14 "Error" 15 "not available" ;
VAL_ 2633832702 SideCollisionSensorRearRightType 0 "acceleration sensor" 1 "pressure sensor" 2 "rollrate sensor" 3 "sonic sensor" 4 "fiber-optic sensor" 5 "radar sensor" 6 "lidar sensor" 7 "optical sensor" 8 "Reserved" 14 "Error" 15 "not available" ;
VAL_ 2633832702 RearCollisionSensor1Type 0 "acceleration sensor" 1 "pressure sensor" 2 "rollrate sensor" 3 "sonic sensor" 4 "fiber-optic sensor" 5 "radar sensor" 6 "lidar sensor" 7 "optical sensor" 8 "Reserved" 14 "Error" 15 "not available" ;
VAL_ 2633832702 RearCollisionSensor2Type 0 "acceleration sensor" 1 "pressure sensor" 2 "rollrate sensor" 3 "sonic sensor" 4 "fiber-optic sensor" 5 "radar sensor" 6 "lidar sensor" 7 "optical sensor" 8 "Reserved" 14 "Error" 15 "not available" ;
VAL_ 2633832702 RearCollisionSensor3Type 0 "acceleration sensor" 1 "pressure sensor" 2 "rollrate sensor" 3 "sonic sensor" 4 "fiber-optic sensor" 5 "radar sensor" 6 "lidar sensor" 7 "optical sensor" 8 "Reserved" 14 "Error" 15 "not available" ;
VAL_ 2633832702 RearCollisionSensor4Type 0 "acceleration sensor" 1 "pressure sensor" 2 "rollrate sensor" 3 "sonic sensor" 4 "fiber-optic sensor" 5 "radar sensor" 6 "lidar sensor" 7 "optical sensor" 8 "Reserved" 14 "Error" 15 "not available" ;
VAL_ 2633832702 RolloverSensorType 0 "acceleration sensor" 1 "pressure sensor" 2 "rollrate sensor" 3 "sonic sensor" 4 "fiber-optic sensor" 5 "radar sensor" 6 "lidar sensor" 7 "optical sensor" 8 "Reserved" 14 "Error" 15 "not available" ;
VAL_ 2365400062 Jystck10GrpXAxsNtrlPosStatus 0 "Not in Neutral Position" 1 "In Neutral Position" 2 "Error Indicator" 3 "Not Available" ;
VAL_ 2365400062 Jystck10GrpXAxsLvrLftNegPosStat 0 "Not on negative side of Neutral" 1 "On negative side of Neutral" 2 "Error Indicator" 3 "Not Available" ;
VAL_ 2365400062 Jystck10GrpXAxsLvrRghtPstvPsStat 0 "Not on Positive side of Neutral" 1 "On positive side of Neutral" 2 "Error Indicator" 3 "Not Available" ;
VAL_ 2365400062 Jystck10GrpYAxsNtrlPosStatus 0 "Not in Neutral Position" 1 "In Neutral Position" 2 "Error Indicator" 3 "Not Available" ;
VAL_ 2365400062 Jystck10GrpYAxsLvrBackNegPosStat 0 "Not on negative side of Neutral" 1 "On negative side of Neutral" 2 "Error Indicator" 3 "Not Available" ;
VAL_ 2365400062 Jystck10GrpYAxsLvrFrwdPstvPsStat 0 "Not on Positive side of Neutral" 1 "On positive side of Neutral" 2 "Error Indicator" 3 "Not Available" ;
VAL_ 2365400062 Jystck10ThetaAxsNtrlPosStatus 0 "Not in Neutral Position" 1 "In Neutral Position" 2 "Error Indicator" 3 "Not Available" ;
VAL_ 2365400062 Jystck10ThtAxsCntrClckwsNgPsStat 0 "Not on negative side of Neutral" 1 "On negative side of Neutral" 2 "Error Indicator" 3 "Not Available" ;
VAL_ 2365400062 Jystck10ThtAxsClckwsPstvPosStat 0 "Not on Positive side of Neutral" 1 "On positive side of Neutral" 2 "Error Indicator" 3 "Not Available" ;
VAL_ 2365400062 Jystck10ThetaAxsDetentPosStatus 0 "Not in the Detent Position" 1 "In the Detent Position" 2 "Error Indicator" 3 "Not Available" ;
VAL_ 2365400062 Jystck10GrpYAxsDetentPosStatus 0 "Not in the Detent Position" 1 "In the Detent Position" 2 "Error Indicator" 3 "Not Available" ;
VAL_ 2365400062 Jystck10GrpXAxsDetentPosStatus 0 "Not in the Detent Position" 1 "In the Detent Position" 2 "Error Indicator" 3 "Not Available" ;
VAL_ 2365400062 Joystick10Button16PressedStatus 0 "Button not pressed" 1 "Button pressed" 2 "Error Indicator" 3 "Not Available" ;
VAL_ 2365400062 Joystick10Button15PressedStatus 0 "Button not pressed" 1 "Button pressed" 2 "Error Indicator" 3 "Not Available" ;
VAL_ 2365400062 Joystick10Button14PressedStatus 0 "Button not pressed" 1 "Button pressed" 2 "Error Indicator" 3 "Not Available" ;
VAL_ 2365400062 Joystick10Button13PressedStatus 0 "Button not pressed" 1 "Button pressed" 2 "Error Indicator" 3 "Not Available" ;
VAL_ 2365400318 Jystck10XAxsNtrlPositionStatus 0 "Not in Neutral Position" 1 "In Neutral Position" 2 "Error Indicator" 3 "Not Available" ;
VAL_ 2365400318 Jystck10XAxsLvrLftNegPosStatus 0 "Not on negative side of Neutral" 1 "On negative side of Neutral" 2 "Error Indicator" 3 "Not Available" ;
VAL_ 2365400318 Jystck10XAxsLvrRghtPstvPosStatus 0 "Not on Positive side of Neutral" 1 "On positive side of Neutral" 2 "Error Indicator" 3 "Not Available" ;
VAL_ 2365400318 Jystck10YAxsNtrlPositionStatus 0 "Not in Neutral Position" 1 "In Neutral Position" 2 "Error Indicator" 3 "Not Available" ;
VAL_ 2365400318 Jystck10YAxsLvrBackNegPosStatus 0 "Not on negative side of Neutral" 1 "On negative side of Neutral" 2 "Error Indicator" 3 "Not Available" ;
VAL_ 2365400318 Jystck10YAxsLvrFrwdPstvPosStatus 0 "Not on Positive side of Neutral" 1 "On positive side of Neutral" 2 "Error Indicator" 3 "Not Available" ;
VAL_ 2365400318 Jystck10YAxsDetentPositionStatus 0 "Not in the Detent Position" 1 "In the Detent Position" 2 "Error Indicator" 3 "Not Available" ;
VAL_ 2365400318 Jystck10XAxsDetentPositionStatus 0 "Not in the Detent Position" 1 "In the Detent Position" 2 "Error Indicator" 3 "Not Available" ;
VAL_ 2365400318 Joystick10Button4PressedStatus 0 "Button not pressed" 1 "Button pressed" 2 "Error Indicator" 3 "Not Available" ;
VAL_ 2365400318 Joystick10Button3PressedStatus 0 "Button not pressed" 1 "Button pressed" 2 "Error Indicator" 3 "Not Available" ;
VAL_ 2365400318 Joystick10Button2PressedStatus 0 "Button not pressed" 1 "Button pressed" 2 "Error Indicator" 3 "Not Available" ;
VAL_ 2365400318 Joystick10Button1PressedStatus 0 "Button not pressed" 1 "Button pressed" 2 "Error Indicator" 3 "Not Available" ;
VAL_ 2365400318 Joystick10Button8PressedStatus 0 "Button not pressed" 1 "Button pressed" 2 "Error Indicator" 3 "Not Available" ;
VAL_ 2365400318 Joystick10Button7PressedStatus 0 "Button not pressed" 1 "Button pressed" 2 "Error Indicator" 3 "Not Available" ;
VAL_ 2365400318 Joystick10Button6PressedStatus 0 "Button not pressed" 1 "Button pressed" 2 "Error Indicator" 3 "Not Available" ;
VAL_ 2365400318 Joystick10Button5PressedStatus 0 "Button not pressed" 1 "Button pressed" 2 "Error Indicator" 3 "Not Available" ;
VAL_ 2365400318 Joystick10Button12PressedStatus 0 "Button not pressed" 1 "Button pressed" 2 "Error Indicator" 3 "Not Available" ;
VAL_ 2365400318 Joystick10Button11PressedStatus 0 "Button not pressed" 1 "Button pressed" 2 "Error Indicator" 3 "Not Available" ;
VAL_ 2365400318 Joystick10Button10PressedStatus 0 "Button not pressed" 1 "Button pressed" 2 "Error Indicator" 3 "Not Available" ;
VAL_ 2365400318 Joystick10Button9PressedStatus 0 "Button not pressed" 1 "Button pressed" 2 "Error Indicator" 3 "Not Available" ;
VAL_ 2365400574 Jystck9GrpXAxsNtrlPositionStatus 0 "Not in Neutral Position" 1 "In Neutral Position" 2 "Error Indicator" 3 "Not Available" ;
VAL_ 2365400574 Jystck9GrpXAxsLvrLftNegPosStatus 0 "Not on negative side of Neutral" 1 "On negative side of Neutral" 2 "Error Indicator" 3 "Not Available" ;
VAL_ 2365400574 Jystck9GrpXAxsLvrRghtPstvPosStat 0 "Not on Positive side of Neutral" 1 "On positive side of Neutral" 2 "Error Indicator" 3 "Not Available" ;
VAL_ 2365400574 Jystck9GrpYAxsNtrlPositionStatus 0 "Not in Neutral Position" 1 "In Neutral Position" 2 "Error Indicator" 3 "Not Available" ;
VAL_ 2365400574 Jystck9GrpYAxsLvrBackNegPosStat 0 "Not on negative side of Neutral" 1 "On negative side of Neutral" 2 "Error Indicator" 3 "Not Available" ;
VAL_ 2365400574 Jystck9GrpYAxsLvrFrwdPstvPosStat 0 "Not on Positive side of Neutral" 1 "On positive side of Neutral" 2 "Error Indicator" 3 "Not Available" ;
VAL_ 2365400574 Jystck9ThetaAxsNtrlPosStatus 0 "Not in Neutral Position" 1 "In Neutral Position" 2 "Error Indicator" 3 "Not Available" ;
VAL_ 2365400574 Jystck9ThtAxsCntrClckwsNegPsStat 0 "Not on negative side of Neutral" 1 "On negative side of Neutral" 2 "Error Indicator" 3 "Not Available" ;
VAL_ 2365400574 Jystck9ThetaAxsClckwsPstvPosStat 0 "Not on Positive side of Neutral" 1 "On positive side of Neutral" 2 "Error Indicator" 3 "Not Available" ;
VAL_ 2365400574 Jystck9ThetaAxsDetentPosStatus 0 "Not in the Detent Position" 1 "In the Detent Position" 2 "Error Indicator" 3 "Not Available" ;
VAL_ 2365400574 Jystck9GrpYAxsDetentPosStatus 0 "Not in the Detent Position" 1 "In the Detent Position" 2 "Error Indicator" 3 "Not Available" ;
VAL_ 2365400574 Jystck9GrpXAxsDetentPosStatus 0 "Not in the Detent Position" 1 "In the Detent Position" 2 "Error Indicator" 3 "Not Available" ;
VAL_ 2365400574 Joystick9Button16PressedStatus 0 "Button not pressed" 1 "Button pressed" 2 "Error Indicator" 3 "Not Available" ;
VAL_ 2365400574 Joystick9Button15PressedStatus 0 "Button not pressed" 1 "Button pressed" 2 "Error Indicator" 3 "Not Available" ;
VAL_ 2365400574 Joystick9Button14PressedStatus 0 "Button not pressed" 1 "Button pressed" 2 "Error Indicator" 3 "Not Available" ;
VAL_ 2365400574 Joystick9Button13PressedStatus 0 "Button not pressed" 1 "Button pressed" 2 "Error Indicator" 3 "Not Available" ;
VAL_ 2365400830 Jystck9XAxsNeutralPositionStatus 0 "Not in Neutral Position" 1 "In Neutral Position" 2 "Error Indicator" 3 "Not Available" ;
VAL_ 2365400830 Jystck9XAxsLvrLftNegPosStatus 0 "Not on negative side of Neutral" 1 "On negative side of Neutral" 2 "Error Indicator" 3 "Not Available" ;
VAL_ 2365400830 Jystck9XAxsLvrRightPstvPosStatus 0 "Not on Positive side of Neutral" 1 "On positive side of Neutral" 2 "Error Indicator" 3 "Not Available" ;
VAL_ 2365400830 Jystck9YAxsNeutralPositionStatus 0 "Not in Neutral Position" 1 "In Neutral Position" 2 "Error Indicator" 3 "Not Available" ;
VAL_ 2365400830 Jystck9YAxsLvrBackNegPosStatus 0 "Not on negative side of Neutral" 1 "On negative side of Neutral" 2 "Error Indicator" 3 "Not Available" ;
VAL_ 2365400830 Jystck9YAxsLvrFrwdPstvPosStatus 0 "Not on Positive side of Neutral" 1 "On positive side of Neutral" 2 "Error Indicator" 3 "Not Available" ;
VAL_ 2365400830 Jystck9YAxsDetentPositionStatus 0 "Not in the Detent Position" 1 "In the Detent Position" 2 "Error Indicator" 3 "Not Available" ;
VAL_ 2365400830 Jystck9XAxsDetentPositionStatus 0 "Not in the Detent Position" 1 "In the Detent Position" 2 "Error Indicator" 3 "Not Available" ;
VAL_ 2365400830 Joystick9Button4PressedStatus 0 "Button not pressed" 1 "Button pressed" 2 "Error Indicator" 3 "Not Available" ;
VAL_ 2365400830 Joystick9Button3PressedStatus 0 "Button not pressed" 1 "Button pressed" 2 "Error Indicator" 3 "Not Available" ;
VAL_ 2365400830 Joystick9Button2PressedStatus 0 "Button not pressed" 1 "Button pressed" 2 "Error Indicator" 3 "Not Available" ;
VAL_ 2365400830 Joystick9Button1PressedStatus 0 "Button not pressed" 1 "Button pressed" 2 "Error Indicator" 3 "Not Available" ;
VAL_ 2365400830 Joystick9Button8PressedStatus 0 "Button not pressed" 1 "Button pressed" 2 "Error Indicator" 3 "Not Available" ;
VAL_ 2365400830 Joystick9Button7PressedStatus 0 "Button not pressed" 1 "Button pressed" 2 "Error Indicator" 3 "Not Available" ;
VAL_ 2365400830 Joystick9Button6PressedStatus 0 "Button not pressed" 1 "Button pressed" 2 "Error Indicator" 3 "Not Available" ;
VAL_ 2365400830 Joystick9Button5PressedStatus 0 "Button not pressed" 1 "Button pressed" 2 "Error Indicator" 3 "Not Available" ;
VAL_ 2365400830 Joystick9Button12PressedStatus 0 "Button not pressed" 1 "Button pressed" 2 "Error Indicator" 3 "Not Available" ;
VAL_ 2365400830 Joystick9Button11PressedStatus 0 "Button not pressed" 1 "Button pressed" 2 "Error Indicator" 3 "Not Available" ;
VAL_ 2365400830 Joystick9Button10PressedStatus 0 "Button not pressed" 1 "Button pressed" 2 "Error Indicator" 3 "Not Available" ;
VAL_ 2365400830 Joystick9Button9PressedStatus 0 "Button not pressed" 1 "Button pressed" 2 "Error Indicator" 3 "Not Available" ;
VAL_ 2365401086 Jystck8GrpXAxsNtrlPositionStatus 0 "Not in Neutral Position" 1 "In Neutral Position" 2 "Error Indicator" 3 "Not Available" ;
VAL_ 2365401086 Jystck8GrpXAxsLvrLftNegPosStatus 0 "Not on negative side of Neutral" 1 "On negative side of Neutral" 2 "Error Indicator" 3 "Not Available" ;
VAL_ 2365401086 Jystck8GrpXAxsLvrRghtPstvPosStat 0 "Not on Positive side of Neutral" 1 "On positive side of Neutral" 2 "Error Indicator" 3 "Not Available" ;
VAL_ 2365401086 Jystck8GrpYAxsNtrlPositionStatus 0 "Not in Neutral Position" 1 "In Neutral Position" 2 "Error Indicator" 3 "Not Available" ;
VAL_ 2365401086 Jystck8GrpYAxsLvrBackNegPosStat 0 "Not on negative side of Neutral" 1 "On negative side of Neutral" 2 "Error Indicator" 3 "Not Available" ;
VAL_ 2365401086 Jystck8GrpYAxsLvrFrwdPstvPosStat 0 "Not on Positive side of Neutral" 1 "On positive side of Neutral" 2 "Error Indicator" 3 "Not Available" ;
VAL_ 2365401086 Jystck8ThetaAxsNtrlPosStatus 0 "Not in Neutral Position" 1 "In Neutral Position" 2 "Error Indicator" 3 "Not Available" ;
VAL_ 2365401086 Jystck8ThtAxsCntrClckwsNegPsStat 0 "Not on negative side of Neutral" 1 "On negative side of Neutral" 2 "Error Indicator" 3 "Not Available" ;
VAL_ 2365401086 Jystck8ThetaAxsClckwsPstvPosStat 0 "Not on Positive side of Neutral" 1 "On positive side of Neutral" 2 "Error Indicator" 3 "Not Available" ;
VAL_ 2365401086 Jystck8ThetaAxsDetentPosStatus 0 "Not in the Detent Position" 1 "In the Detent Position" 2 "Error Indicator" 3 "Not Available" ;
VAL_ 2365401086 Jystck8GrpYAxsDetentPosStatus 0 "Not in the Detent Position" 1 "In the Detent Position" 2 "Error Indicator" 3 "Not Available" ;
VAL_ 2365401086 Jystck8GrpXAxsDetentPosStatus 0 "Not in the Detent Position" 1 "In the Detent Position" 2 "Error Indicator" 3 "Not Available" ;
VAL_ 2365401086 Joystick8Button16PressedStatus 0 "Button not pressed" 1 "Button pressed" 2 "Error Indicator" 3 "Not Available" ;
VAL_ 2365401086 Joystick8Button15PressedStatus 0 "Button not pressed" 1 "Button pressed" 2 "Error Indicator" 3 "Not Available" ;
VAL_ 2365401086 Joystick8Button14PressedStatus 0 "Button not pressed" 1 "Button pressed" 2 "Error Indicator" 3 "Not Available" ;
VAL_ 2365401086 Joystick8Button13PressedStatus 0 "Button not pressed" 1 "Button pressed" 2 "Error Indicator" 3 "Not Available" ;
VAL_ 2365401342 Jystck8XAxsNeutralPositionStatus 0 "Not in Neutral Position" 1 "In Neutral Position" 2 "Error Indicator" 3 "Not Available" ;
VAL_ 2365401342 Jystck8XAxsLvrLftNegPosStatus 0 "Not on negative side of Neutral" 1 "On negative side of Neutral" 2 "Error Indicator" 3 "Not Available" ;
VAL_ 2365401342 Jystck8XAxsLvrRightPstvPosStatus 0 "Not on Positive side of Neutral" 1 "On positive side of Neutral" 2 "Error Indicator" 3 "Not Available" ;
VAL_ 2365401342 Jystck8YAxsNeutralPositionStatus 0 "Not in Neutral Position" 1 "In Neutral Position" 2 "Error Indicator" 3 "Not Available" ;
VAL_ 2365401342 Jystck8YAxsLvrBackNegPosStatus 0 "Not on negative side of Neutral" 1 "On negative side of Neutral" 2 "Error Indicator" 3 "Not Available" ;
VAL_ 2365401342 Jystck8YAxsLvrFrwdPstvPosStatus 0 "Not on Positive side of Neutral" 1 "On positive side of Neutral" 2 "Error Indicator" 3 "Not Available" ;
VAL_ 2365401342 Jystck8YAxsDetentPositionStatus 0 "Not in the Detent Position" 1 "In the Detent Position" 2 "Error Indicator" 3 "Not Available" ;
VAL_ 2365401342 Jystck8XAxsDetentPositionStatus 0 "Not in the Detent Position" 1 "In the Detent Position" 2 "Error Indicator" 3 "Not Available" ;
VAL_ 2365401342 Joystick8Button4PressedStatus 0 "Button not pressed" 1 "Button pressed" 2 "Error Indicator" 3 "Not Available" ;
VAL_ 2365401342 Joystick8Button3PressedStatus 0 "Button not pressed" 1 "Button pressed" 2 "Error Indicator" 3 "Not Available" ;
VAL_ 2365401342 Joystick8Button2PressedStatus 0 "Button not pressed" 1 "Button pressed" 2 "Error Indicator" 3 "Not Available" ;
VAL_ 2365401342 Joystick8Button1PressedStatus 0 "Button not pressed" 1 "Button pressed" 2 "Error Indicator" 3 "Not Available" ;
VAL_ 2365401342 Joystick8Button8PressedStatus 0 "Button not pressed" 1 "Button pressed" 2 "Error Indicator" 3 "Not Available" ;
VAL_ 2365401342 Joystick8Button7PressedStatus 0 "Button not pressed" 1 "Button pressed" 2 "Error Indicator" 3 "Not Available" ;
VAL_ 2365401342 Joystick8Button6PressedStatus 0 "Button not pressed" 1 "Button pressed" 2 "Error Indicator" 3 "Not Available" ;
VAL_ 2365401342 Joystick8Button5PressedStatus 0 "Button not pressed" 1 "Button pressed" 2 "Error Indicator" 3 "Not Available" ;
VAL_ 2365401342 Joystick8Button12PressedStatus 0 "Button not pressed" 1 "Button pressed" 2 "Error Indicator" 3 "Not Available" ;
VAL_ 2365401342 Joystick8Button11PressedStatus 0 "Button not pressed" 1 "Button pressed" 2 "Error Indicator" 3 "Not Available" ;
VAL_ 2365401342 Joystick8Button10PressedStatus 0 "Button not pressed" 1 "Button pressed" 2 "Error Indicator" 3 "Not Available" ;
VAL_ 2365401342 Joystick8Button9PressedStatus 0 "Button not pressed" 1 "Button pressed" 2 "Error Indicator" 3 "Not Available" ;
VAL_ 2365401598 Jystck7GrpXAxsNtrlPositionStatus 0 "Not in Neutral Position" 1 "In Neutral Position" 2 "Error Indicator" 3 "Not Available" ;
VAL_ 2365401598 Jystck7GrpXAxsLvrLftNegPosStatus 0 "Not on negative side of Neutral" 1 "On negative side of Neutral" 2 "Error Indicator" 3 "Not Available" ;
VAL_ 2365401598 Jystck7GrpXAxsLvrRghtPstvPosStat 0 "Not on Positive side of Neutral" 1 "On positive side of Neutral" 2 "Error Indicator" 3 "Not Available" ;
VAL_ 2365401598 Jystck7GrpYAxsNtrlPositionStatus 0 "Not in Neutral Position" 1 "In Neutral Position" 2 "Error Indicator" 3 "Not Available" ;
VAL_ 2365401598 Jystck7GrpYAxsLvrBackNegPosStat 0 "Not on negative side of Neutral" 1 "On negative side of Neutral" 2 "Error Indicator" 3 "Not Available" ;
VAL_ 2365401598 Jystck7GrpYAxsLvrFrwdPstvPosStat 0 "Not on Positive side of Neutral" 1 "On positive side of Neutral" 2 "Error Indicator" 3 "Not Available" ;
VAL_ 2365401598 Jystck7ThetaAxsNtrlPosStatus 0 "Not in Neutral Position" 1 "In Neutral Position" 2 "Error Indicator" 3 "Not Available" ;
VAL_ 2365401598 Jystck7ThtAxsCntrClckwsNegPsStat 0 "Not on negative side of Neutral" 1 "On negative side of Neutral" 2 "Error Indicator" 3 "Not Available" ;
VAL_ 2365401598 Jystck7ThetaAxsClckwsPstvPosStat 0 "Not on Positive side of Neutral" 1 "On positive side of Neutral" 2 "Error Indicator" 3 "Not Available" ;
VAL_ 2365401598 Jystck7ThetaAxsDetentPosStatus 0 "Not in the Detent Position" 1 "In the Detent Position" 2 "Error Indicator" 3 "Not Available" ;
VAL_ 2365401598 Jystck7GrpYAxsDetentPosStatus 0 "Not in the Detent Position" 1 "In the Detent Position" 2 "Error Indicator" 3 "Not Available" ;
VAL_ 2365401598 Jystck7GrpXAxsDetentPosStatus 0 "Not in the Detent Position" 1 "In the Detent Position" 2 "Error Indicator" 3 "Not Available" ;
VAL_ 2365401598 Joystick7Button16PressedStatus 0 "Button not pressed" 1 "Button pressed" 2 "Error Indicator" 3 "Not Available" ;
VAL_ 2365401598 Joystick7Button15PressedStatus 0 "Button not pressed" 1 "Button pressed" 2 "Error Indicator" 3 "Not Available" ;
VAL_ 2365401598 Joystick7Button14PressedStatus 0 "Button not pressed" 1 "Button pressed" 2 "Error Indicator" 3 "Not Available" ;
VAL_ 2365401598 Joystick7Button13PressedStatus 0 "Button not pressed" 1 "Button pressed" 2 "Error Indicator" 3 "Not Available" ;
VAL_ 2365401854 Jystck7XAxsNeutralPositionStatus 0 "Not in Neutral Position" 1 "In Neutral Position" 2 "Error Indicator" 3 "Not Available" ;
VAL_ 2365401854 Jystck7XAxsLvrLftNegPosStatus 0 "Not on negative side of Neutral" 1 "On negative side of Neutral" 2 "Error Indicator" 3 "Not Available" ;
VAL_ 2365401854 Jystck7XAxsLvrRightPstvPosStatus 0 "Not on Positive side of Neutral" 1 "On positive side of Neutral" 2 "Error Indicator" 3 "Not Available" ;
VAL_ 2365401854 Jystck7YAxsNeutralPositionStatus 0 "Not in Neutral Position" 1 "In Neutral Position" 2 "Error Indicator" 3 "Not Available" ;
VAL_ 2365401854 Jystck7YAxsLvrBackNegPosStatus 0 "Not on negative side of Neutral" 1 "On negative side of Neutral" 2 "Error Indicator" 3 "Not Available" ;
VAL_ 2365401854 Jystck7YAxsLvrFrwdPstvPosStatus 0 "Not on Positive side of Neutral" 1 "On positive side of Neutral" 2 "Error Indicator" 3 "Not Available" ;
VAL_ 2365401854 Jystck7YAxsDetentPositionStatus 0 "Not in the Detent Position" 1 "In the Detent Position" 2 "Error Indicator" 3 "Not Available" ;
VAL_ 2365401854 Jystck7XAxsDetentPositionStatus 0 "Not in the Detent Position" 1 "In the Detent Position" 2 "Error Indicator" 3 "Not Available" ;
VAL_ 2365401854 Joystick7Button4PressedStatus 0 "Button not pressed" 1 "Button pressed" 2 "Error Indicator" 3 "Not Available" ;
VAL_ 2365401854 Joystick7Button3PressedStatus 0 "Button not pressed" 1 "Button pressed" 2 "Error Indicator" 3 "Not Available" ;
VAL_ 2365401854 Joystick7Button2PressedStatus 0 "Button not pressed" 1 "Button pressed" 2 "Error Indicator" 3 "Not Available" ;
VAL_ 2365401854 Joystick7Button1PressedStatus 0 "Button not pressed" 1 "Button pressed" 2 "Error Indicator" 3 "Not Available" ;
VAL_ 2365401854 Joystick7Button8PressedStatus 0 "Button not pressed" 1 "Button pressed" 2 "Error Indicator" 3 "Not Available" ;
VAL_ 2365401854 Joystick7Button7PressedStatus 0 "Button not pressed" 1 "Button pressed" 2 "Error Indicator" 3 "Not Available" ;
VAL_ 2365401854 Joystick7Button6PressedStatus 0 "Button not pressed" 1 "Button pressed" 2 "Error Indicator" 3 "Not Available" ;
VAL_ 2365401854 Joystick7Button5PressedStatus 0 "Button not pressed" 1 "Button pressed" 2 "Error Indicator" 3 "Not Available" ;
VAL_ 2365401854 Joystick7Button12PressedStatus 0 "Button not pressed" 1 "Button pressed" 2 "Error Indicator" 3 "Not Available" ;
VAL_ 2365401854 Joystick7Button11PressedStatus 0 "Button not pressed" 1 "Button pressed" 2 "Error Indicator" 3 "Not Available" ;
VAL_ 2365401854 Joystick7Button10PressedStatus 0 "Button not pressed" 1 "Button pressed" 2 "Error Indicator" 3 "Not Available" ;
VAL_ 2365401854 Joystick7Button9PressedStatus 0 "Button not pressed" 1 "Button pressed" 2 "Error Indicator" 3 "Not Available" ;
VAL_ 2365402110 Jystck6GrpXAxsNtrlPositionStatus 0 "Not in Neutral Position" 1 "In Neutral Position" 2 "Error Indicator" 3 "Not Available" ;
VAL_ 2365402110 Jystck6GrpXAxsLvrLftNegPosStatus 0 "Not on negative side of Neutral" 1 "On negative side of Neutral" 2 "Error Indicator" 3 "Not Available" ;
VAL_ 2365402110 Jystck6GrpXAxsLvrRghtPstvPosStat 0 "Not on Positive side of Neutral" 1 "On positive side of Neutral" 2 "Error Indicator" 3 "Not Available" ;
VAL_ 2365402110 Jystck6GrpYAxsNtrlPositionStatus 0 "Not in Neutral Position" 1 "In Neutral Position" 2 "Error Indicator" 3 "Not Available" ;
VAL_ 2365402110 Jystck6GrpYAxsLvrBackNegPosStat 0 "Not on negative side of Neutral" 1 "On negative side of Neutral" 2 "Error Indicator" 3 "Not Available" ;
VAL_ 2365402110 Jystck6GrpYAxsLvrFrwdPstvPosStat 0 "Not on Positive side of Neutral" 1 "On positive side of Neutral" 2 "Error Indicator" 3 "Not Available" ;
VAL_ 2365402110 Jystck6ThetaAxsNtrlPosStatus 0 "Not in Neutral Position" 1 "In Neutral Position" 2 "Error Indicator" 3 "Not Available" ;
VAL_ 2365402110 Jystck6ThtAxsCntrClckwsNegPsStat 0 "Not on negative side of Neutral" 1 "On negative side of Neutral" 2 "Error Indicator" 3 "Not Available" ;
VAL_ 2365402110 Jystck6ThetaAxsClckwsPstvPosStat 0 "Not on Positive side of Neutral" 1 "On positive side of Neutral" 2 "Error Indicator" 3 "Not Available" ;
VAL_ 2365402110 Jystck6ThetaAxsDetentPosStatus 0 "Not in the Detent Position" 1 "In the Detent Position" 2 "Error Indicator" 3 "Not Available" ;
VAL_ 2365402110 Jystck6GrpYAxsDetentPosStatus 0 "Not in the Detent Position" 1 "In the Detent Position" 2 "Error Indicator" 3 "Not Available" ;
VAL_ 2365402110 Jystck6GrpXAxsDetentPosStatus 0 "Not in the Detent Position" 1 "In the Detent Position" 2 "Error Indicator" 3 "Not Available" ;
VAL_ 2365402110 Joystick6Button16PressedStatus 0 "Button not pressed" 1 "Button pressed" 2 "Error Indicator" 3 "Not Available" ;
VAL_ 2365402110 Joystick6Button15PressedStatus 0 "Button not pressed" 1 "Button pressed" 2 "Error Indicator" 3 "Not Available" ;
VAL_ 2365402110 Joystick6Button14PressedStatus 0 "Button not pressed" 1 "Button pressed" 2 "Error Indicator" 3 "Not Available" ;
VAL_ 2365402110 Joystick6Button13PressedStatus 0 "Button not pressed" 1 "Button pressed" 2 "Error Indicator" 3 "Not Available" ;
VAL_ 2365402366 Jystck6XAxsNeutralPositionStatus 0 "Not in Neutral Position" 1 "In Neutral Position" 2 "Error Indicator" 3 "Not Available" ;
VAL_ 2365402366 Jystck6XAxsLvrLftNegPosStatus 0 "Not on negative side of Neutral" 1 "On negative side of Neutral" 2 "Error Indicator" 3 "Not Available" ;
VAL_ 2365402366 Jystck6XAxsLvrRightPstvPosStatus 0 "Not on Positive side of Neutral" 1 "On positive side of Neutral" 2 "Error Indicator" 3 "Not Available" ;
VAL_ 2365402366 Jystck6YAxsNeutralPositionStatus 0 "Not in Neutral Position" 1 "In Neutral Position" 2 "Error Indicator" 3 "Not Available" ;
VAL_ 2365402366 Jystck6YAxsLvrBackNegPosStatus 0 "Not on negative side of Neutral" 1 "On negative side of Neutral" 2 "Error Indicator" 3 "Not Available" ;
VAL_ 2365402366 Jystck6YAxsLvrFrwdPstvPosStatus 0 "Not on Positive side of Neutral" 1 "On positive side of Neutral" 2 "Error Indicator" 3 "Not Available" ;
VAL_ 2365402366 Jystck6YAxsDetentPositionStatus 0 "Not in the Detent Position" 1 "In the Detent Position" 2 "Error Indicator" 3 "Not Available" ;
VAL_ 2365402366 Jystck6XAxsDetentPositionStatus 0 "Not in the Detent Position" 1 "In the Detent Position" 2 "Error Indicator" 3 "Not Available" ;
VAL_ 2365402366 Joystick6Button4PressedStatus 0 "Button not pressed" 1 "Button pressed" 2 "Error Indicator" 3 "Not Available" ;
VAL_ 2365402366 Joystick6Button3PressedStatus 0 "Button not pressed" 1 "Button pressed" 2 "Error Indicator" 3 "Not Available" ;
VAL_ 2365402366 Joystick6Button2PressedStatus 0 "Button not pressed" 1 "Button pressed" 2 "Error Indicator" 3 "Not Available" ;
VAL_ 2365402366 Joystick6Button1PressedStatus 0 "Button not pressed" 1 "Button pressed" 2 "Error Indicator" 3 "Not Available" ;
VAL_ 2365402366 Joystick6Button8PressedStatus 0 "Button not pressed" 1 "Button pressed" 2 "Error Indicator" 3 "Not Available" ;
VAL_ 2365402366 Joystick6Button7PressedStatus 0 "Button not pressed" 1 "Button pressed" 2 "Error Indicator" 3 "Not Available" ;
VAL_ 2365402366 Joystick6Button6PressedStatus 0 "Button not pressed" 1 "Button pressed" 2 "Error Indicator" 3 "Not Available" ;
VAL_ 2365402366 Joystick6Button5PressedStatus 0 "Button not pressed" 1 "Button pressed" 2 "Error Indicator" 3 "Not Available" ;
VAL_ 2365402366 Joystick6Button12PressedStatus 0 "Button not pressed" 1 "Button pressed" 2 "Error Indicator" 3 "Not Available" ;
VAL_ 2365402366 Joystick6Button11PressedStatus 0 "Button not pressed" 1 "Button pressed" 2 "Error Indicator" 3 "Not Available" ;
VAL_ 2365402366 Joystick6Button10PressedStatus 0 "Button not pressed" 1 "Button pressed" 2 "Error Indicator" 3 "Not Available" ;
VAL_ 2365402366 Joystick6Button9PressedStatus 0 "Button not pressed" 1 "Button pressed" 2 "Error Indicator" 3 "Not Available" ;
VAL_ 2365402622 Jystck5GrpXAxsNtrlPositionStatus 0 "Not in Neutral Position" 1 "In Neutral Position" 2 "Error Indicator" 3 "Not Available" ;
VAL_ 2365402622 Jystck5GrpXAxsLvrLftNegPosStatus 0 "Not on negative side of Neutral" 1 "On negative side of Neutral" 2 "Error Indicator" 3 "Not Available" ;
VAL_ 2365402622 Jystck5GrpXAxsLvrRghtPstvPosStat 0 "Not on Positive side of Neutral" 1 "On positive side of Neutral" 2 "Error Indicator" 3 "Not Available" ;
VAL_ 2365402622 Jystck5GrpYAxsNtrlPositionStatus 0 "Not in Neutral Position" 1 "In Neutral Position" 2 "Error Indicator" 3 "Not Available" ;
VAL_ 2365402622 Jystck5GrpYAxsLvrBackNegPosStat 0 "Not on negative side of Neutral" 1 "On negative side of Neutral" 2 "Error Indicator" 3 "Not Available" ;
VAL_ 2365402622 Jystck5GrpYAxsLvrFrwdPstvPosStat 0 "Not on Positive side of Neutral" 1 "On positive side of Neutral" 2 "Error Indicator" 3 "Not Available" ;
VAL_ 2365402622 Jystck5ThetaAxsNtrlPosStatus 0 "Not in Neutral Position" 1 "In Neutral Position" 2 "Error Indicator" 3 "Not Available" ;
VAL_ 2365402622 Jystck5ThtAxsCntrClckwsNegPsStat 0 "Not on negative side of Neutral" 1 "On negative side of Neutral" 2 "Error Indicator" 3 "Not Available" ;
VAL_ 2365402622 Jystck5ThetaAxsClckwsPstvPosStat 0 "Not on Positive side of Neutral" 1 "On positive side of Neutral" 2 "Error Indicator" 3 "Not Available" ;
VAL_ 2365402622 Jystck5ThetaAxsDetentPosStatus 0 "Not in the Detent Position" 1 "In the Detent Position" 2 "Error Indicator" 3 "Not Available" ;
VAL_ 2365402622 Jystck5GrpYAxsDetentPosStatus 0 "Not in the Detent Position" 1 "In the Detent Position" 2 "Error Indicator" 3 "Not Available" ;
VAL_ 2365402622 Jystck5GrpXAxsDetentPosStatus 0 "Not in the Detent Position" 1 "In the Detent Position" 2 "Error Indicator" 3 "Not Available" ;
VAL_ 2365402622 Joystick5Button16PressedStatus 0 "Button not pressed" 1 "Button pressed" 2 "Error Indicator" 3 "Not Available" ;
VAL_ 2365402622 Joystick5Button15PressedStatus 0 "Button not pressed" 1 "Button pressed" 2 "Error Indicator" 3 "Not Available" ;
VAL_ 2365402622 Joystick5Button14PressedStatus 0 "Button not pressed" 1 "Button pressed" 2 "Error Indicator" 3 "Not Available" ;
VAL_ 2365402622 Joystick5Button13PressedStatus 0 "Button not pressed" 1 "Button pressed" 2 "Error Indicator" 3 "Not Available" ;
VAL_ 2365402878 Jystck5XAxsNeutralPositionStatus 0 "Not in Neutral Position" 1 "In Neutral Position" 2 "Error Indicator" 3 "Not Available" ;
VAL_ 2365402878 Jystck5XAxsLvrLftNegPosStatus 0 "Not on negative side of Neutral" 1 "On negative side of Neutral" 2 "Error Indicator" 3 "Not Available" ;
VAL_ 2365402878 Jystck5XAxsLvrRightPstvPosStatus 0 "Not on Positive side of Neutral" 1 "On positive side of Neutral" 2 "Error Indicator" 3 "Not Available" ;
VAL_ 2365402878 Jystck5YAxsNeutralPositionStatus 0 "Not in Neutral Position" 1 "In Neutral Position" 2 "Error Indicator" 3 "Not Available" ;
VAL_ 2365402878 Jystck5YAxsLvrBackNegPosStatus 0 "Not on negative side of Neutral" 1 "On negative side of Neutral" 2 "Error Indicator" 3 "Not Available" ;
VAL_ 2365402878 Jystck5YAxsLvrFrwdPstvPosStatus 0 "Not on Positive side of Neutral" 1 "On positive side of Neutral" 2 "Error Indicator" 3 "Not Available" ;
VAL_ 2365402878 Jystck5YAxsDetentPositionStatus 0 "Not in the Detent Position" 1 "In the Detent Position" 2 "Error Indicator" 3 "Not Available" ;
VAL_ 2365402878 Jystck5XAxsDetentPositionStatus 0 "Not in the Detent Position" 1 "In the Detent Position" 2 "Error Indicator" 3 "Not Available" ;
VAL_ 2365402878 Joystick5Button4PressedStatus 0 "Button not pressed" 1 "Button pressed" 2 "Error Indicator" 3 "Not Available" ;
VAL_ 2365402878 Joystick5Button3PressedStatus 0 "Button not pressed" 1 "Button pressed" 2 "Error Indicator" 3 "Not Available" ;
VAL_ 2365402878 Joystick5Button2PressedStatus 0 "Button not pressed" 1 "Button pressed" 2 "Error Indicator" 3 "Not Available" ;
VAL_ 2365402878 Joystick5Button1PressedStatus 0 "Button not pressed" 1 "Button pressed" 2 "Error Indicator" 3 "Not Available" ;
VAL_ 2365402878 Joystick5Button8PressedStatus 0 "Button not pressed" 1 "Button pressed" 2 "Error Indicator" 3 "Not Available" ;
VAL_ 2365402878 Joystick5Button7PressedStatus 0 "Button not pressed" 1 "Button pressed" 2 "Error Indicator" 3 "Not Available" ;
VAL_ 2365402878 Joystick5Button6PressedStatus 0 "Button not pressed" 1 "Button pressed" 2 "Error Indicator" 3 "Not Available" ;
VAL_ 2365402878 Joystick5Button5PressedStatus 0 "Button not pressed" 1 "Button pressed" 2 "Error Indicator" 3 "Not Available" ;
VAL_ 2365402878 Joystick5Button12PressedStatus 0 "Button not pressed" 1 "Button pressed" 2 "Error Indicator" 3 "Not Available" ;
VAL_ 2365402878 Joystick5Button11PressedStatus 0 "Button not pressed" 1 "Button pressed" 2 "Error Indicator" 3 "Not Available" ;
VAL_ 2365402878 Joystick5Button10PressedStatus 0 "Button not pressed" 1 "Button pressed" 2 "Error Indicator" 3 "Not Available" ;
VAL_ 2365402878 Joystick5Button9PressedStatus 0 "Button not pressed" 1 "Button pressed" 2 "Error Indicator" 3 "Not Available" ;
VAL_ 2365403134 Jystck4GrpXAxsNtrlPositionStatus 0 "Not in Neutral Position" 1 "In Neutral Position" 2 "Error Indicator" 3 "Not Available" ;
VAL_ 2365403134 Jystck4GrpXAxsLvrLftNegPosStatus 0 "Not on negative side of Neutral" 1 "On negative side of Neutral" 2 "Error Indicator" 3 "Not Available" ;
VAL_ 2365403134 Jystck4GrpXAxsLvrRghtPstvPosStat 0 "Not on Positive side of Neutral" 1 "On positive side of Neutral" 2 "Error Indicator" 3 "Not Available" ;
VAL_ 2365403134 Jystck4GrpYAxsNtrlPositionStatus 0 "Not in Neutral Position" 1 "In Neutral Position" 2 "Error Indicator" 3 "Not Available" ;
VAL_ 2365403134 Jystck4GrpYAxsLvrBackNegPosStat 0 "Not on negative side of Neutral" 1 "On negative side of Neutral" 2 "Error Indicator" 3 "Not Available" ;
VAL_ 2365403134 Jystck4GrpYAxsLvrFrwdPstvPosStat 0 "Not on Positive side of Neutral" 1 "On positive side of Neutral" 2 "Error Indicator" 3 "Not Available" ;
VAL_ 2365403134 Jystck4ThetaAxsNtrlPosStatus 0 "Not in Neutral Position" 1 "In Neutral Position" 2 "Error Indicator" 3 "Not Available" ;
VAL_ 2365403134 Jystck4ThtAxsCntrClckwsNegPsStat 0 "Not on negative side of Neutral" 1 "On negative side of Neutral" 2 "Error Indicator" 3 "Not Available" ;
VAL_ 2365403134 Jystck4ThetaAxsClckwsPstvPosStat 0 "Not on Positive side of Neutral" 1 "On positive side of Neutral" 2 "Error Indicator" 3 "Not Available" ;
VAL_ 2365403134 Jystck4ThetaAxsDetentPosStatus 0 "Not in the Detent Position" 1 "In the Detent Position" 2 "Error Indicator" 3 "Not Available" ;
VAL_ 2365403134 Jystck4GrpYAxsDetentPosStatus 0 "Not in the Detent Position" 1 "In the Detent Position" 2 "Error Indicator" 3 "Not Available" ;
VAL_ 2365403134 Jystck4GrpXAxsDetentPosStatus 0 "Not in the Detent Position" 1 "In the Detent Position" 2 "Error Indicator" 3 "Not Available" ;
VAL_ 2365403134 Joystick4Button16PressedStatus 0 "Button not pressed" 1 "Button pressed" 2 "Error Indicator" 3 "Not Available" ;
VAL_ 2365403134 Joystick4Button15PressedStatus 0 "Button not pressed" 1 "Button pressed" 2 "Error Indicator" 3 "Not Available" ;
VAL_ 2365403134 Joystick4Button14PressedStatus 0 "Button not pressed" 1 "Button pressed" 2 "Error Indicator" 3 "Not Available" ;
VAL_ 2365403134 Joystick4Button13PressedStatus 0 "Button not pressed" 1 "Button pressed" 2 "Error Indicator" 3 "Not Available" ;
VAL_ 2365403390 Jystck4XAxsNeutralPositionStatus 0 "Not in Neutral Position" 1 "In Neutral Position" 2 "Error Indicator" 3 "Not Available" ;
VAL_ 2365403390 Jystck4XAxsLvrLftNegPosStatus 0 "Not on negative side of Neutral" 1 "On negative side of Neutral" 2 "Error Indicator" 3 "Not Available" ;
VAL_ 2365403390 Jystck4XAxsLvrRightPstvPosStatus 0 "Not on Positive side of Neutral" 1 "On positive side of Neutral" 2 "Error Indicator" 3 "Not Available" ;
VAL_ 2365403390 Jystck4YAxsNeutralPositionStatus 0 "Not in Neutral Position" 1 "In Neutral Position" 2 "Error Indicator" 3 "Not Available" ;
VAL_ 2365403390 Jystck4YAxsLvrBackNegPosStatus 0 "Not on negative side of Neutral" 1 "On negative side of Neutral" 2 "Error Indicator" 3 "Not Available" ;
VAL_ 2365403390 Jystck4YAxsLvrFrwdPstvPosStatus 0 "Not on Positive side of Neutral" 1 "On positive side of Neutral" 2 "Error Indicator" 3 "Not Available" ;
VAL_ 2365403390 Jystck4YAxsDetentPositionStatus 0 "Not in the Detent Position" 1 "In the Detent Position" 2 "Error Indicator" 3 "Not Available" ;
VAL_ 2365403390 Jystck4XAxsDetentPositionStatus 0 "Not in the Detent Position" 1 "In the Detent Position" 2 "Error Indicator" 3 "Not Available" ;
VAL_ 2365403390 Joystick4Button4PressedStatus 0 "Button not pressed" 1 "Button pressed" 2 "Error Indicator" 3 "Not Available" ;
VAL_ 2365403390 Joystick4Button3PressedStatus 0 "Button not pressed" 1 "Button pressed" 2 "Error Indicator" 3 "Not Available" ;
VAL_ 2365403390 Joystick4Button2PressedStatus 0 "Button not pressed" 1 "Button pressed" 2 "Error Indicator" 3 "Not Available" ;
VAL_ 2365403390 Joystick4Button1PressedStatus 0 "Button not pressed" 1 "Button pressed" 2 "Error Indicator" 3 "Not Available" ;
VAL_ 2365403390 Joystick4Button8PressedStatus 0 "Button not pressed" 1 "Button pressed" 2 "Error Indicator" 3 "Not Available" ;
VAL_ 2365403390 Joystick4Button7PressedStatus 0 "Button not pressed" 1 "Button pressed" 2 "Error Indicator" 3 "Not Available" ;
VAL_ 2365403390 Joystick4Button6PressedStatus 0 "Button not pressed" 1 "Button pressed" 2 "Error Indicator" 3 "Not Available" ;
VAL_ 2365403390 Joystick4Button5PressedStatus 0 "Button not pressed" 1 "Button pressed" 2 "Error Indicator" 3 "Not Available" ;
VAL_ 2365403390 Joystick4Button12PressedStatus 0 "Button not pressed" 1 "Button pressed" 2 "Error Indicator" 3 "Not Available" ;
VAL_ 2365403390 Joystick4Button11PressedStatus 0 "Button not pressed" 1 "Button pressed" 2 "Error Indicator" 3 "Not Available" ;
VAL_ 2365403390 Joystick4Button10PressedStatus 0 "Button not pressed" 1 "Button pressed" 2 "Error Indicator" 3 "Not Available" ;
VAL_ 2365403390 Joystick4Button9PressedStatus 0 "Button not pressed" 1 "Button pressed" 2 "Error Indicator" 3 "Not Available" ;
VAL_ 2566730238 Fan2DriveState 0 "Fan off" 1 "Engine system-General" 2 "Excessive engine air temperature" 3 "Excessive engine oil temperature" 4 "Excessive engine coolant temperature" 5 "Excessive transmission oil temperature" 6 "Excessive hydraulic oil temperature" 7 "Default Operation" 8 "Reverse Operation" 9 "Manual control" 10 "Transmission retarder" 11 "A/C system" 12 "Timer" 13 "Engine brake" 14 "Other" 15 "Not available" ;
VAL_ 2566730750 Aftrtrtmnt2DslExhstFldPumpState 0 "pump operational" 1 "pump error" 2 "reserved for SAE assignment" 3 "not available" ;
VAL_ 2566730750 Aftrtrtmnt2DslExhstFldPmpPwrRely 0 "not active" 1 "active" 2 "error" 3 "not available" ;
VAL_ 2566730750 Aftrtrtmnt2DslExhaustFluidPump 0 "Off" 1 "On" 2 "Error" 3 "Not available" ;
VAL_ 2566731518 Aftrtrtmnt2DslExhaustFluidType 0 "Urea concentration too high" 1 "Urea concentration too low" 2 "Fluid is diesel" 3 "Diesel exhaust fluid is proper mixture" 4 "Reserved for SAE assignment" 12 "Diesel exhaust fluid, but concentration cannot be determined" 13 "Not able to determine fluid property" 14 "Error with diesel exhaust fluid property detection" 15 "Not available" ;
VAL_ 2566732542 Aft2DslExhstFldDsrFltSupPrsionRq 0 "Error suppression off" 1 "Error suppression on" 2 "Reserved" 3 "Not available" ;
VAL_ 2566732542 Aft2DslExhstFldDoserHeatingMdeRq 0 "Heater off" 1 "Heater economy mode" 2 "Heater automatic mode" 3 "Heater on" 4 "Reserved" 7 "Not available" ;
VAL_ 2566732542 Aftrtrtmnt2DslExhstFldLineHtr1 0 "request for heater to be inactive" 1 "request for heater to be active" 2 "reserved for future assignment by SAE" 3 "not available" ;
VAL_ 2566732542 Aftrtrtmnt2DslExhstFldLineHtr2 0 "request for heater to be inactive" 1 "request for heater to be active" 2 "reserved for future assignment by SAE" 3 "not available" ;
VAL_ 2566732542 Aftrtrtmnt2DslExhstFldLineHtr3 0 "request for heater to be inactive" 1 "request for heater to be active" 2 "reserved for future assignment by SAE" 3 "not available" ;
VAL_ 2566732542 Aftrtrtmnt2DslExhstFldLineHtr4 0 "request for heater to be inactive" 1 "request for heater to be active" 2 "reserved for future assignment by SAE" 3 "not available" ;
VAL_ 2566732542 Aft2DslExhstFldLineHtrRely1 0 "Off" 1 "On" 2 "Error" 3 "Not available" ;
VAL_ 2566732542 Aft2DslExhstFldLineHtrRely2 0 "Off" 1 "On" 2 "Error" 3 "Not available" ;
VAL_ 2566732542 Aft2DslExhstFldLineHtrRely3 0 "Off" 1 "On" 2 "Error" 3 "Not available" ;
VAL_ 2566732542 Aftrtrtmnt2DslExhstFldLineHtr5 0 "request for heater to be inactive" 1 "request for heater to be active" 2 "reserved for future assignment by SAE" 3 "not available" ;
VAL_ 2566732542 Aftrtrtmnt2DslExhstFldLineHtr6 0 "request for heater to be inactive" 1 "request for heater to be active" 2 "reserved for future assignment by SAE" 3 "not available" ;
VAL_ 2566732542 Aftrtrtmnt2DslExhstFldLineHtr7 0 "request for heater to be inactive" 1 "request for heater to be active" 2 "reserved for future assignment by SAE" 3 "not available" ;
VAL_ 2566732542 Aftrtrtmnt2DslExhstFldLineHtr8 0 "request for heater to be inactive" 1 "request for heater to be active" 2 "reserved for future assignment by SAE" 3 "not available" ;
VAL_ 2566732542 Aftrtrtmnt2DslExhstFldLineHtr9 0 "request for heater to be inactive" 1 "request for heater to be active" 2 "reserved for future assignment by SAE" 3 "not available" ;
VAL_ 2566732542 Aftrtrtmnt2DslExhstFldLineHtr10 0 "request for heater to be inactive" 1 "request for heater to be active" 2 "reserved for future assignment by SAE" 3 "not available" ;
VAL_ 2566732798 Aft2SCRDsngVlvExhstTempRedRq 0 "no request" 1 "reduction request stage 1" 2 "reduction request stage 2" 3 "reserved for future assignment by SAE" 4 "reserved for future assignment by SAE" 5 "reserved for future assignment by SAE" 6 "error" 7 "not available" ;
VAL_ 2566732798 Aftrtrtmnt2SCRFeedbackCtrlStatus 0 "open loop control active" 1 "closed loop control active" 2 "reserved for future assignment by SAE" 3 "reserved for future assignment by SAE" 4 "reserved for future assignment by SAE" 5 "reserved for future assignment by SAE" 6 "error" 7 "not available" ;
VAL_ 2566732798 Aft2DslExhstFldLineHtr1Stat 0 "heater inactive" 1 "heater active" 2 "error" 3 "not available" ;
VAL_ 2566732798 Aft2DslExhstFldLineHtr2Stat 0 "heater inactive" 1 "heater active" 2 "error" 3 "not available" ;
VAL_ 2566732798 Aft2DslExhstFldLineHtr3Stat 0 "heater inactive" 1 "heater active" 2 "error" 3 "not available" ;
VAL_ 2566732798 Aft2DslExhstFldLineHtr4Stat 0 "heater inactive" 1 "heater active" 2 "error" 3 "not available" ;
VAL_ 2566733054 Aftrtrtmnt1DslExhstFldPumpState 0 "pump operational" 1 "pump error" 2 "reserved for SAE assignment" 3 "not available" ;
VAL_ 2566733054 Aftrtrtmnt1DslExhstFldPmpPwrRely 0 "not active" 1 "active" 2 "error" 3 "not available" ;
VAL_ 2566733054 Aftrtrtmnt1DslExhaustFluidPump 0 "Off" 1 "On" 2 "Error" 3 "Not available" ;
VAL_ 2566734078 Aft1DslExhstFldDsrFltSupPrsionRq 0 "Error suppression off" 1 "Error suppression on" 2 "Reserved" 3 "Not available" ;
VAL_ 2566734078 Aft1DslExhstFldDoserHeatingMdeRq 0 "Heater off" 1 "Heater economy mode" 2 "Heater automatic mode" 3 "Heater on" 4 "Reserved" 7 "Not available" ;
VAL_ 2566734078 Aftrtrtmnt1DslExhstFldLineHtr1 0 "request for heater to be inactive" 1 "request for heater to be active" 2 "reserved for future assignment by SAE" 3 "not available" ;
VAL_ 2566734078 Aftrtrtmnt1DslExhstFldLineHtr2 0 "request for heater to be inactive" 1 "request for heater to be active" 2 "reserved for future assignment by SAE" 3 "not available" ;
VAL_ 2566734078 Aftrtrtmnt1DslExhstFldLineHtr3 0 "request for heater to be inactive" 1 "request for heater to be active" 2 "reserved for future assignment by SAE" 3 "not available" ;
VAL_ 2566734078 Aftrtrtmnt1DslExhstFldLineHtr4 0 "request for heater to be inactive" 1 "request for heater to be active" 2 "reserved for future assignment by SAE" 3 "not available" ;
VAL_ 2566734078 Aft1DslExhstFldLineHtrRely1 0 "Off" 1 "On" 2 "Error" 3 "Not available" ;
VAL_ 2566734078 Aft1DslExhstFldLineHtrRely2 0 "Off" 1 "On" 2 "Error" 3 "Not available" ;
VAL_ 2566734078 Aft1DslExhstFldLineHtrRely3 0 "Off" 1 "On" 2 "Error" 3 "Not available" ;
VAL_ 2566734078 Aftrtrtmnt1DslExhstFldLineHtr5 0 "request for heater to be inactive" 1 "request for heater to be active" 2 "reserved for future assignment by SAE" 3 "not available" ;
VAL_ 2566734078 Aftrtrtmnt1DslExhstFldLineHtr6 0 "request for heater to be inactive" 1 "request for heater to be active" 2 "reserved for future assignment by SAE" 3 "not available" ;
VAL_ 2566734078 Aftrtrtmnt1DslExhstFldLineHtr7 0 "request for heater to be inactive" 1 "request for heater to be active" 2 "reserved for future assignment by SAE" 3 "not available" ;
VAL_ 2566734078 Aftrtrtmnt1DslExhstFldLineHtr8 0 "request for heater to be inactive" 1 "request for heater to be active" 2 "reserved for future assignment by SAE" 3 "not available" ;
VAL_ 2566734078 Aftrtrtmnt1DslExhstFldLineHtr9 0 "request for heater to be inactive" 1 "request for heater to be active" 2 "reserved for future assignment by SAE" 3 "not available" ;
VAL_ 2566734078 Aftrtrtmnt1DslExhstFldLineHtr10 0 "request for heater to be inactive" 1 "request for heater to be active" 2 "reserved for future assignment by SAE" 3 "not available" ;
VAL_ 2566734334 Aft1SCRDsngVlvExhstTempRedRq 0 "no request" 1 "reduction request stage 1" 2 "reduction request stage 2" 3 "reserved for future assignment by SAE" 4 "reserved for future assignment by SAE" 5 "reserved for future assignment by SAE" 6 "error" 7 "not available" ;
VAL_ 2566734334 Aftrtrtmnt1SCRFeedbackCtrlStatus 0 "open loop control active" 1 "closed loop control active" 2 "reserved for future assignment by SAE" 6 "error" 7 "not available" ;
VAL_ 2566734334 Aft1DslExhstFldLineHtr1Stat 0 "heater inactive" 1 "heater active" 2 "error" 3 "not available" ;
VAL_ 2566734334 Aft1DslExhstFldLineHtr2Stat 0 "heater inactive" 1 "heater active" 2 "error" 3 "not available" ;
VAL_ 2566734334 Aft1DslExhstFldLineHtr3Stat 0 "heater inactive" 1 "heater active" 2 "error" 3 "not available" ;
VAL_ 2566734334 Aft1DslExhstFldLineHtr4Stat 0 "heater inactive" 1 "heater active" 2 "error" 3 "not available" ;
VAL_ 2566734590 ISOBUSComplianceCertRevision 0 "First Revision" 1 "Second Revision" 2 "Third Revision" 3 "Fourth Revision" 4 "Reserved" 7 "Not available" ;
VAL_ 2566734590 ISOBUSCmplncCertLaboratoryType 0 "Non-certified laboratory/ self certification" 1 "EU certified laboratory" 2 "NA certified laboratory" 3 "Reserved" 7 "Not available/Not certified" ;
VAL_ 2566734590 ISOBUSCmplncCertTypeVTWrkSetMmbr 0 "Not certified" 1 "Certified" ;
VAL_ 2566734590 ISOBUSCmplncCertTypeVTWrkSetMstr 0 "Not certified" 1 "Certified" ;
VAL_ 2566734590 ISOBUSCmplncCertTypeVrtlTerminal 0 "Not certified" 1 "Certified" ;
VAL_ 2566734590 ISOBUSCmplncCertTypeClass3ECU 0 "Not certified" 1 "Certified" ;
VAL_ 2566734590 ISOBUSCmplncCertTypeTECUClass3 0 "Not certified" 1 "Certified" ;
VAL_ 2566734590 ISOBUSCmplncCertTypeTECUClass2 0 "Not certified" 1 "Certified" ;
VAL_ 2566734590 ISOBUSCmplncCertTypeTECUClass1 0 "Not certified" 1 "Certified" ;
VAL_ 2566734590 ISOBUSCmplncCertTypeMinimumECU 0 "Not certified" 1 "Certified" ;
VAL_ 2566734590 ISOBUSCmplncCertTypeGPSReceiver 0 "Not certified" 1 "Certified" ;
VAL_ 2566734590 ISOBUSCmplncCertTypeFileServer 0 "Not certified" 1 "Certified" ;
VAL_ 2566734590 ISOBUSCmplncCertTypeTCWrkSetMmbr 0 "Not certified" 1 "Certified" ;
VAL_ 2566734590 ISOBUSCmplncCertTypeTCWrkSetMstr 0 "Not certified" 1 "Certified" ;
VAL_ 2566734590 ISOBUSCmplncCertTypeTaskCtrller 0 "Not certified" 1 "Certified" ;
VAL_ 2566734846 MachineSlctedSpeedExitReasonCode 0 "No reason/all clear" 1 "Operator presence not detected" 2 "Implement released control of function" 3 "Operator override of function" 4 "Operator control not in valid position" 5 "Remote command timeout" 6 "Remote command out of range/invalid" 7 "Function not calibrated" 8 "Operator control fault" 9 "Function fault" 10 "Reserved" 20 "Hydraulic oil level too low" 21 "Valve locked out" 22 "Reserved" 41 "Manufacturer Specific" 62 "Error" 63 "Not available/not installed" ;
VAL_ 2566734846 MachineSelectedDirectionCommand 0 "Reverse" 1 "Forward" 2 "Reserved" 3 "Don't care, take no action" ;
VAL_ 2566735102 Aftrtrtmnt2FuelPumpRelayControl 0 "off" 1 "on" 2 "reserved for SAE assignment" 3 "not available" ;
VAL_ 2566735102 Aft2FuelFlwDiverterVlvCtrl 0 "off" 1 "on" 2 "reserved for SAE assignment" 3 "not available" ;
VAL_ 2566736126 EngExhstBnk2O2SensorClsdLpOp 0 "Open loop" 1 "Closed loop" 2 "Open loop due to driving conditions" 3 "Open loop" 4 "Closed loop, but fault with at least one oxygen sensor" 5 "reserved" 15 "not supported" ;
VAL_ 2566736382 EngExhstBnk1O2SensorClsdLpOp 0 "Open loop" 1 "Closed loop" 2 "Open loop due to driving conditions" 3 "Open loop" 4 "Closed loop, but fault with at least one oxygen sensor" 5 "reserved" 15 "not supported" ;
VAL_ 2432520702 AftercoolerCoolantThermostatMode 0 "temperature control mode" 1 "position control mode" 2 "reserved" 3 "don't care/reserved" ;
VAL_ 2432520702 EngineChrgAirCoolBypssValve1Cmd 0 "No air is bypassed" 100 "Full bypass capacity" ;
VAL_ 2432520702 EngineChrgAirCoolBypssValve2Cmd 0 "No air is bypassed" 100 "Full bypass capacity" ;
VAL_ 2432520958 EngineCoolantThermostatMode 0 "temperature control mode" 1 "position control mode" 2 "reserved" 3 "don't care/reserved" ;
VAL_ 2566739198 ProtectLamp 0 "Lamp Off" 1 "Lamp On" 2 "Reserved" 3 "Not available" ;
VAL_ 2566739198 AmberWarningLamp 0 "Lamp Off" 1 "Lamp On" 2 "Reserved" 3 "Not available" ;
VAL_ 2566739198 RedStopLamp 0 "Lamp Off" 1 "Lamp On" 2 "Reserved" 3 "Not available" ;
VAL_ 2566739198 MalfunctionIndicatorLamp 0 "Lamp Off" 1 "Lamp On" 2 "Short MIL for WWH OBD" 3 "Not available" ;
VAL_ 2566739198 FlashProtectLamp 0 "Slow Flash (1 Hz, 50 % duty cycle)" 1 "Fast Flash (2 Hz or faster, 50% duty cycle)" 2 "Reserved" 3 "Unavailable / Do Not Flash" ;
VAL_ 2566739198 FlashAmberWarningLamp 0 "Slow Flash (1 Hz, 50 % duty cycle)" 1 "Fast Flash (2 Hz or faster, 50% duty cycle)" 2 "Reserved" 3 "Unavailable / Do Not Flash" ;
VAL_ 2566739198 FlashRedStopLamp 0 "Slow Flash (1 Hz, 50 % duty cycle)" 1 "Fast Flash (2 Hz or faster, 50% duty cycle)" 2 "Reserved" 3 "Unavailable / Do Not Flash" ;
VAL_ 2566739198 FlashMalfunctionIndicatorLamp 0 "Slow Flash (1 Hz, 50 % duty cycle)" 1 "Fast Flash (2 Hz or faster, 50% duty cycle)" 2 "Class C DTC" 3 "Unavailable / Do Not Flash" ;
VAL_ 2566739198 SPNConversionMethod 0 "Convert SPN per Version 4" 1 "Convert SPN per Version 1, 2 or 3" ;
VAL_ 2566739454 ProtectLamp 0 "Lamp Off" 1 "Lamp On" 2 "Reserved" 3 "Not available" ;
VAL_ 2566739454 AmberWarningLamp 0 "Lamp Off" 1 "Lamp On" 2 "Reserved" 3 "Not available" ;
VAL_ 2566739454 RedStopLamp 0 "Lamp Off" 1 "Lamp On" 2 "Reserved" 3 "Not available" ;
VAL_ 2566739454 MalfunctionIndicatorLamp 0 "Lamp Off" 1 "Lamp On" 2 "Short MIL for WWH OBD" 3 "Not available" ;
VAL_ 2566739454 FlashProtectLamp 0 "Slow Flash (1 Hz, 50 % duty cycle)" 1 "Fast Flash (2 Hz or faster, 50% duty cycle)" 2 "Reserved" 3 "Unavailable / Do Not Flash" ;
VAL_ 2566739454 FlashAmberWarningLamp 0 "Slow Flash (1 Hz, 50 % duty cycle)" 1 "Fast Flash (2 Hz or faster, 50% duty cycle)" 2 "Reserved" 3 "Unavailable / Do Not Flash" ;
VAL_ 2566739454 FlashRedStopLamp 0 "Slow Flash (1 Hz, 50 % duty cycle)" 1 "Fast Flash (2 Hz or faster, 50% duty cycle)" 2 "Reserved" 3 "Unavailable / Do Not Flash" ;
VAL_ 2566739454 FlashMalfunctionIndicatorLamp 0 "Slow Flash (1 Hz, 50 % duty cycle)" 1 "Fast Flash (2 Hz or faster, 50% duty cycle)" 2 "Class C DTC" 3 "Unavailable / Do Not Flash" ;
VAL_ 2566739454 SPNConversionMethod 0 "Convert SPN per Version 4" 1 "Convert SPN per Version 1, 2 or 3" ;
VAL_ 2566739710 ProtectLamp 0 "Lamp Off" 1 "Lamp On" 2 "Reserved" 3 "Not available" ;
VAL_ 2566739710 AmberWarningLamp 0 "Lamp Off" 1 "Lamp On" 2 "Reserved" 3 "Not available" ;
VAL_ 2566739710 RedStopLamp 0 "Lamp Off" 1 "Lamp On" 2 "Reserved" 3 "Not available" ;
VAL_ 2566739710 MalfunctionIndicatorLamp 0 "Lamp Off" 1 "Lamp On" 2 "Short MIL for WWH OBD" 3 "Not available" ;
VAL_ 2566739710 FlashProtectLamp 0 "Slow Flash (1 Hz, 50 % duty cycle)" 1 "Fast Flash (2 Hz or faster, 50% duty cycle)" 2 "Reserved" 3 "Unavailable / Do Not Flash" ;
VAL_ 2566739710 FlashAmberWarningLamp 0 "Slow Flash (1 Hz, 50 % duty cycle)" 1 "Fast Flash (2 Hz or faster, 50% duty cycle)" 2 "Reserved" 3 "Unavailable / Do Not Flash" ;
VAL_ 2566739710 FlashRedStopLamp 0 "Slow Flash (1 Hz, 50 % duty cycle)" 1 "Fast Flash (2 Hz or faster, 50% duty cycle)" 2 "Reserved" 3 "Unavailable / Do Not Flash" ;
VAL_ 2566739710 FlashMalfunctionIndicatorLamp 0 "Slow Flash (1 Hz, 50 % duty cycle)" 1 "Fast Flash (2 Hz or faster, 50% duty cycle)" 2 "Class C DTC" 3 "Unavailable / Do Not Flash" ;
VAL_ 2566739710 SPNConversionMethod 0 "Convert SPN per Version 4" 1 "Convert SPN per Version 1, 2 or 3" ;
VAL_ 2566739966 ProtectLamp 0 "Lamp Off" 1 "Lamp On" 2 "Reserved" 3 "Not available" ;
VAL_ 2566739966 AmberWarningLamp 0 "Lamp Off" 1 "Lamp On" 2 "Reserved" 3 "Not available" ;
VAL_ 2566739966 RedStopLamp 0 "Lamp Off" 1 "Lamp On" 2 "Reserved" 3 "Not available" ;
VAL_ 2566739966 MalfunctionIndicatorLamp 0 "Lamp Off" 1 "Lamp On" 2 "Short MIL for WWH OBD" 3 "Not available" ;
VAL_ 2566739966 FlashProtectLamp 0 "Slow Flash (1 Hz, 50 % duty cycle)" 1 "Fast Flash (2 Hz or faster, 50% duty cycle)" 2 "Reserved" 3 "Unavailable / Do Not Flash" ;
VAL_ 2566739966 FlashAmberWarningLamp 0 "Slow Flash (1 Hz, 50 % duty cycle)" 1 "Fast Flash (2 Hz or faster, 50% duty cycle)" 2 "Reserved" 3 "Unavailable / Do Not Flash" ;
VAL_ 2566739966 FlashRedStopLamp 0 "Slow Flash (1 Hz, 50 % duty cycle)" 1 "Fast Flash (2 Hz or faster, 50% duty cycle)" 2 "Reserved" 3 "Unavailable / Do Not Flash" ;
VAL_ 2566739966 FlashMalfunctionIndicatorLamp 0 "Slow Flash (1 Hz, 50 % duty cycle)" 1 "Fast Flash (2 Hz or faster, 50% duty cycle)" 2 "Class C DTC" 3 "Unavailable / Do Not Flash" ;
VAL_ 2566739966 SPNConversionMethod 0 "Convert SPN per Version 4" 1 "Convert SPN per Version 1, 2 or 3" ;
VAL_ 2566740222 ProtectLamp 0 "Lamp Off" 1 "Lamp On" 2 "Reserved" 3 "Not available" ;
VAL_ 2566740222 AmberWarningLamp 0 "Lamp Off" 1 "Lamp On" 2 "Reserved" 3 "Not available" ;
VAL_ 2566740222 RedStopLamp 0 "Lamp Off" 1 "Lamp On" 2 "Reserved" 3 "Not available" ;
VAL_ 2566740222 MalfunctionIndicatorLamp 0 "Lamp Off" 1 "Lamp On" 2 "Short MIL for WWH OBD" 3 "Not available" ;
VAL_ 2566740222 FlashProtectLamp 0 "Slow Flash (1 Hz, 50 % duty cycle)" 1 "Fast Flash (2 Hz or faster, 50% duty cycle)" 2 "Reserved" 3 "Unavailable / Do Not Flash" ;
VAL_ 2566740222 FlashAmberWarningLamp 0 "Slow Flash (1 Hz, 50 % duty cycle)" 1 "Fast Flash (2 Hz or faster, 50% duty cycle)" 2 "Reserved" 3 "Unavailable / Do Not Flash" ;
VAL_ 2566740222 FlashRedStopLamp 0 "Slow Flash (1 Hz, 50 % duty cycle)" 1 "Fast Flash (2 Hz or faster, 50% duty cycle)" 2 "Reserved" 3 "Unavailable / Do Not Flash" ;
VAL_ 2566740222 FlashMalfunctionIndicatorLamp 0 "Slow Flash (1 Hz, 50 % duty cycle)" 1 "Fast Flash (2 Hz or faster, 50% duty cycle)" 2 "Class C DTC" 3 "Unavailable / Do Not Flash" ;
VAL_ 2566740222 SPNConversionMethod 0 "Convert SPN per Version 4" 1 "Convert SPN per Version 1, 2 or 3" ;
VAL_ 2566740478 ProtectLamp 0 "Lamp Off" 1 "Lamp On" 2 "Reserved" 3 "Not available" ;
VAL_ 2566740478 AmberWarningLamp 0 "Lamp Off" 1 "Lamp On" 2 "Reserved" 3 "Not available" ;
VAL_ 2566740478 RedStopLamp 0 "Lamp Off" 1 "Lamp On" 2 "Reserved" 3 "Not available" ;
VAL_ 2566740478 MalfunctionIndicatorLamp 0 "Lamp Off" 1 "Lamp On" 2 "Short MIL for WWH OBD" 3 "Not available" ;
VAL_ 2566740478 FlashProtectLamp 0 "Slow Flash (1 Hz, 50 % duty cycle)" 1 "Fast Flash (2 Hz or faster, 50% duty cycle)" 2 "Reserved" 3 "Unavailable / Do Not Flash" ;
VAL_ 2566740478 FlashAmberWarningLamp 0 "Slow Flash (1 Hz, 50 % duty cycle)" 1 "Fast Flash (2 Hz or faster, 50% duty cycle)" 2 "Reserved" 3 "Unavailable / Do Not Flash" ;
VAL_ 2566740478 FlashRedStopLamp 0 "Slow Flash (1 Hz, 50 % duty cycle)" 1 "Fast Flash (2 Hz or faster, 50% duty cycle)" 2 "Reserved" 3 "Unavailable / Do Not Flash" ;
VAL_ 2566740478 FlashMalfunctionIndicatorLamp 0 "Slow Flash (1 Hz, 50 % duty cycle)" 1 "Fast Flash (2 Hz or faster, 50% duty cycle)" 2 "Class C DTC" 3 "Unavailable / Do Not Flash" ;
VAL_ 2566740478 SPNConversionMethod 0 "Convert SPN per Version 4" 1 "Convert SPN per Version 1, 2 or 3" ;
VAL_ 2566740734 ProtectLamp 0 "Lamp Off" 1 "Lamp On" 2 "Reserved" 3 "Not available" ;
VAL_ 2566740734 AmberWarningLamp 0 "Lamp Off" 1 "Lamp On" 2 "Reserved" 3 "Not available" ;
VAL_ 2566740734 RedStopLamp 0 "Lamp Off" 1 "Lamp On" 2 "Reserved" 3 "Not available" ;
VAL_ 2566740734 MalfunctionIndicatorLamp 0 "Lamp Off" 1 "Lamp On" 2 "Short MIL for WWH OBD" 3 "Not available" ;
VAL_ 2566740734 FlashProtectLamp 0 "Slow Flash (1 Hz, 50 % duty cycle)" 1 "Fast Flash (2 Hz or faster, 50% duty cycle)" 2 "Reserved" 3 "Unavailable / Do Not Flash" ;
VAL_ 2566740734 FlashAmberWarningLamp 0 "Slow Flash (1 Hz, 50 % duty cycle)" 1 "Fast Flash (2 Hz or faster, 50% duty cycle)" 2 "Reserved" 3 "Unavailable / Do Not Flash" ;
VAL_ 2566740734 FlashRedStopLamp 0 "Slow Flash (1 Hz, 50 % duty cycle)" 1 "Fast Flash (2 Hz or faster, 50% duty cycle)" 2 "Reserved" 3 "Unavailable / Do Not Flash" ;
VAL_ 2566740734 FlashMalfunctionIndicatorLamp 0 "Slow Flash (1 Hz, 50 % duty cycle)" 1 "Fast Flash (2 Hz or faster, 50% duty cycle)" 2 "Class C DTC" 3 "Unavailable / Do Not Flash" ;
VAL_ 2566740734 SPNConversionMethod 0 "Convert SPN per Version 4" 1 "Convert SPN per Version 1, 2 or 3" ;
VAL_ 2566740990 ProtectLamp 0 "Lamp Off" 1 "Lamp On" 2 "Reserved" 3 "Not available" ;
VAL_ 2566740990 AmberWarningLamp 0 "Lamp Off" 1 "Lamp On" 2 "Reserved" 3 "Not available" ;
VAL_ 2566740990 RedStopLamp 0 "Lamp Off" 1 "Lamp On" 2 "Reserved" 3 "Not available" ;
VAL_ 2566740990 MalfunctionIndicatorLamp 0 "Lamp Off" 1 "Lamp On" 2 "Short MIL for WWH OBD" 3 "Not available" ;
VAL_ 2566740990 FlashProtectLamp 0 "Slow Flash (1 Hz, 50 % duty cycle)" 1 "Fast Flash (2 Hz or faster, 50% duty cycle)" 2 "Reserved" 3 "Unavailable / Do Not Flash" ;
VAL_ 2566740990 FlashAmberWarningLamp 0 "Slow Flash (1 Hz, 50 % duty cycle)" 1 "Fast Flash (2 Hz or faster, 50% duty cycle)" 2 "Reserved" 3 "Unavailable / Do Not Flash" ;
VAL_ 2566740990 FlashRedStopLamp 0 "Slow Flash (1 Hz, 50 % duty cycle)" 1 "Fast Flash (2 Hz or faster, 50% duty cycle)" 2 "Reserved" 3 "Unavailable / Do Not Flash" ;
VAL_ 2566740990 FlashMalfunctionIndicatorLamp 0 "Slow Flash (1 Hz, 50 % duty cycle)" 1 "Fast Flash (2 Hz or faster, 50% duty cycle)" 2 "Class C DTC" 3 "Unavailable / Do Not Flash" ;
VAL_ 2566740990 SPNConversionMethod 0 "Convert SPN per Version 4" 1 "Convert SPN per Version 1, 2 or 3" ;
VAL_ 2566741246 ProtectLamp 0 "Lamp Off" 1 "Lamp On" 2 "Reserved" 3 "Not available" ;
VAL_ 2566741246 AmberWarningLamp 0 "Lamp Off" 1 "Lamp On" 2 "Reserved" 3 "Not available" ;
VAL_ 2566741246 RedStopLamp 0 "Lamp Off" 1 "Lamp On" 2 "Reserved" 3 "Not available" ;
VAL_ 2566741246 MalfunctionIndicatorLamp 0 "Lamp Off" 1 "Lamp On" 2 "Short MIL for WWH OBD" 3 "Not available" ;
VAL_ 2566741246 FlashProtectLamp 0 "Slow Flash (1 Hz, 50 % duty cycle)" 1 "Fast Flash (2 Hz or faster, 50% duty cycle)" 2 "Reserved" 3 "Unavailable / Do Not Flash" ;
VAL_ 2566741246 FlashAmberWarningLamp 0 "Slow Flash (1 Hz, 50 % duty cycle)" 1 "Fast Flash (2 Hz or faster, 50% duty cycle)" 2 "Reserved" 3 "Unavailable / Do Not Flash" ;
VAL_ 2566741246 FlashRedStopLamp 0 "Slow Flash (1 Hz, 50 % duty cycle)" 1 "Fast Flash (2 Hz or faster, 50% duty cycle)" 2 "Reserved" 3 "Unavailable / Do Not Flash" ;
VAL_ 2566741246 FlashMalfunctionIndicatorLamp 0 "Slow Flash (1 Hz, 50 % duty cycle)" 1 "Fast Flash (2 Hz or faster, 50% duty cycle)" 2 "Class C DTC" 3 "Unavailable / Do Not Flash" ;
VAL_ 2566741246 SPNConversionMethod 0 "Convert SPN per Version 4" 1 "Convert SPN per Version 1, 2 or 3" ;
VAL_ 2566741502 ProtectLamp 0 "Lamp Off" 1 "Lamp On" 2 "Reserved" 3 "Not available" ;
VAL_ 2566741502 AmberWarningLamp 0 "Lamp Off" 1 "Lamp On" 2 "Reserved" 3 "Not available" ;
VAL_ 2566741502 RedStopLamp 0 "Lamp Off" 1 "Lamp On" 2 "Reserved" 3 "Not available" ;
VAL_ 2566741502 MalfunctionIndicatorLamp 0 "Lamp Off" 1 "Lamp On" 2 "Short MIL for WWH OBD" 3 "Not available" ;
VAL_ 2566741502 FlashProtectLamp 0 "Slow Flash (1 Hz, 50 % duty cycle)" 1 "Fast Flash (2 Hz or faster, 50% duty cycle)" 2 "Reserved" 3 "Unavailable / Do Not Flash" ;
VAL_ 2566741502 FlashAmberWarningLamp 0 "Slow Flash (1 Hz, 50 % duty cycle)" 1 "Fast Flash (2 Hz or faster, 50% duty cycle)" 2 "Reserved" 3 "Unavailable / Do Not Flash" ;
VAL_ 2566741502 FlashRedStopLamp 0 "Slow Flash (1 Hz, 50 % duty cycle)" 1 "Fast Flash (2 Hz or faster, 50% duty cycle)" 2 "Reserved" 3 "Unavailable / Do Not Flash" ;
VAL_ 2566741502 FlashMalfunctionIndicatorLamp 0 "Slow Flash (1 Hz, 50 % duty cycle)" 1 "Fast Flash (2 Hz or faster, 50% duty cycle)" 2 "Class C DTC" 3 "Unavailable / Do Not Flash" ;
VAL_ 2566741502 SPNConversionMethod 0 "Convert SPN per Version 4" 1 "Convert SPN per Version 1, 2 or 3" ;
VAL_ 2566741758 ProtectLamp 0 "Lamp Off" 1 "Lamp On" 2 "Reserved" 3 "Not available" ;
VAL_ 2566741758 AmberWarningLamp 0 "Lamp Off" 1 "Lamp On" 2 "Reserved" 3 "Not available" ;
VAL_ 2566741758 RedStopLamp 0 "Lamp Off" 1 "Lamp On" 2 "Reserved" 3 "Not available" ;
VAL_ 2566741758 MalfunctionIndicatorLamp 0 "Lamp Off" 1 "Lamp On" 2 "Short MIL for WWH OBD" 3 "Not available" ;
VAL_ 2566741758 FlashProtectLamp 0 "Slow Flash (1 Hz, 50 % duty cycle)" 1 "Fast Flash (2 Hz or faster, 50% duty cycle)" 2 "Reserved" 3 "Unavailable / Do Not Flash" ;
VAL_ 2566741758 FlashAmberWarningLamp 0 "Slow Flash (1 Hz, 50 % duty cycle)" 1 "Fast Flash (2 Hz or faster, 50% duty cycle)" 2 "Reserved" 3 "Unavailable / Do Not Flash" ;
VAL_ 2566741758 FlashRedStopLamp 0 "Slow Flash (1 Hz, 50 % duty cycle)" 1 "Fast Flash (2 Hz or faster, 50% duty cycle)" 2 "Reserved" 3 "Unavailable / Do Not Flash" ;
VAL_ 2566741758 FlashMalfunctionIndicatorLamp 0 "Slow Flash (1 Hz, 50 % duty cycle)" 1 "Fast Flash (2 Hz or faster, 50% duty cycle)" 2 "Class C DTC" 3 "Unavailable / Do Not Flash" ;
VAL_ 2566741758 SPNConversionMethod 0 "Convert SPN per Version 4" 1 "Convert SPN per Version 1, 2 or 3" ;
VAL_ 2566742014 ProtectLamp 0 "Lamp Off" 1 "Lamp On" 2 "Reserved" 3 "Not available" ;
VAL_ 2566742014 AmberWarningLamp 0 "Lamp Off" 1 "Lamp On" 2 "Reserved" 3 "Not available" ;
VAL_ 2566742014 RedStopLamp 0 "Lamp Off" 1 "Lamp On" 2 "Reserved" 3 "Not available" ;
VAL_ 2566742014 MalfunctionIndicatorLamp 0 "Lamp Off" 1 "Lamp On" 2 "Short MIL for WWH OBD" 3 "Not available" ;
VAL_ 2566742014 FlashProtectLamp 0 "Slow Flash (1 Hz, 50 % duty cycle)" 1 "Fast Flash (2 Hz or faster, 50% duty cycle)" 2 "Reserved" 3 "Unavailable / Do Not Flash" ;
VAL_ 2566742014 FlashAmberWarningLamp 0 "Slow Flash (1 Hz, 50 % duty cycle)" 1 "Fast Flash (2 Hz or faster, 50% duty cycle)" 2 "Reserved" 3 "Unavailable / Do Not Flash" ;
VAL_ 2566742014 FlashRedStopLamp 0 "Slow Flash (1 Hz, 50 % duty cycle)" 1 "Fast Flash (2 Hz or faster, 50% duty cycle)" 2 "Reserved" 3 "Unavailable / Do Not Flash" ;
VAL_ 2566742014 FlashMalfunctionIndicatorLamp 0 "Slow Flash (1 Hz, 50 % duty cycle)" 1 "Fast Flash (2 Hz or faster, 50% duty cycle)" 2 "Class C DTC" 3 "Unavailable / Do Not Flash" ;
VAL_ 2566742014 SPNConversionMethod 0 "Convert SPN per Version 4" 1 "Convert SPN per Version 1, 2 or 3" ;
VAL_ 2566743038 SystemMalfnctnIndictrActvtnMode 0 "MI Activation Mode 1 (MI Off)" 1 "MI Activation Mode 2 (On Demand MI)" 2 "MI Activation Mode 3 (Short MI)" 3 "MI Activation Mode 4 (Continuous MI)" 14 "Error" 15 "Not available/Not required" ;
VAL_ 2566743038 SysMalfctIndictrDisplayStrategy 0 "System employs a non-discriminatory MI display" 1 "System employs a discriminatory MI display" 2 "Reserved" 3 "Not available/Not required" ;
VAL_ 2566743038 SystemCntnsMalfunctionIndicator 0 "System MI is not continuous" 1 "System MI is continuous" 2 "Reserved" 3 "Not available/Not required" ;
VAL_ 2566743550 Aftrtrtmnt1FuelPumpRelayControl 0 "off" 1 "on" 2 "reserved for SAE assignment" 3 "not available" ;
VAL_ 2566743550 Aft1FuelFlwDiverterVlvCtrl 0 "off" 1 "on" 2 "reserved for SAE assignment" 3 "not available" ;
VAL_ 2566744062 ZeroNetVehicleWeightChange 0 "No change to Net Vehicle Weight Change" 1 "Zero Net Vehicle Weight Change" 2 "Reserved" 3 "Not available / Not applicable" ;
VAL_ 2633853438 AxleGroupLocation 0 "Reserved" 1 "Sole or Forward-most Steer axle group" 2 "Lift axle group" 3 "Sole or Forward-most Drive axle group" 4 "Tag axle group" 5 "Additional tractor axle group" 6 "Trailer A axle group" 7 "Trailer B axle group" 8 "Trailer C axle group" 9 "Trailer D axle group" 10 "Trailer E axle group" 11 "Trailer F axle group" 12 "Trailer G axle group" 13 "Trailer H axle group" 14 "Additional trailer axle group" 15 "Reserved" ;
VAL_ 2633853438 AdditionalAxleGroupLocation 0 "Reserved" 1 "Rear Steer axle group" 2 "Rear Drive axle group" 3 "Reserved" ;
VAL_ 2499635966 AxleGroupLocation 0 "Reserved" 1 "Sole or Forward-most Steer axle group" 2 "Lift axle group" 3 "Sole or Forward-most Drive axle group" 4 "Tag axle group" 5 "Additional tractor axle group" 6 "Trailer A axle group" 7 "Trailer B axle group" 8 "Trailer C axle group" 9 "Trailer D axle group" 10 "Trailer E axle group" 11 "Trailer F axle group" 12 "Trailer G axle group" 13 "Trailer H axle group" 14 "Additional trailer axle group" 15 "Reserved" ;
VAL_ 2499635966 AdditionalAxleGroupLocation 0 "Reserved" 1 "Rear Steer axle group" 2 "Rear Drive axle group" 3 "Reserved" ;
VAL_ 2566745086 SoleOrFrwdMostSteerAxlGrpWghtAvl 0 "Steer axle group not present" 1 "Steer axle group present" 2 "Reserved" 3 "Not available / not applicable" ;
VAL_ 2566745086 LiftAxleGroupWeightAvailable 0 "Lift axle group not present" 1 "Lift axle group present" 2 "Reserved" 3 "Not available / not applicable" ;
VAL_ 2566745086 SoleOrFrwdMostDrvAxlGrpWeightAvl 0 "Drive axle group not present" 1 "Drive axle group present" 2 "Reserved" 3 "Not available / not applicable" ;
VAL_ 2566745086 TagAxleGroupWeightAvailable 0 "Tag axle group not present" 1 "Tag axle group present" 2 "Reserved" 3 "Not available / not applicable" ;
VAL_ 2566745086 AddtnlTractorAxlGroupWeightAvail 0 "Additional tractor axle group not present" 1 "Additional tractor axle group present" 2 "Reserved" 3 "Not available / not applicable" ;
VAL_ 2566745086 TrailerAAxleGroupWeightAvailable 0 "Trailer A axle group not present" 1 "Trailer A axle group present" 2 "Reserved" 3 "Not available / not applicable" ;
VAL_ 2566745086 TrailerBAxleGroupWeightAvailable 0 "Trailer B axle group not present" 1 "Trailer B axle group present" 2 "Reserved" 3 "Not available / not applicable" ;
VAL_ 2566745086 TrailerCAxleGroupWeightAvailable 0 "Trailer C axle group not present" 1 "Trailer C axle group present" 2 "Reserved" 3 "Not available / not applicable" ;
VAL_ 2566745086 TrailerDAxleGroupWeightAvailable 0 "Trailer D axle group not present" 1 "Trailer D axle group present" 2 "Reserved" 3 "Not available / not applicable" ;
VAL_ 2566745086 TrailerEAxleGroupWeightAvailable 0 "Trailer E axle group not present" 1 "Trailer E axle group present" 2 "Reserved" 3 "Not available / not applicable" ;
VAL_ 2566745086 TrailerFAxleGroupWeightAvailable 0 "Trailer F axle group not present" 1 "Trailer F axle group present" 2 "Reserved" 3 "Not available / not applicable" ;
VAL_ 2566745086 TrailerGAxleGroupWeightAvailable 0 "Trailer G axle group not present" 1 "Trailer G axle group present" 2 "Reserved" 3 "Not available / not applicable" ;
VAL_ 2566745086 TrailerHAxleGroupWeightAvailable 0 "Trailer H axle group not present" 1 "Trailer H axle group present" 2 "Reserved" 3 "Not available / not applicable" ;
VAL_ 2566745086 AddtnlTrailerAxlGroupWeightAvail 0 "Additional trailer axle group not present" 1 "Additional trailer axle group present" 2 "Reserved" 3 "Not available / not applicable" ;
VAL_ 2566745086 RearSteerAxleGroupWeightAvail 0 "Rear Steer axle group not present" 1 "Rear Steer axle group present" 2 "Reserved" 3 "Not available / not applicable" ;
VAL_ 2566745086 RearDriveAxleGroupWeightAvail 0 "Rear drive axle group not present" 1 "Rear drive axle group present" 2 "Reserved" 3 "Not available / not applicable" ;
VAL_ 2566746366 RetractStatusOfRamp1 0 "ramp retracted" 1 "ramp extended" 2 "error" 3 "not available" ;
VAL_ 2566746366 EnableStatusOfRamp1 0 "ramp disabled" 1 "ramp enabled" 2 "error" 3 "not available" ;
VAL_ 2566746366 MovementStatusOfRamp1 0 "ramp not being moved" 1 "ramp being moved" 2 "error" 3 "not available" ;
VAL_ 2566746366 RetractStatusOfRamp2 0 "ramp retracted" 1 "ramp extended" 2 "error" 3 "not available" ;
VAL_ 2566746366 EnableStatusOfRamp2 0 "ramp disabled" 1 "ramp enabled" 2 "error" 3 "not available" ;
VAL_ 2566746366 MovementStatusOfRamp2 0 "ramp not being moved" 1 "ramp being moved" 2 "error" 3 "not available" ;
VAL_ 2566746366 RetractStatusOfRamp3 0 "ramp retracted" 1 "ramp extended" 2 "error" 3 "not available" ;
VAL_ 2566746366 EnableStatusOfRamp3 0 "ramp disabled" 1 "ramp enabled" 2 "error" 3 "not available" ;
VAL_ 2566746366 MovementStatusOfRamp3 0 "ramp not being moved" 1 "ramp being moved" 2 "error" 3 "not available" ;
VAL_ 2566746366 RetractStatusOfRamp4 0 "ramp retracted" 1 "ramp extended" 2 "error" 3 "not available" ;
VAL_ 2566746366 EnableStatusOfRamp4 0 "ramp disabled" 1 "ramp enabled" 2 "error" 3 "not available" ;
VAL_ 2566746366 MovementStatusOfRamp4 0 "ramp not being moved" 1 "ramp being moved" 2 "error" 3 "not available" ;
VAL_ 2566746366 RetractStatusOfRamp5 0 "ramp retracted" 1 "ramp extended" 2 "error" 3 "not available" ;
VAL_ 2566746366 EnableStatusOfRamp5 0 "ramp disabled" 1 "ramp enabled" 2 "error" 3 "not available" ;
VAL_ 2566746366 MovementStatusOfRamp5 0 "ramp not being moved" 1 "ramp being moved" 2 "error" 3 "not available" ;
VAL_ 2566746622 TractorBrakeStrokeAxle1Left 0 "OK (Normal operation)" 1 "Non-functioning" 2 "Overstroke" 3 "Dragging brake" 4 "Reserved" 5 "Reserved" 6 "Sensor error" 7 "Not available" ;
VAL_ 2566746622 TractorBrakeStrokeAxle1Right 0 "OK (Normal operation)" 1 "Non-functioning" 2 "Overstroke" 3 "Dragging brake" 4 "Reserved" 5 "Reserved" 6 "Sensor error" 7 "Not available" ;
VAL_ 2566746622 TractorBrakeStrokeAxle2Left 0 "OK (Normal operation)" 1 "Non-functioning" 2 "Overstroke" 3 "Dragging brake" 4 "Reserved" 5 "Reserved" 6 "Sensor error" 7 "Not available" ;
VAL_ 2566746622 TractorBrakeStrokeAxle2Right 0 "OK (Normal operation)" 1 "Non-functioning" 2 "Overstroke" 3 "Dragging brake" 4 "Reserved" 5 "Reserved" 6 "Sensor error" 7 "Not available" ;
VAL_ 2566746622 TractorBrakeStrokeAxle3Left 0 "OK (Normal operation)" 1 "Non-functioning" 2 "Overstroke" 3 "Dragging brake" 4 "Reserved" 5 "Reserved" 6 "Sensor error" 7 "Not available" ;
VAL_ 2566746622 TractorBrakeStrokeAxle3Right 0 "OK (Normal operation)" 1 "Non-functioning" 2 "Overstroke" 3 "Dragging brake" 4 "Reserved" 5 "Reserved" 6 "Sensor error" 7 "Not available" ;
VAL_ 2566746622 TractorBrakeStrokeAxle4Left 0 "OK (Normal operation)" 1 "Non-functioning" 2 "Overstroke" 3 "Dragging brake" 4 "Reserved" 5 "Reserved" 6 "Sensor error" 7 "Not available" ;
VAL_ 2566746622 TractorBrakeStrokeAxle4Right 0 "OK (Normal operation)" 1 "Non-functioning" 2 "Overstroke" 3 "Dragging brake" 4 "Reserved" 5 "Reserved" 6 "Sensor error" 7 "Not available" ;
VAL_ 2566746622 TractorBrakeStrokeAxle5Left 0 "OK (Normal operation)" 1 "Non-functioning" 2 "Overstroke" 3 "Dragging brake" 4 "Reserved" 5 "Reserved" 6 "Sensor error" 7 "Not available" ;
VAL_ 2566746622 TractorBrakeStrokeAxle5Right 0 "OK (Normal operation)" 1 "Non-functioning" 2 "Overstroke" 3 "Dragging brake" 4 "Reserved" 5 "Reserved" 6 "Sensor error" 7 "Not available" ;
VAL_ 2566746622 TrailerBrakeStrokeAxle1Left 0 "OK (Normal operation)" 1 "Non-functioning" 2 "Overstroke" 3 "Dragging brake" 4 "Reserved" 5 "Reserved" 6 "Sensor error" 7 "Not available" ;
VAL_ 2566746622 TrailerBrakeStrokeAxle1Right 0 "OK (Normal operation)" 1 "Non-functioning" 2 "Overstroke" 3 "Dragging brake" 4 "Reserved" 5 "Reserved" 6 "Sensor error" 7 "Not available" ;
VAL_ 2566746622 TrailerBrakeStrokeAxle2Left 0 "OK (Normal operation)" 1 "Non-functioning" 2 "Overstroke" 3 "Dragging brake" 4 "Reserved" 5 "Reserved" 6 "Sensor error" 7 "Not available" ;
VAL_ 2566746622 TrailerBrakeStrokeAxle2Right 0 "OK (Normal operation)" 1 "Non-functioning" 2 "Overstroke" 3 "Dragging brake" 4 "Reserved" 5 "Reserved" 6 "Sensor error" 7 "Not available" ;
VAL_ 2566746622 TrailerBrakeStrokeAxle3Left 0 "OK (Normal operation)" 1 "Non-functioning" 2 "Overstroke" 3 "Dragging brake" 4 "Reserved" 5 "Reserved" 6 "Sensor error" 7 "Not available" ;
VAL_ 2566746622 TrailerBrakeStrokeAxle3Right 0 "OK (Normal operation)" 1 "Non-functioning" 2 "Overstroke" 3 "Dragging brake" 4 "Reserved" 5 "Reserved" 6 "Sensor error" 7 "Not available" ;
VAL_ 2566746622 TrailerBrakeStrokeAxle4Left 0 "OK (Normal operation)" 1 "Non-functioning" 2 "Overstroke" 3 "Dragging brake" 4 "Reserved" 5 "Reserved" 6 "Sensor error" 7 "Not available" ;
VAL_ 2566746622 TrailerBrakeStrokeAxle4Right 0 "OK (Normal operation)" 1 "Non-functioning" 2 "Overstroke" 3 "Dragging brake" 4 "Reserved" 5 "Reserved" 6 "Sensor error" 7 "Not available" ;
VAL_ 2566746622 TrailerBrakeStrokeAxle5Left 0 "OK (Normal operation)" 1 "Non-functioning" 2 "Overstroke" 3 "Dragging brake" 4 "Reserved" 5 "Reserved" 6 "Sensor error" 7 "Not available" ;
VAL_ 2566746622 TrailerBrakeStrokeAxle5Right 0 "OK (Normal operation)" 1 "Non-functioning" 2 "Overstroke" 3 "Dragging brake" 4 "Reserved" 5 "Reserved" 6 "Sensor error" 7 "Not available" ;
VAL_ 2566749438 DieselParticulateFilterLampCmd 0 "Off" 1 "On - solid" 2 "reserved for SAE assignment" 3 "reserved for SAE assignment" 4 "On - fast blink (1 Hz)" 5 "On - very fast blink" 6 "reserved for SAE assignment" 7 "not available" ;
VAL_ 2566749438 DslPFActvRegenAvailabilityStatus 0 "Not ready for initiation" 1 "Ready for initiation" 2 "Reserved" 3 "Not Available" ;
VAL_ 2566749438 AftrtrtmntDslPFPassiveRegenStat 0 "Not active" 1 "Active" 2 "Reserved for SAE assignment" 3 "Not available" ;
VAL_ 2566749438 AftrtrtmntDslPFActvRegenStatus 0 "not active" 1 "active" 2 "regeneration needed" 3 "not available" ;
VAL_ 2566749438 AftrtrtmntDslPFStatus 0 "Regeneration not needed" 1 "Regeneration needed - lowest level" 2 "Regeneration needed - moderate level" 3 "Regeneration needed - highest level" 4 "reserved for SAE assignment" 5 "reserved for SAE assignment" 6 "reserved for SAE assignment" 7 "not available" ;
VAL_ 2566749438 DslPFActvRegenInhbtdStatus 0 "Not Inhibited" 1 "Inhibited" 2 "Reserved for SAE assignment" 3 "Not Available" ;
VAL_ 2566749438 DslPFActvRegenInhbtdDTInhbtSw 0 "Not Inhibited" 1 "Inhibited" 2 "Reserved for SAE assignment" 3 "Not Available" ;
VAL_ 2566749438 DslPFActRegenInhbtdDTCltchDiseng 0 "Not Inhibited" 1 "Inhibited" 2 "Reserved for SAE assignment" 3 "Not Available" ;
VAL_ 2566749438 DslPFActRegenInhbtdDTSrvcBrkActv 0 "Not Inhibited" 1 "Inhibited" 2 "Reserved for SAE assignment" 3 "Not Available" ;
VAL_ 2566749438 DslPFActvRegenInhbtdDTPTOActv 0 "Not Inhibited" 1 "Inhibited" 2 "Reserved for SAE assignment" 3 "Not Available" ;
VAL_ 2566749438 DPFActRegenInhbtdDTAcclPdlOffIdl 0 "Not Inhibited" 1 "Inhibited" 2 "Reserved for SAE assignment" 3 "Not Available" ;
VAL_ 2566749438 DslPFActvRegenInhbtdDTOutOfNtrl 0 "Not Inhibited" 1 "Inhibited" 2 "Reserved for SAE assignment" 3 "Not Available" ;
VAL_ 2566749438 DPFActRegInhDTVhclSpdAbvAllwdSpd 0 "Not Inhibited" 1 "Inhibited" 2 "Reserved for SAE assignment" 3 "Not Available" ;
VAL_ 2566749438 DPFActRegenInhbtdDTPrkBrkNotSet 0 "Not Inhibited" 1 "Inhibited" 2 "Reserved for SAE assignment" 3 "Not Available" ;
VAL_ 2566749438 DPFActRegenInhbtdDTLowExhstTemp 0 "Not Inhibited" 1 "Inhibited" 2 "Reserved for SAE assignment" 3 "Not Available" ;
VAL_ 2566749438 DslPFActRegenInhbtdDTSysFaultAct 0 "Not Inhibited" 1 "Inhibited" 2 "Reserved for SAE assignment" 3 "Not Available" ;
VAL_ 2566749438 DslPFActvRegenInhbtdDTSysTimeout 0 "Not Inhibited" 1 "Inhibited" 2 "Reserved for SAE assignment" 3 "Not Available" ;
VAL_ 2566749438 DPFActRegenInhbtdDTTmprySysLckt 0 "Not Inhibited" 1 "Inhibited" 2 "Reserved for SAE assignment" 3 "Not Available" ;
VAL_ 2566749438 DPFActRegenInhbtdDTPrmntSysLckt 0 "Not Inhibited" 1 "Inhibited" 2 "Reserved for SAE assignment" 3 "Not Available" ;
VAL_ 2566749438 DPFActRegInhbtdDTEngNotWarmedUp 0 "Not Inhibited" 1 "Inhibited" 2 "Reserved for SAE assignment" 3 "Not Available" ;
VAL_ 2566749438 DPFActRegInhDTVhclSpdBlwAllwdSpd 0 "Not Inhibited" 1 "Inhibited" 2 "Reserved for SAE assignment" 3 "Not Available" ;
VAL_ 2566749438 DslPFAutoActvRegenInitConf 0 "not enabled" 1 "enabled" 2 "reserved for SAE assignment" 3 "not available" ;
VAL_ 2566749438 ExhstSystemHghTemperatureLampCmd 0 "Off" 1 "On - solid" 2 "reserved for SAE assignment" 3 "reserved for SAE assignment" 4 "reserved for SAE assignment" 5 "reserved for SAE assignment" 6 "reserved for SAE assignment" 7 "not available" ;
VAL_ 2566749438 DslPFActvRegenForcedStatus 0 "Not Active" 1 "Active - Forced by Switch (See SPN 3696)" 2 "Active - Forced by Service Tool" 3 "Reserved for SAE Assignment" 4 "Reserved for SAE Assignment" 5 "Reserved for SAE Assignment" 6 "Reserved for SAE Assignment" 7 "not available" ;
VAL_ 2566749438 HydrocarbonDoserPurgingEnable 0 "Purging not enabled" 1 "Purging enabled" 2 "Purging enabled" 3 "Not available" ;
VAL_ 2566749438 DPFActRegenInhbtdDTLowExhstPress 0 "Not Inhibited" 1 "Inhibited" 2 "Reserved for SAE assignment" 3 "Not Available" ;
VAL_ 2566749438 Aft1DPFConditionsNotMetForActReg 0 "active DPF regeneration not inhibited" 1 "active DPF regeneration inhibited" 2 "reserved for SAE assignment" 3 "not available" ;
VAL_ 2566749438 DslPrtcltFlActRegenInhDTThresher 0 "Not inhibited" 1 "Inhibited" 2 "Reserved" 3 "Not available" ;
VAL_ 2566749950 LeftHeadlampDynamicBendingLight 0 "Dynamic bending light deactivated" 1 "Dynamic bending light is working properly" 2 "Dynamic bending light fail safe position" 3 "Dynamic bending light failure" 4 "Reserved" 7 "Not available" ;
VAL_ 2566749950 RightHeadlampDynamicBendingLight 0 "Dynamic bending light deactivated" 1 "Dynamic bending light is working properly" 2 "Dynamic bending light fail safe position" 3 "Dynamic bending light failure" 4 "Reserved" 7 "Not available" ;
VAL_ 2566749950 LeftHeadlampLightDistribution 0 "Light distribution town" 1 "Light distribution country" 2 "Light distribution motorway" 3 "Light distribution high beam" 4 "Light distribution adverse weather" 5 "Light distribution fail safe position" 6 "Light distribution failure" 7 "Different light distributions not available" 8 "Reserved" 15 "Not available" ;
VAL_ 2566749950 RightHeadlampLightDistribution 0 "Light distribution town" 1 "Light distribution country" 2 "Light distribution motorway" 3 "Light distribution high beam" 4 "Light distribution adverse weather" 5 "Light distribution fail safe position" 6 "Light distribution failure" 7 "Different light distributions not available" 8 "Reserved" 15 "Not available" ;
VAL_ 2566750206 TrnsmIdlGvrnrFuelngInhbtSupp 0 "The engine does not support the 'Transmission Idle Governor Fueling Inhibit'" 1 "The engine will respond to a 'Transmission Idle Governor Fueling Inhibit' command from the Transmission, should it be received" 2 "Reserved for future SAE use" 3 "Not supported" ;
VAL_ 2566750462 ProtectLamp 0 "Lamp Off" 1 "Lamp On" 2 "Reserved" 3 "Not available" ;
VAL_ 2566750462 AmberWarningLamp 0 "Lamp Off" 1 "Lamp On" 2 "Reserved" 3 "Not available" ;
VAL_ 2566750462 RedStopLamp 0 "Lamp Off" 1 "Lamp On" 2 "Reserved" 3 "Not available" ;
VAL_ 2566750462 MalfunctionIndicatorLamp 0 "Lamp Off" 1 "Lamp On" 2 "Short MIL for WWH OBD" 3 "Not available" ;
VAL_ 2566750462 FlashProtectLamp 0 "Slow Flash (1 Hz, 50 % duty cycle)" 1 "Fast Flash (2 Hz or faster, 50% duty cycle)" 2 "Reserved" 3 "Unavailable / Do Not Flash" ;
VAL_ 2566750462 FlashAmberWarningLamp 0 "Slow Flash (1 Hz, 50 % duty cycle)" 1 "Fast Flash (2 Hz or faster, 50% duty cycle)" 2 "Reserved" 3 "Unavailable / Do Not Flash" ;
VAL_ 2566750462 FlashRedStopLamp 0 "Slow Flash (1 Hz, 50 % duty cycle)" 1 "Fast Flash (2 Hz or faster, 50% duty cycle)" 2 "Reserved" 3 "Unavailable / Do Not Flash" ;
VAL_ 2566750462 FlashMalfunctionIndicatorLamp 0 "Slow Flash (1 Hz, 50 % duty cycle)" 1 "Fast Flash (2 Hz or faster, 50% duty cycle)" 2 "Class C DTC" 3 "Unavailable / Do Not Flash" ;
VAL_ 2566750462 SPNConversionMethod 0 "Convert SPN per Version 4" 1 "Convert SPN per Version 1, 2 or 3" ;
VAL_ 2566750974 ProtectLamp 0 "Lamp Off" 1 "Lamp On" 2 "Reserved" 3 "Not available" ;
VAL_ 2566750974 AmberWarningLamp 0 "Lamp Off" 1 "Lamp On" 2 "Reserved" 3 "Not available" ;
VAL_ 2566750974 RedStopLamp 0 "Lamp Off" 1 "Lamp On" 2 "Reserved" 3 "Not available" ;
VAL_ 2566750974 MalfunctionIndicatorLamp 0 "Lamp Off" 1 "Lamp On" 2 "Short MIL for WWH OBD" 3 "Not available" ;
VAL_ 2566750974 FlashProtectLamp 0 "Slow Flash (1 Hz, 50 % duty cycle)" 1 "Fast Flash (2 Hz or faster, 50% duty cycle)" 2 "Reserved" 3 "Unavailable / Do Not Flash" ;
VAL_ 2566750974 FlashAmberWarningLamp 0 "Slow Flash (1 Hz, 50 % duty cycle)" 1 "Fast Flash (2 Hz or faster, 50% duty cycle)" 2 "Reserved" 3 "Unavailable / Do Not Flash" ;
VAL_ 2566750974 FlashRedStopLamp 0 "Slow Flash (1 Hz, 50 % duty cycle)" 1 "Fast Flash (2 Hz or faster, 50% duty cycle)" 2 "Reserved" 3 "Unavailable / Do Not Flash" ;
VAL_ 2566750974 FlashMalfunctionIndicatorLamp 0 "Slow Flash (1 Hz, 50 % duty cycle)" 1 "Fast Flash (2 Hz or faster, 50% duty cycle)" 2 "Class C DTC" 3 "Unavailable / Do Not Flash" ;
VAL_ 2566750974 SPNConversionMethod 0 "Convert SPN per Version 4" 1 "Convert SPN per Version 1, 2 or 3" ;
VAL_ 2566751230 TransferCaseStatus 0 "2 wheel high" 1 "4 wheel high" 2 "Neutral" 3 "2 wheel low" 4 "4 wheel low" 5 "Transfer Case Shift in Progress" 6 "Error" 7 "Not available" ;
VAL_ 2566751230 TransferCaseDirectionStatus 0 "Forward" 1 "Reverse" 2 "Error" 3 "Not Available" ;
